VERSION "canboat-NMEA2000-curated"

NS_ :

BS_:

BU_: Vector__XXX
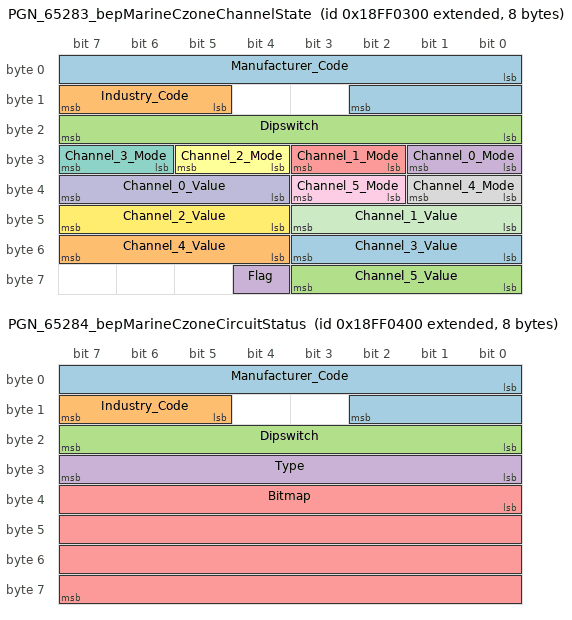
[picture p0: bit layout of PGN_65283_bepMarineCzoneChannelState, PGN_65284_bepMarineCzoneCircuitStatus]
BO_ 2566849280 PGN_65283_bepMarineCzoneChannelState: 8 Vector__XXX
 SG_ Manufacturer_Code : 0|11@1+ (1.0,0) [0|2047] "" Vector__XXX
 SG_ Industry_Code : 13|3@1+ (1.0,0) [0|7] "" Vector__XXX
 SG_ Dipswitch : 16|8@1+ (1.0,0) [0|255] "" Vector__XXX
 SG_ Channel_0_Mode : 24|2@1+ (1.0,0) [0|3] "" Vector__XXX
 SG_ Channel_1_Mode : 26|2@1+ (1.0,0) [0|3] "" Vector__XXX
 SG_ Channel_2_Mode : 28|2@1+ (1.0,0) [0|3] "" Vector__XXX
 SG_ Channel_3_Mode : 30|2@1+ (1.0,0) [0|3] "" Vector__XXX
 SG_ Channel_4_Mode : 32|2@1+ (1.0,0) [0|3] "" Vector__XXX
 SG_ Channel_5_Mode : 34|2@1+ (1.0,0) [0|3] "" Vector__XXX
 SG_ Channel_0_Value : 36|4@1+ (1.0,0) [0|15] "" Vector__XXX
 SG_ Channel_1_Value : 40|4@1+ (1.0,0) [0|15] "" Vector__XXX
 SG_ Channel_2_Value : 44|4@1+ (1.0,0) [0|15] "" Vector__XXX
 SG_ Channel_3_Value : 48|4@1+ (1.0,0) [0|15] "" Vector__XXX
 SG_ Channel_4_Value : 52|4@1+ (1.0,0) [0|15] "" Vector__XXX
 SG_ Channel_5_Value : 56|4@1+ (1.0,0) [0|15] "" Vector__XXX
 SG_ Flag : 60|1@1+ (1.0,0) [0|1] "" Vector__XXX

BO_ 2566849536 PGN_65284_bepMarineCzoneCircuitStatus: 8 Vector__XXX
 SG_ Manufacturer_Code : 0|11@1+ (1.0,0) [0|2047] "" Vector__XXX
 SG_ Industry_Code : 13|3@1+ (1.0,0) [0|7] "" Vector__XXX
 SG_ Dipswitch : 16|8@1+ (1.0,0) [0|255] "" Vector__XXX
 SG_ Type : 24|8@1+ (1.0,0) [0|255] "" Vector__XXX
 SG_ Bitmap : 32|32@1+ (1.0,0) [0|4294967295] "" Vector__XXX

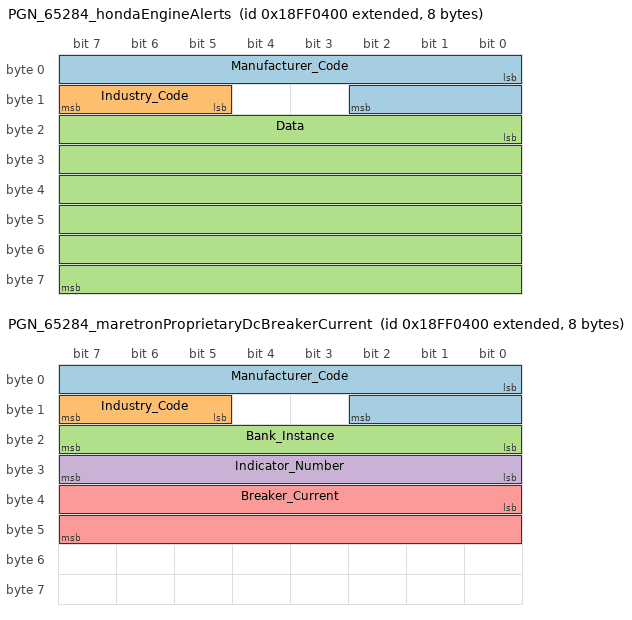
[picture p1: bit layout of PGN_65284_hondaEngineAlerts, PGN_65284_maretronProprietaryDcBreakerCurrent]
BO_ 2566849536 PGN_65284_hondaEngineAlerts: 8 Vector__XXX
 SG_ Manufacturer_Code : 0|11@1+ (1.0,0) [0|2047] "" Vector__XXX
 SG_ Industry_Code : 13|3@1+ (1.0,0) [0|7] "" Vector__XXX
 SG_ Data : 16|48@1+ (1.0,0) [0|281474976710655] "" Vector__XXX

BO_ 2566849536 PGN_65284_maretronProprietaryDcBreakerCurrent: 8 Vector__XXX
 SG_ Manufacturer_Code : 0|11@1+ (1.0,0) [0|2047] "" Vector__XXX
 SG_ Industry_Code : 13|3@1+ (1.0,0) [0|7] "" Vector__XXX
 SG_ Bank_Instance : 16|8@1+ (1.0,0) [0|255] "" Vector__XXX
 SG_ Indicator_Number : 24|8@1+ (1.0,0) [0|255] "" Vector__XXX
 SG_ Breaker_Current : 32|16@1- (0.1,0) [-3276.8|3276.7000000000003] "" Vector__XXX

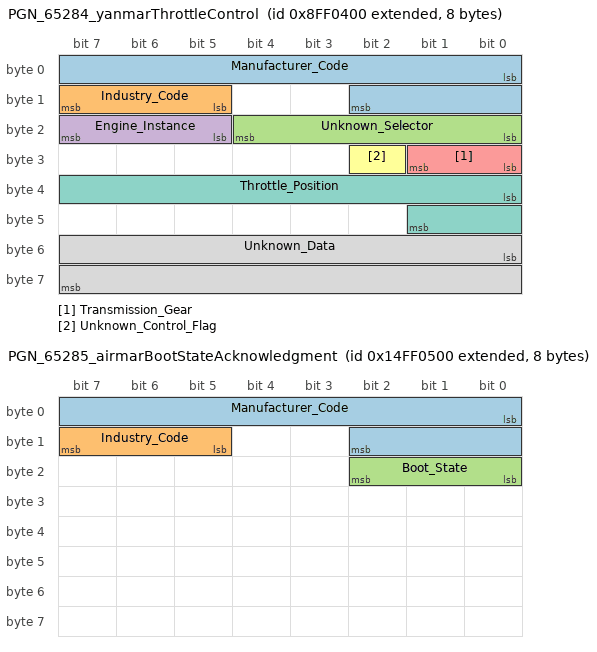
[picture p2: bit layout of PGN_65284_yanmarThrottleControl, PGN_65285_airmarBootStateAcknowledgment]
BO_ 2298414080 PGN_65284_yanmarThrottleControl: 8 Vector__XXX
 SG_ Manufacturer_Code : 0|11@1+ (1.0,0) [0|2047] "" Vector__XXX
 SG_ Industry_Code : 13|3@1+ (1.0,0) [0|7] "" Vector__XXX
 SG_ Unknown_Selector : 16|5@1+ (1.0,0) [0|31] "" Vector__XXX
 SG_ Engine_Instance : 21|3@1+ (1.0,0) [0|7] "" Vector__XXX
 SG_ Transmission_Gear : 24|2@1+ (1.0,0) [0|3] "" Vector__XXX
 SG_ Unknown_Control_Flag : 26|1@1+ (1.0,0) [0|1] "" Vector__XXX
 SG_ Throttle_Position : 32|10@1+ (0.1,0) [0.0|102.30000000000001] "%" Vector__XXX
 SG_ Unknown_Data : 48|16@1+ (1.0,0) [0|65535] "" Vector__XXX

BO_ 2499740928 PGN_65285_airmarBootStateAcknowledgment: 8 Vector__XXX
 SG_ Manufacturer_Code : 0|11@1+ (1.0,0) [0|2047] "" Vector__XXX
 SG_ Industry_Code : 13|3@1+ (1.0,0) [0|7] "" Vector__XXX
 SG_ Boot_State : 16|3@1+ (1.0,0) [0|7] "" Vector__XXX

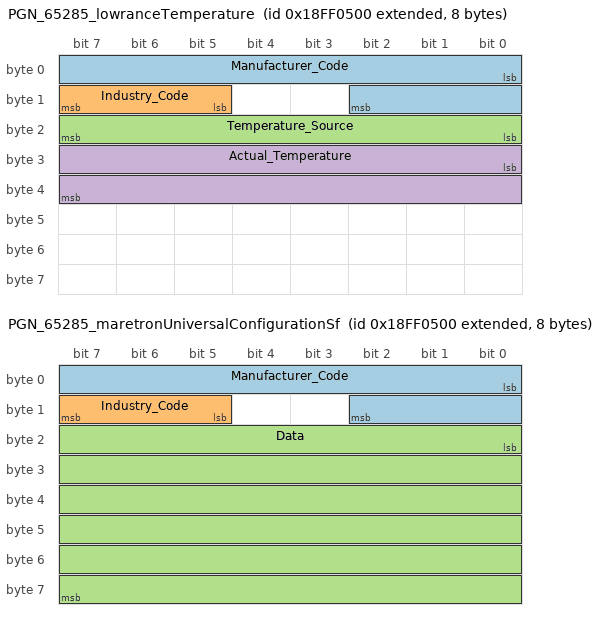
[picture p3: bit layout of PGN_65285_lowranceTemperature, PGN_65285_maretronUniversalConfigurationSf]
BO_ 2566849792 PGN_65285_lowranceTemperature: 8 Vector__XXX
 SG_ Manufacturer_Code : 0|11@1+ (1.0,0) [0|2047] "" Vector__XXX
 SG_ Industry_Code : 13|3@1+ (1.0,0) [0|7] "" Vector__XXX
 SG_ Temperature_Source : 16|8@1+ (1.0,0) [0|255] "" Vector__XXX
 SG_ Actual_Temperature : 24|16@1+ (0.01,0) [0.0|655.35] "" Vector__XXX

BO_ 2566849792 PGN_65285_maretronUniversalConfigurationSf: 8 Vector__XXX
 SG_ Manufacturer_Code : 0|11@1+ (1.0,0) [0|2047] "" Vector__XXX
 SG_ Industry_Code : 13|3@1+ (1.0,0) [0|7] "" Vector__XXX
 SG_ Data : 16|48@1+ (1.0,0) [0|281474976710655] "" Vector__XXX

BO_ 2566850048 PGN_65286_airmarBootStateRequest: 8 Vector__XXX
 SG_ Manufacturer_Code : 0|11@1+ (1.0,0) [0|2047] "" Vector__XXX
 SG_ Industry_Code : 13|3@1+ (1.0,0) [0|7] "" Vector__XXX

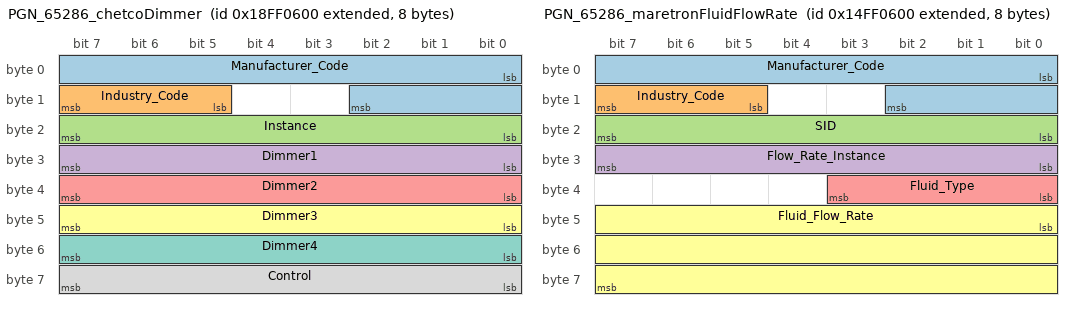
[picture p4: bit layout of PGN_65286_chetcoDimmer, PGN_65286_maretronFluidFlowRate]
BO_ 2566850048 PGN_65286_chetcoDimmer: 8 Vector__XXX
 SG_ Manufacturer_Code : 0|11@1+ (1.0,0) [0|2047] "" Vector__XXX
 SG_ Industry_Code : 13|3@1+ (1.0,0) [0|7] "" Vector__XXX
 SG_ Instance : 16|8@1+ (1.0,0) [0|255] "" Vector__XXX
 SG_ Dimmer1 : 24|8@1+ (1.0,0) [0|255] "" Vector__XXX
 SG_ Dimmer2 : 32|8@1+ (1.0,0) [0|255] "" Vector__XXX
 SG_ Dimmer3 : 40|8@1+ (1.0,0) [0|255] "" Vector__XXX
 SG_ Dimmer4 : 48|8@1+ (1.0,0) [0|255] "" Vector__XXX
 SG_ Control : 56|8@1+ (1.0,0) [0|255] "" Vector__XXX

BO_ 2499741184 PGN_65286_maretronFluidFlowRate: 8 Vector__XXX
 SG_ Manufacturer_Code : 0|11@1+ (1.0,0) [0|2047] "" Vector__XXX
 SG_ Industry_Code : 13|3@1+ (1.0,0) [0|7] "" Vector__XXX
 SG_ SID : 16|8@1+ (1.0,0) [0|255] "" Vector__XXX
 SG_ Flow_Rate_Instance : 24|8@1+ (1.0,0) [0|255] "" Vector__XXX
 SG_ Fluid_Type : 32|4@1+ (1.0,0) [0|15] "" Vector__XXX
 SG_ Fluid_Flow_Rate : 40|24@1- (0.0001,0) [-838.8608|838.8607000000001] "" Vector__XXX

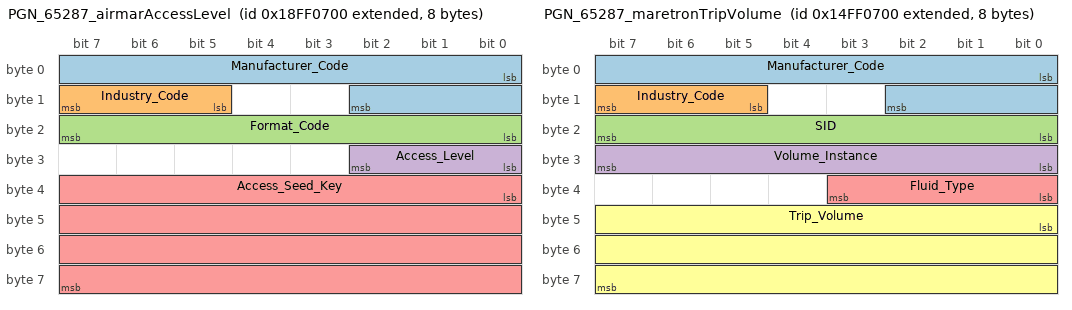
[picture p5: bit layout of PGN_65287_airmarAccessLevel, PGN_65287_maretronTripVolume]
BO_ 2566850304 PGN_65287_airmarAccessLevel: 8 Vector__XXX
 SG_ Manufacturer_Code : 0|11@1+ (1.0,0) [0|2047] "" Vector__XXX
 SG_ Industry_Code : 13|3@1+ (1.0,0) [0|7] "" Vector__XXX
 SG_ Format_Code : 16|8@1+ (1.0,0) [0|255] "" Vector__XXX
 SG_ Access_Level : 24|3@1+ (1.0,0) [0|7] "" Vector__XXX
 SG_ Access_Seed_Key : 32|32@1+ (1.0,0) [0|4294967295] "" Vector__XXX

BO_ 2499741440 PGN_65287_maretronTripVolume: 8 Vector__XXX
 SG_ Manufacturer_Code : 0|11@1+ (1.0,0) [0|2047] "" Vector__XXX
 SG_ Industry_Code : 13|3@1+ (1.0,0) [0|7] "" Vector__XXX
 SG_ SID : 16|8@1+ (1.0,0) [0|255] "" Vector__XXX
 SG_ Volume_Instance : 24|8@1+ (1.0,0) [0|255] "" Vector__XXX
 SG_ Fluid_Type : 32|4@1+ (1.0,0) [0|15] "" Vector__XXX
 SG_ Trip_Volume : 40|24@1+ (0.001,0) [0.0|16777.215] "" Vector__XXX

BO_ 2566850304 PGN_65287_simnetConfigureTemperatureSensor: 8 Vector__XXX
 SG_ Manufacturer_Code : 0|11@1+ (1.0,0) [0|2047] "" Vector__XXX
 SG_ Industry_Code : 13|3@1+ (1.0,0) [0|7] "" Vector__XXX

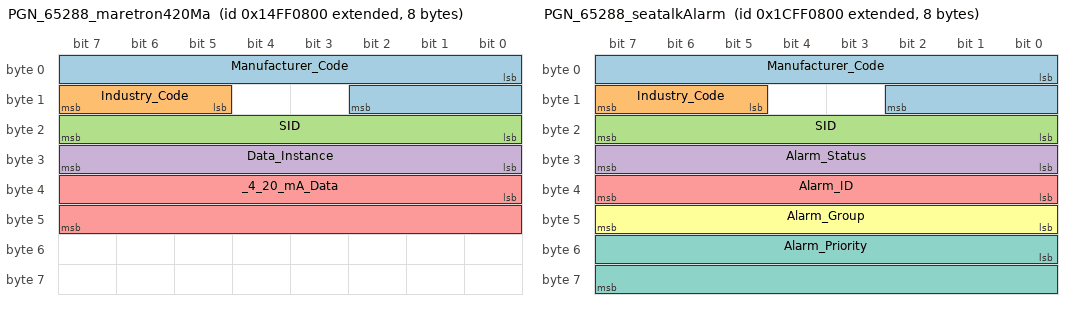
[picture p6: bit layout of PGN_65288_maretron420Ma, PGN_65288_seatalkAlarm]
BO_ 2499741696 PGN_65288_maretron420Ma: 8 Vector__XXX
 SG_ Manufacturer_Code : 0|11@1+ (1.0,0) [0|2047] "" Vector__XXX
 SG_ Industry_Code : 13|3@1+ (1.0,0) [0|7] "" Vector__XXX
 SG_ SID : 16|8@1+ (1.0,0) [0|255] "" Vector__XXX
 SG_ Data_Instance : 24|8@1+ (1.0,0) [0|255] "" Vector__XXX
 SG_ _4_20_mA_Data : 32|16@1+ (1.0,0) [0|65535] "" Vector__XXX

BO_ 2633959424 PGN_65288_seatalkAlarm: 8 Vector__XXX
 SG_ Manufacturer_Code : 0|11@1+ (1.0,0) [0|2047] "" Vector__XXX
 SG_ Industry_Code : 13|3@1+ (1.0,0) [0|7] "" Vector__XXX
 SG_ SID : 16|8@1+ (1.0,0) [0|255] "" Vector__XXX
 SG_ Alarm_Status : 24|8@1+ (1.0,0) [0|255] "" Vector__XXX
 SG_ Alarm_ID : 32|8@1+ (1.0,0) [0|255] "" Vector__XXX
 SG_ Alarm_Group : 40|8@1+ (1.0,0) [0|255] "" Vector__XXX
 SG_ Alarm_Priority : 48|16@1+ (1.0,0) [0|65535] "" Vector__XXX

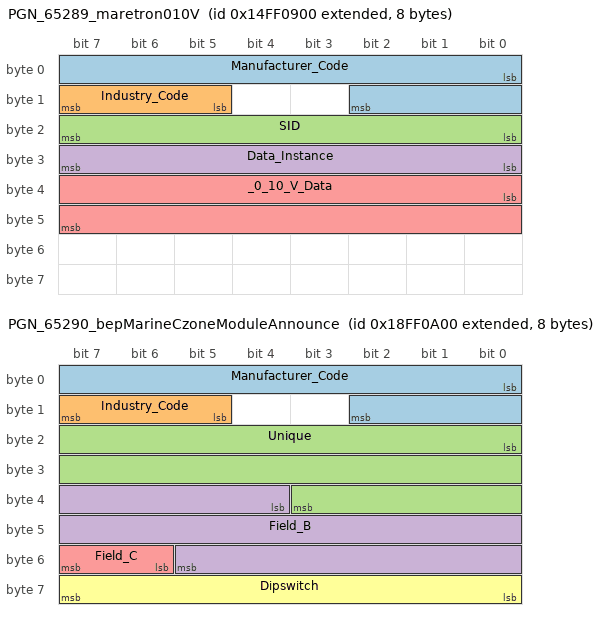
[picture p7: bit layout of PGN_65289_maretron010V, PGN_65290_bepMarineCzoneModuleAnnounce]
BO_ 2499741952 PGN_65289_maretron010V: 8 Vector__XXX
 SG_ Manufacturer_Code : 0|11@1+ (1.0,0) [0|2047] "" Vector__XXX
 SG_ Industry_Code : 13|3@1+ (1.0,0) [0|7] "" Vector__XXX
 SG_ SID : 16|8@1+ (1.0,0) [0|255] "" Vector__XXX
 SG_ Data_Instance : 24|8@1+ (1.0,0) [0|255] "" Vector__XXX
 SG_ _0_10_V_Data : 32|16@1+ (0.000244140625,0) [0.0|15.999755859375] "" Vector__XXX

BO_ 2566850816 PGN_65289_simnetTrimTabSensorCalibration: 8 Vector__XXX
 SG_ Manufacturer_Code : 0|11@1+ (1.0,0) [0|2047] "" Vector__XXX
 SG_ Industry_Code : 13|3@1+ (1.0,0) [0|7] "" Vector__XXX

BO_ 2566851072 PGN_65290_bepMarineCzoneModuleAnnounce: 8 Vector__XXX
 SG_ Manufacturer_Code : 0|11@1+ (1.0,0) [0|2047] "" Vector__XXX
 SG_ Industry_Code : 13|3@1+ (1.0,0) [0|7] "" Vector__XXX
 SG_ Unique : 16|20@1+ (1.0,0) [0|1048575] "" Vector__XXX
 SG_ Field_B : 36|18@1+ (1.0,0) [0|262143] "" Vector__XXX
 SG_ Field_C : 54|2@1+ (1.0,0) [0|3] "" Vector__XXX
 SG_ Dipswitch : 56|8@1+ (1.0,0) [0|255] "" Vector__XXX

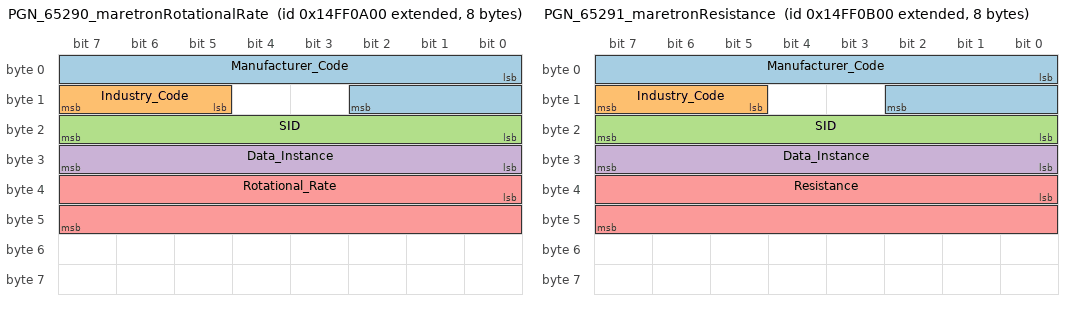
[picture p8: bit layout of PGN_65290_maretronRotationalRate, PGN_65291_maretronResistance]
BO_ 2499742208 PGN_65290_maretronRotationalRate: 8 Vector__XXX
 SG_ Manufacturer_Code : 0|11@1+ (1.0,0) [0|2047] "" Vector__XXX
 SG_ Industry_Code : 13|3@1+ (1.0,0) [0|7] "" Vector__XXX
 SG_ SID : 16|8@1+ (1.0,0) [0|255] "" Vector__XXX
 SG_ Data_Instance : 24|8@1+ (1.0,0) [0|255] "" Vector__XXX
 SG_ Rotational_Rate : 32|16@1- (0.25,0) [-8192.0|8191.75] "" Vector__XXX

BO_ 2566851072 PGN_65290_simnetPaddleWheelSpeedConfiguration: 8 Vector__XXX
 SG_ Manufacturer_Code : 0|11@1+ (1.0,0) [0|2047] "" Vector__XXX
 SG_ Industry_Code : 13|3@1+ (1.0,0) [0|7] "" Vector__XXX

BO_ 2499742464 PGN_65291_maretronResistance: 8 Vector__XXX
 SG_ Manufacturer_Code : 0|11@1+ (1.0,0) [0|2047] "" Vector__XXX
 SG_ Industry_Code : 13|3@1+ (1.0,0) [0|7] "" Vector__XXX
 SG_ SID : 16|8@1+ (1.0,0) [0|255] "" Vector__XXX
 SG_ Data_Instance : 24|8@1+ (1.0,0) [0|255] "" Vector__XXX
 SG_ Resistance : 32|16@1+ (0.01,0) [0.0|655.35] "" Vector__XXX

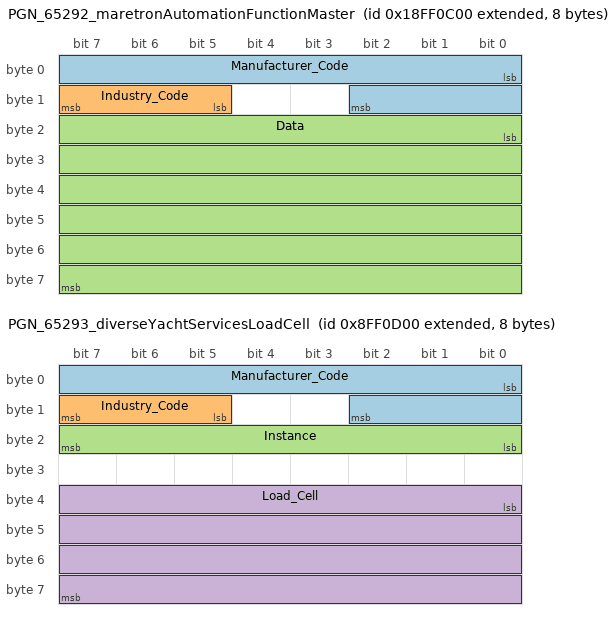
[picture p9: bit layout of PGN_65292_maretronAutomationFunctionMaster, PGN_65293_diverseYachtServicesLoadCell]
BO_ 2566851584 PGN_65292_maretronAutomationFunctionMaster: 8 Vector__XXX
 SG_ Manufacturer_Code : 0|11@1+ (1.0,0) [0|2047] "" Vector__XXX
 SG_ Industry_Code : 13|3@1+ (1.0,0) [0|7] "" Vector__XXX
 SG_ Data : 16|48@1+ (1.0,0) [0|281474976710655] "" Vector__XXX

BO_ 2566851584 PGN_65292_simnetClearFluidLevelWarnings: 8 Vector__XXX
 SG_ Manufacturer_Code : 0|11@1+ (1.0,0) [0|2047] "" Vector__XXX
 SG_ Industry_Code : 13|3@1+ (1.0,0) [0|7] "" Vector__XXX

BO_ 2298416384 PGN_65293_diverseYachtServicesLoadCell: 8 Vector__XXX
 SG_ Manufacturer_Code : 0|11@1+ (1.0,0) [0|2047] "" Vector__XXX
 SG_ Industry_Code : 13|3@1+ (1.0,0) [0|7] "" Vector__XXX
 SG_ Instance : 16|8@1+ (1.0,0) [0|255] "" Vector__XXX
 SG_ Load_Cell : 32|32@1+ (1.0,0) [0|4294967295] "" Vector__XXX

CM_ BO_ 2566849280 "NMEA2000: PGN 65283 - BEP Marine: CZone Channel State (type: Single)";
CM_ BO_ 2566849536 "NMEA2000: PGN 65284 - BEP Marine: CZone Circuit Status (type: Single)";
CM_ BO_ 2566849536 "NMEA2000: PGN 65284 - Honda: Engine Alerts (type: Single)";
CM_ BO_ 2566849536 "NMEA2000: PGN 65284 - Maretron: Proprietary DC Breaker Current (type: Single)";
CM_ BO_ 2298414080 "NMEA2000: PGN 65284 - Yanmar: Throttle Control (type: Single)";
CM_ BO_ 2499740928 "NMEA2000: PGN 65285 - Airmar: Boot State Acknowledgment (type: Single)";
CM_ BO_ 2566849792 "NMEA2000: PGN 65285 - Lowrance: Temperature (type: Single)";
CM_ BO_ 2566849792 "NMEA2000: PGN 65285 - Maretron: Universal Configuration SF (type: Single)";
CM_ BO_ 2566850048 "NMEA2000: PGN 65286 - Airmar: Boot State Request (type: Single)";
CM_ BO_ 2566850048 "NMEA2000: PGN 65286 - Chetco: Dimmer (type: Single)";
CM_ BO_ 2499741184 "NMEA2000: PGN 65286 - Maretron: Fluid Flow Rate (type: Single)";
CM_ BO_ 2566850304 "NMEA2000: PGN 65287 - Airmar: Access Level (type: Single)";
CM_ BO_ 2499741440 "NMEA2000: PGN 65287 - Maretron: Trip Volume (type: Single)";
CM_ BO_ 2566850304 "NMEA2000: PGN 65287 - Simnet: Configure Temperature Sensor (type: Single)";
CM_ BO_ 2499741696 "NMEA2000: PGN 65288 - Maretron: 4-20 mA (type: Single)";
CM_ BO_ 2633959424 "NMEA2000: PGN 65288 - Seatalk: Alarm (type: Single)";
CM_ BO_ 2499741952 "NMEA2000: PGN 65289 - Maretron: 0-10 V (type: Single)";
CM_ BO_ 2566850816 "NMEA2000: PGN 65289 - Simnet: Trim Tab Sensor Calibration (type: Single)";
CM_ BO_ 2566851072 "NMEA2000: PGN 65290 - BEP Marine: CZone Module Announce (type: Single)";
CM_ BO_ 2499742208 "NMEA2000: PGN 65290 - Maretron: Rotational Rate (type: Single)";
CM_ BO_ 2566851072 "NMEA2000: PGN 65290 - Simnet: Paddle Wheel Speed Configuration (type: Single)";
CM_ BO_ 2499742464 "NMEA2000: PGN 65291 - Maretron: Resistance (type: Single)";
CM_ BO_ 2566851584 "NMEA2000: PGN 65292 - Maretron: Automation Function Master (type: Single)";
CM_ BO_ 2566851584 "NMEA2000: PGN 65292 - Simnet: Clear Fluid Level Warnings (type: Single)";
CM_ BO_ 2298416384 "NMEA2000: PGN 65293 - Diverse Yacht Services: Load Cell (type: Single)";
CM_ SG_ 2566849280 Manufacturer_Code "BEP Marine; canboat type: LOOKUP";
CM_ SG_ 2566849280 Industry_Code "Marine Industry; canboat type: LOOKUP";
CM_ SG_ 2566849280 Dipswitch "canboat type: UINT8";
CM_ SG_ 2566849280 Channel_0_Mode "Likely circuit type / fault state; per-bit semantics unverified; canboat type: UNSIGNED_INTEGER";
CM_ SG_ 2566849280 Channel_1_Mode "Likely circuit type / fault state; per-bit semantics unverified; canboat type: UNSIGNED_INTEGER";
CM_ SG_ 2566849280 Channel_2_Mode "Likely circuit type / fault state; per-bit semantics unverified; canboat type: UNSIGNED_INTEGER";
CM_ SG_ 2566849280 Channel_3_Mode "Likely circuit type / fault state; per-bit semantics unverified; canboat type: UNSIGNED_INTEGER";
CM_ SG_ 2566849280 Channel_4_Mode "Likely circuit type / fault state; per-bit semantics unverified; canboat type: UNSIGNED_INTEGER";
CM_ SG_ 2566849280 Channel_5_Mode "Likely circuit type / fault state; per-bit semantics unverified; canboat type: UNSIGNED_INTEGER";
CM_ SG_ 2566849280 Channel_0_Value "4-bit per-channel value; likely dim level (0..15) or state code; canboat type: UNSIGNED_INTEGER";
CM_ SG_ 2566849280 Channel_1_Value "4-bit per-channel value; likely dim level (0..15) or state code; canboat type: UNSIGNED_INTEGER";
CM_ SG_ 2566849280 Channel_2_Value "4-bit per-channel value; likely dim level (0..15) or state code; canboat type: UNSIGNED_INTEGER";
CM_ SG_ 2566849280 Channel_3_Value "4-bit per-channel value; likely dim level (0..15) or state code; canboat type: UNSIGNED_INTEGER";
CM_ SG_ 2566849280 Channel_4_Value "4-bit per-channel value; likely dim level (0..15) or state code; canboat type: UNSIGNED_INTEGER";
CM_ SG_ 2566849280 Channel_5_Value "4-bit per-channel value; likely dim level (0..15) or state code; canboat type: UNSIGNED_INTEGER";
CM_ SG_ 2566849280 Flag "Single boolean flag; purpose unverified; canboat type: UNSIGNED_INTEGER";
CM_ SG_ 2566849536 Manufacturer_Code "BEP Marine; canboat type: LOOKUP";
CM_ SG_ 2566849536 Industry_Code "Marine Industry; canboat type: LOOKUP";
CM_ SG_ 2566849536 Dipswitch "canboat type: UINT8";
CM_ SG_ 2566849536 Type "Observed 0x0F for circuit-state reports; canboat type: UINT8";
CM_ SG_ 2566849536 Bitmap "32-bit bitmap of circuits, LSB-first; bit n set => circuit at slot n is ON; canboat type: BINARY";
CM_ SG_ 2566849536 Manufacturer_Code "Honda Motor; canboat type: LOOKUP";
CM_ SG_ 2566849536 Industry_Code "Marine Industry; canboat type: LOOKUP";
CM_ SG_ 2566849536 Data "canboat type: BINARY";
CM_ SG_ 2566849536 Manufacturer_Code "Maretron; canboat type: LOOKUP";
CM_ SG_ 2566849536 Industry_Code "Marine Industry; canboat type: LOOKUP";
CM_ SG_ 2566849536 Bank_Instance "canboat type: UINT8";
CM_ SG_ 2566849536 Indicator_Number "canboat type: UINT8";
CM_ SG_ 2566849536 Breaker_Current "canboat type: CURRENT_FIX16_DA";
CM_ SG_ 2298414080 Manufacturer_Code "Yanmar Marine; canboat type: LOOKUP";
CM_ SG_ 2298414080 Industry_Code "Marine Industry; canboat type: LOOKUP";
CM_ SG_ 2298414080 Unknown_Selector "Observed as 1; the individual bit semantics are not yet known.; canboat type: UNSIGNED_INTEGER";
CM_ SG_ 2298414080 Engine_Instance "Uses the standard NMEA 2000 engine-instance values; observed as 0 for port and 1 for starboard.; canboat type: LOOKUP";
CM_ SG_ 2298414080 Transmission_Gear "Observed as Forward, Neutral, and Reverse for the selected engine channel.; canboat type: LOOKUP";
CM_ SG_ 2298414080 Unknown_Control_Flag "Observed as 0 during the gear-transition capture and 1 in earlier underway throttle captures.; canboat type: UNSIGNED_INTEGER";
CM_ SG_ 2298414080 Throttle_Position "Observed control-lever position with 0.1 percent resolution.; canboat type: UNSIGNED_INTEGER";
CM_ SG_ 2298414080 Unknown_Data "Observed as 0x64FF.; canboat type: BINARY";
CM_ SG_ 2499740928 Manufacturer_Code "Airmar; canboat type: LOOKUP";
CM_ SG_ 2499740928 Industry_Code "Marine Industry; canboat type: LOOKUP";
CM_ SG_ 2499740928 Boot_State "canboat type: LOOKUP";
CM_ SG_ 2566849792 Manufacturer_Code "Lowrance; canboat type: LOOKUP";
CM_ SG_ 2566849792 Industry_Code "Marine Industry; canboat type: LOOKUP";
CM_ SG_ 2566849792 Temperature_Source "canboat type: LOOKUP";
CM_ SG_ 2566849792 Actual_Temperature "canboat type: TEMPERATURE";
CM_ SG_ 2566849792 Manufacturer_Code "Maretron; canboat type: LOOKUP";
CM_ SG_ 2566849792 Industry_Code "Marine Industry; canboat type: LOOKUP";
CM_ SG_ 2566849792 Data "canboat type: BINARY";
CM_ SG_ 2566850048 Manufacturer_Code "Airmar; canboat type: LOOKUP";
CM_ SG_ 2566850048 Industry_Code "Marine Industry; canboat type: LOOKUP";
CM_ SG_ 2566850048 Manufacturer_Code "Chetco; canboat type: LOOKUP";
CM_ SG_ 2566850048 Industry_Code "Marine Industry; canboat type: LOOKUP";
CM_ SG_ 2566850048 Instance "canboat type: UINT8";
CM_ SG_ 2566850048 Dimmer1 "canboat type: UINT8";
CM_ SG_ 2566850048 Dimmer2 "canboat type: UINT8";
CM_ SG_ 2566850048 Dimmer3 "canboat type: UINT8";
CM_ SG_ 2566850048 Dimmer4 "canboat type: UINT8";
CM_ SG_ 2566850048 Control "canboat type: UINT8";
CM_ SG_ 2499741184 Manufacturer_Code "Maretron; canboat type: LOOKUP";
CM_ SG_ 2499741184 Industry_Code "Marine Industry; canboat type: LOOKUP";
CM_ SG_ 2499741184 SID "canboat type: UINT8";
CM_ SG_ 2499741184 Flow_Rate_Instance "canboat type: UINT8";
CM_ SG_ 2499741184 Fluid_Type "canboat type: LOOKUP";
CM_ SG_ 2499741184 Fluid_Flow_Rate "canboat type: FIX24";
CM_ SG_ 2566850304 Manufacturer_Code "Airmar; canboat type: LOOKUP";
CM_ SG_ 2566850304 Industry_Code "Marine Industry; canboat type: LOOKUP";
CM_ SG_ 2566850304 Format_Code "canboat type: UINT8";
CM_ SG_ 2566850304 Access_Level "canboat type: LOOKUP";
CM_ SG_ 2566850304 Access_Seed_Key "When transmitted, it provides a seed for an unlock operation. It is used to provide the key during PGN 126208.; canboat type: UINT32";
CM_ SG_ 2499741440 Manufacturer_Code "Maretron; canboat type: LOOKUP";
CM_ SG_ 2499741440 Industry_Code "Marine Industry; canboat type: LOOKUP";
CM_ SG_ 2499741440 SID "canboat type: UINT8";
CM_ SG_ 2499741440 Volume_Instance "canboat type: UINT8";
CM_ SG_ 2499741440 Fluid_Type "canboat type: LOOKUP";
CM_ SG_ 2499741440 Trip_Volume "canboat type: UINT24";
CM_ SG_ 2566850304 Manufacturer_Code "Simrad; canboat type: LOOKUP";
CM_ SG_ 2566850304 Industry_Code "Marine Industry; canboat type: LOOKUP";
CM_ SG_ 2499741696 Manufacturer_Code "Maretron; canboat type: LOOKUP";
CM_ SG_ 2499741696 Industry_Code "Marine Industry; canboat type: LOOKUP";
CM_ SG_ 2499741696 SID "canboat type: UINT8";
CM_ SG_ 2499741696 Data_Instance "canboat type: UINT8";
CM_ SG_ 2499741696 _4_20_mA_Data "canboat type: UINT16";
CM_ SG_ 2633959424 Manufacturer_Code "Raymarine; canboat type: LOOKUP";
CM_ SG_ 2633959424 Industry_Code "Marine Industry; canboat type: LOOKUP";
CM_ SG_ 2633959424 SID "canboat type: UINT8";
CM_ SG_ 2633959424 Alarm_Status "canboat type: LOOKUP";
CM_ SG_ 2633959424 Alarm_ID "canboat type: LOOKUP";
CM_ SG_ 2633959424 Alarm_Group "canboat type: LOOKUP";
CM_ SG_ 2633959424 Alarm_Priority "canboat type: BINARY";
CM_ SG_ 2499741952 Manufacturer_Code "Maretron; canboat type: LOOKUP";
CM_ SG_ 2499741952 Industry_Code "Marine Industry; canboat type: LOOKUP";
CM_ SG_ 2499741952 SID "canboat type: UINT8";
CM_ SG_ 2499741952 Data_Instance "canboat type: UINT8";
CM_ SG_ 2499741952 _0_10_V_Data "canboat type: UINT16";
CM_ SG_ 2566850816 Manufacturer_Code "Simrad; canboat type: LOOKUP";
CM_ SG_ 2566850816 Industry_Code "Marine Industry; canboat type: LOOKUP";
CM_ SG_ 2566851072 Manufacturer_Code "BEP Marine; canboat type: LOOKUP";
CM_ SG_ 2566851072 Industry_Code "Marine Industry; canboat type: LOOKUP";
CM_ SG_ 2566851072 Unique "Stable identifier set by the module; opaque to the plotter; canboat type: UNSIGNED_INTEGER";
CM_ SG_ 2566851072 Field_B "Purpose unknown; observed = 0 in YDAB-01; canboat type: UNSIGNED_INTEGER";
CM_ SG_ 2566851072 Field_C "Purpose unknown; observed = 0 in YDAB-01; canboat type: UNSIGNED_INTEGER";
CM_ SG_ 2566851072 Dipswitch "8-bit dipswitch this module is claiming; canboat type: UINT8";
CM_ SG_ 2499742208 Manufacturer_Code "Maretron; canboat type: LOOKUP";
CM_ SG_ 2499742208 Industry_Code "Marine Industry; canboat type: LOOKUP";
CM_ SG_ 2499742208 SID "canboat type: UINT8";
CM_ SG_ 2499742208 Data_Instance "canboat type: UINT8";
CM_ SG_ 2499742208 Rotational_Rate "canboat type: INT16";
CM_ SG_ 2566851072 Manufacturer_Code "Simrad; canboat type: LOOKUP";
CM_ SG_ 2566851072 Industry_Code "Marine Industry; canboat type: LOOKUP";
CM_ SG_ 2499742464 Manufacturer_Code "Maretron; canboat type: LOOKUP";
CM_ SG_ 2499742464 Industry_Code "Marine Industry; canboat type: LOOKUP";
CM_ SG_ 2499742464 SID "canboat type: UINT8";
CM_ SG_ 2499742464 Data_Instance "canboat type: UINT8";
CM_ SG_ 2499742464 Resistance "canboat type: DILUTION_OF_PRECISION_UFIX16";
CM_ SG_ 2566851584 Manufacturer_Code "Maretron; canboat type: LOOKUP";
CM_ SG_ 2566851584 Industry_Code "Marine Industry; canboat type: LOOKUP";
CM_ SG_ 2566851584 Data "canboat type: BINARY";
CM_ SG_ 2566851584 Manufacturer_Code "Simrad; canboat type: LOOKUP";
CM_ SG_ 2566851584 Industry_Code "Marine Industry; canboat type: LOOKUP";
CM_ SG_ 2298416384 Manufacturer_Code "Diverse Yacht Services; canboat type: LOOKUP";
CM_ SG_ 2298416384 Industry_Code "Marine Industry; canboat type: LOOKUP";
CM_ SG_ 2298416384 Instance "canboat type: UINT8";
CM_ SG_ 2298416384 Load_Cell "canboat type: UINT32";
VAL_ 2566849280 Manufacturer_Code 69 "ARKS Enterprises" 78 "FW Murphy/Enovation Controls" 80 "Twin Disc" 85 "Kohler Power Systems" 88 "Hemisphere GPS" 135 "Airmar" 137 "Maretron" 140 "Lowrance" 144 "Mercury Marine" 147 "Nautibus Electronic" 148 "Blue Water Data" 154 "Westerbeke" 157 "ISSPRO" 161 "Offshore Systems (UK)" 163 "Evinrude/BRP" 165 "CPAC Systems" 168 "Xantrex Technology" 169 "Marlin Technologies" 172 "Yanmar Marine" 174 "Volvo Penta" 176 "Carling Technologies Inc. (Moritz Aerospace)" 185 "Beede Instruments" 192 "Floscan Instrument" 193 "Nobeltec" 198 "Mystic Valley Communications" 199 "Actia" 201 "Disenos Y Technologia" 211 "Digital Switching Systems" 215 "Xintex/Atena" 224 "EMMI NETWORK" 228 "ZF" 229 "Garmin" 233 "Yacht Monitoring Solutions" 235 "Sailormade Marine Telemetry/Tetra Technology" 243 "Eride" 257 "Honda Motor" 272 "Groco" 273 "Actisense" 274 "Amphenol LTW Technology" 275 "Navico" 283 "Hamilton Jet" 285 "Sea Recovery" 286 "Coelmo SRL Italy" 295 "BEP Marine" 304 "Empir Bus" 305 "NovAtel" 306 "Sleipner Motor" 307 "MBW Technologies" 315 "ICOM" 328 "Qwerty" 329 "Dief" 341 "Boening Automationstechnologie" 345 "Korean Maritime University" 351 "Thrane and Thrane" 355 "Mastervolt" 356 "Fischer Panda Generators" 358 "Victron Energy" 370 "Rolls Royce Marine" 373 "Electronic Design" 374 "Northern Lights" 378 "Glendinning" 381 "B & G" 384 "Rose Point Navigation Systems" 385 "Johnson Outdoors Marine Electronics Inc Geonav" 394 "Capi 2" 396 "Beyond Measure" 400 "Livorsi Marine" 404 "ComNav" 409 "Chetco" 419 "Fusion Electronics" 421 "Standard Horizon" 422 "True Heading" 426 "Egersund Marine Electronics" 427 "em-trak Marine Electronics" 431 "Tohatsu Co, JP" 437 "Digital Yacht" 438 "Comar Systems Limited" 440 "Cummins" 443 "VDO (aka Continental-Corporation)" 451 "Parker Hannifin aka Village Marine Tech" 459 "Alltek Marine Electronics" 460 "SAN GIORGIO S.E.I.N" 466 "Veethree Electronics & Marine" 470 "SI-TEX Marine Electronics" 471 "Sea Cross Marine" 475 "GME aka Standard Communications" 476 "Humminbird Marine Electronics" 478 "Ocean Sat" 481 "Chetco Digital Instruments" 493 "Watcheye" 499 "Lcj Capteurs" 502 "Attwood Marine" 503 "Naviop S.R.L." 504 "Vesper Marine" 510 "Marinesoft" 513 "Simarine" 517 "NoLand Engineering" 518 "Transas USA" 529 "National Instruments Korea" 530 "National Marine Electronics Association" 532 "Onwa Marine" 540 "Webasto" 571 "Marinecraft (South Korea)" 573 "McMurdo Group aka Orolia" 578 "Advansea" 579 "KVH" 580 "San Jose Technology" 583 "Yacht Control" 586 "Suzuki Motor" 591 "US Coast Guard" 595 "Ship Module aka Customware" 600 "Aquatic AV" 605 "Aventics" 606 "Intellian" 612 "SamwonIT" 614 "Arlt Tecnologies" 637 "Bavaria Yachts" 641 "Diverse Yacht Services" 644 "Wema U.S.A dba KUS" 658 "Shenzhen Jiuzhou Himunication" 688 "Rockford" 699 "Harman International" 704 "JL Audio" 708 "Lars Thrane" 715 "Autonnic" 717 "Yacht Devices" 734 "REAP Systems" 735 "AEM Performance Electronics" 739 "LxNav" 741 "Littelfuse, Inc (formerly Carling Technologies)" 743 "DaeMyung" 744 "Woosung" 748 "ISOTTA IFRA srl" 773 "Clarion US" 776 "HMI Systems" 777 "Ocean Signal" 778 "Seakeeper" 781 "Poly Planar" 785 "Fischer Panda DE" 795 "Broyda Industries" 796 "Canadian Automotive" 797 "Tides Marine" 798 "Lumishore" 799 "Still Water Designs and Audio" 802 "BJ Technologies (Beneteau)" 803 "Gill Sensors" 811 "Blue Water Desalination" 815 "FLIR" 824 "Undheim Systems" 826 "Lewmar" 838 "TeamSurv" 844 "Fell Marine" 847 "Oceanvolt" 862 "Prospec" 868 "Data Panel" 890 "L3 Technologies" 894 "Rhodan Marine Systems" 896 "Nexfour Solutions" 905 "ASA Electronics" 909 "Marines Co (South Korea)" 911 "Nautic-on" 917 "Sentinel" 929 "JL Marine Systems" 930 "Ecotronix" 944 "Zontisa Marine" 951 "EXOR International" 962 "Timbolier Industries" 963 "TJC Micro" 968 "Cox Powertrain" 969 "Blue Seas" 981 "Kobelt Manufacturing" 992 "Blue Ocean IOT" 997 "Xenta Systems" 999 "Signal K" 1004 "Ultraflex" 1008 "Lintest SmartBoat" 1011 "Soundmax" 1020 "Team Italia Marine (Onyx Marine Automation s.r.l)" 1021 "Entratech" 1022 "ITC" 1029 "The Marine Guardian" 1047 "Sonic" 1051 "ProNav" 1053 "Vetus Maxwell INC." 1056 "Lithium Pros" 1059 "Boatrax" 1062 "Marol Co ltd" 1065 "CALYPSO Instruments" 1066 "Spot Zero Water" 1069 "Lithionics Battery" 1070 "Quick-teck Electronics" 1075 "Uniden America" 1083 "Nauticoncept" 1084 "Shadow-Caster LED lighting" 1085 "Wet Sounds" 1088 "E-T-A Circuit Breakers" 1092 "Scheiber" 1100 "Smart Yachts International Limited" 1109 "Dockmate" 1114 "Bobs Machine" 1118 "L3Harris ASV" 1119 "Balmar" 1120 "Elettromedia" 1127 "Electromaax" 1140 "Across Oceans Systems" 1145 "Kiwi Yachting" 1150 "BSB Artificial Intelligence" 1151 "Orca Technologies" 1154 "TBS Electronics" 1158 "Technoton Electroics" 1160 "MG Energy Systems" 1169 "Sea Machine Robotics" 1171 "Vista Manufacturing" 1183 "Zipwake" 1186 "Sailmon" 1192 "Airmoniq Pro Kft" 1194 "Sierra Marine" 1200 "Xinuo Information Technology (Xiamen)" 1218 "Septentrio" 1233 "NKE Marine Electronics" 1238 "SuperTrack Aps" 1239 "Honda Electronics" 1245 "Raritan Engineering" 1249 "Integrated Power Solutions AG" 1260 "Interactive Technologies" 1283 "LTG-Tech" 1299 "Energy Solutions (UK)" 1300 "WATT Fuel Cell" 1302 "Pro Mainer" 1305 "Dragonfly Energy" 1306 "Koden Electronics" 1311 "Humphree" 1316 "Hinkley Yachts" 1317 "Global Marine Management GmbH (GMM)" 1320 "Triskel Marine" 1330 "Warwick Control Technologies" 1331 "Dolphin Charger" 1337 "Barnacle Systems" 1348 "Radian IoT" 1353 "Ocean LED Marine" 1359 "BluNav" 1361 "OVA (Nantong Saiyang Electronics Co., Ltd)" 1368 "RAD Propulsion" 1369 "Electric Yacht" 1372 "Elco Motor Yachts" 1384 "Tecnoseal Foundry S.r.l" 1385 "Pro Charging Systems" 1389 "EVEX" 1398 "Gobius Sensor Technology" 1403 "Arco Marine" 1408 "Lenco Marine" 1413 "Naocontrol" 1417 "Revatek" 1438 "Aeolionics" 1439 "PredictWind" 1440 "Egis Mobile Electric" 1445 "Starboard Yacht Group" 1446 "Roswell Marine" 1451 "ePropulsion (Guangdong ePropulsion Technology Ltd.)" 1452 "Micro-Air" 1453 "Vital Battery" 1458 "Ride Controller" 1460 "Tocaro Blue" 1461 "Vanquish Yachts" 1471 "FT Technologies" 1478 "Alps Alpine" 1481 "E-Force Marine" 1482 "CMC Marine" 1483 "Nanjing Sandemarine Information Technology" 1850 "Teleflex Marine (SeaStar Solutions)" 1851 "Raymarine" 1852 "Navionics" 1853 "Japan Radio" 1854 "Northstar Technologies" 1855 "Furuno" 1856 "Trimble" 1857 "Simrad" 1858 "Litton" 1859 "Kvasar" 1860 "MMP" 1861 "Vector Cantech" 1862 "Yamaha Marine" 1863 "Faria Instruments" ;
VAL_ 2566849280 Industry_Code 0 "Global" 1 "Highway" 2 "Agriculture" 3 "Construction" 4 "Marine Industry" 5 "Industrial" ;
VAL_ 2566849536 Manufacturer_Code 69 "ARKS Enterprises" 78 "FW Murphy/Enovation Controls" 80 "Twin Disc" 85 "Kohler Power Systems" 88 "Hemisphere GPS" 135 "Airmar" 137 "Maretron" 140 "Lowrance" 144 "Mercury Marine" 147 "Nautibus Electronic" 148 "Blue Water Data" 154 "Westerbeke" 157 "ISSPRO" 161 "Offshore Systems (UK)" 163 "Evinrude/BRP" 165 "CPAC Systems" 168 "Xantrex Technology" 169 "Marlin Technologies" 172 "Yanmar Marine" 174 "Volvo Penta" 176 "Carling Technologies Inc. (Moritz Aerospace)" 185 "Beede Instruments" 192 "Floscan Instrument" 193 "Nobeltec" 198 "Mystic Valley Communications" 199 "Actia" 201 "Disenos Y Technologia" 211 "Digital Switching Systems" 215 "Xintex/Atena" 224 "EMMI NETWORK" 228 "ZF" 229 "Garmin" 233 "Yacht Monitoring Solutions" 235 "Sailormade Marine Telemetry/Tetra Technology" 243 "Eride" 257 "Honda Motor" 272 "Groco" 273 "Actisense" 274 "Amphenol LTW Technology" 275 "Navico" 283 "Hamilton Jet" 285 "Sea Recovery" 286 "Coelmo SRL Italy" 295 "BEP Marine" 304 "Empir Bus" 305 "NovAtel" 306 "Sleipner Motor" 307 "MBW Technologies" 315 "ICOM" 328 "Qwerty" 329 "Dief" 341 "Boening Automationstechnologie" 345 "Korean Maritime University" 351 "Thrane and Thrane" 355 "Mastervolt" 356 "Fischer Panda Generators" 358 "Victron Energy" 370 "Rolls Royce Marine" 373 "Electronic Design" 374 "Northern Lights" 378 "Glendinning" 381 "B & G" 384 "Rose Point Navigation Systems" 385 "Johnson Outdoors Marine Electronics Inc Geonav" 394 "Capi 2" 396 "Beyond Measure" 400 "Livorsi Marine" 404 "ComNav" 409 "Chetco" 419 "Fusion Electronics" 421 "Standard Horizon" 422 "True Heading" 426 "Egersund Marine Electronics" 427 "em-trak Marine Electronics" 431 "Tohatsu Co, JP" 437 "Digital Yacht" 438 "Comar Systems Limited" 440 "Cummins" 443 "VDO (aka Continental-Corporation)" 451 "Parker Hannifin aka Village Marine Tech" 459 "Alltek Marine Electronics" 460 "SAN GIORGIO S.E.I.N" 466 "Veethree Electronics & Marine" 470 "SI-TEX Marine Electronics" 471 "Sea Cross Marine" 475 "GME aka Standard Communications" 476 "Humminbird Marine Electronics" 478 "Ocean Sat" 481 "Chetco Digital Instruments" 493 "Watcheye" 499 "Lcj Capteurs" 502 "Attwood Marine" 503 "Naviop S.R.L." 504 "Vesper Marine" 510 "Marinesoft" 513 "Simarine" 517 "NoLand Engineering" 518 "Transas USA" 529 "National Instruments Korea" 530 "National Marine Electronics Association" 532 "Onwa Marine" 540 "Webasto" 571 "Marinecraft (South Korea)" 573 "McMurdo Group aka Orolia" 578 "Advansea" 579 "KVH" 580 "San Jose Technology" 583 "Yacht Control" 586 "Suzuki Motor" 591 "US Coast Guard" 595 "Ship Module aka Customware" 600 "Aquatic AV" 605 "Aventics" 606 "Intellian" 612 "SamwonIT" 614 "Arlt Tecnologies" 637 "Bavaria Yachts" 641 "Diverse Yacht Services" 644 "Wema U.S.A dba KUS" 658 "Shenzhen Jiuzhou Himunication" 688 "Rockford" 699 "Harman International" 704 "JL Audio" 708 "Lars Thrane" 715 "Autonnic" 717 "Yacht Devices" 734 "REAP Systems" 735 "AEM Performance Electronics" 739 "LxNav" 741 "Littelfuse, Inc (formerly Carling Technologies)" 743 "DaeMyung" 744 "Woosung" 748 "ISOTTA IFRA srl" 773 "Clarion US" 776 "HMI Systems" 777 "Ocean Signal" 778 "Seakeeper" 781 "Poly Planar" 785 "Fischer Panda DE" 795 "Broyda Industries" 796 "Canadian Automotive" 797 "Tides Marine" 798 "Lumishore" 799 "Still Water Designs and Audio" 802 "BJ Technologies (Beneteau)" 803 "Gill Sensors" 811 "Blue Water Desalination" 815 "FLIR" 824 "Undheim Systems" 826 "Lewmar" 838 "TeamSurv" 844 "Fell Marine" 847 "Oceanvolt" 862 "Prospec" 868 "Data Panel" 890 "L3 Technologies" 894 "Rhodan Marine Systems" 896 "Nexfour Solutions" 905 "ASA Electronics" 909 "Marines Co (South Korea)" 911 "Nautic-on" 917 "Sentinel" 929 "JL Marine Systems" 930 "Ecotronix" 944 "Zontisa Marine" 951 "EXOR International" 962 "Timbolier Industries" 963 "TJC Micro" 968 "Cox Powertrain" 969 "Blue Seas" 981 "Kobelt Manufacturing" 992 "Blue Ocean IOT" 997 "Xenta Systems" 999 "Signal K" 1004 "Ultraflex" 1008 "Lintest SmartBoat" 1011 "Soundmax" 1020 "Team Italia Marine (Onyx Marine Automation s.r.l)" 1021 "Entratech" 1022 "ITC" 1029 "The Marine Guardian" 1047 "Sonic" 1051 "ProNav" 1053 "Vetus Maxwell INC." 1056 "Lithium Pros" 1059 "Boatrax" 1062 "Marol Co ltd" 1065 "CALYPSO Instruments" 1066 "Spot Zero Water" 1069 "Lithionics Battery" 1070 "Quick-teck Electronics" 1075 "Uniden America" 1083 "Nauticoncept" 1084 "Shadow-Caster LED lighting" 1085 "Wet Sounds" 1088 "E-T-A Circuit Breakers" 1092 "Scheiber" 1100 "Smart Yachts International Limited" 1109 "Dockmate" 1114 "Bobs Machine" 1118 "L3Harris ASV" 1119 "Balmar" 1120 "Elettromedia" 1127 "Electromaax" 1140 "Across Oceans Systems" 1145 "Kiwi Yachting" 1150 "BSB Artificial Intelligence" 1151 "Orca Technologies" 1154 "TBS Electronics" 1158 "Technoton Electroics" 1160 "MG Energy Systems" 1169 "Sea Machine Robotics" 1171 "Vista Manufacturing" 1183 "Zipwake" 1186 "Sailmon" 1192 "Airmoniq Pro Kft" 1194 "Sierra Marine" 1200 "Xinuo Information Technology (Xiamen)" 1218 "Septentrio" 1233 "NKE Marine Electronics" 1238 "SuperTrack Aps" 1239 "Honda Electronics" 1245 "Raritan Engineering" 1249 "Integrated Power Solutions AG" 1260 "Interactive Technologies" 1283 "LTG-Tech" 1299 "Energy Solutions (UK)" 1300 "WATT Fuel Cell" 1302 "Pro Mainer" 1305 "Dragonfly Energy" 1306 "Koden Electronics" 1311 "Humphree" 1316 "Hinkley Yachts" 1317 "Global Marine Management GmbH (GMM)" 1320 "Triskel Marine" 1330 "Warwick Control Technologies" 1331 "Dolphin Charger" 1337 "Barnacle Systems" 1348 "Radian IoT" 1353 "Ocean LED Marine" 1359 "BluNav" 1361 "OVA (Nantong Saiyang Electronics Co., Ltd)" 1368 "RAD Propulsion" 1369 "Electric Yacht" 1372 "Elco Motor Yachts" 1384 "Tecnoseal Foundry S.r.l" 1385 "Pro Charging Systems" 1389 "EVEX" 1398 "Gobius Sensor Technology" 1403 "Arco Marine" 1408 "Lenco Marine" 1413 "Naocontrol" 1417 "Revatek" 1438 "Aeolionics" 1439 "PredictWind" 1440 "Egis Mobile Electric" 1445 "Starboard Yacht Group" 1446 "Roswell Marine" 1451 "ePropulsion (Guangdong ePropulsion Technology Ltd.)" 1452 "Micro-Air" 1453 "Vital Battery" 1458 "Ride Controller" 1460 "Tocaro Blue" 1461 "Vanquish Yachts" 1471 "FT Technologies" 1478 "Alps Alpine" 1481 "E-Force Marine" 1482 "CMC Marine" 1483 "Nanjing Sandemarine Information Technology" 1850 "Teleflex Marine (SeaStar Solutions)" 1851 "Raymarine" 1852 "Navionics" 1853 "Japan Radio" 1854 "Northstar Technologies" 1855 "Furuno" 1856 "Trimble" 1857 "Simrad" 1858 "Litton" 1859 "Kvasar" 1860 "MMP" 1861 "Vector Cantech" 1862 "Yamaha Marine" 1863 "Faria Instruments" ;
VAL_ 2566849536 Industry_Code 0 "Global" 1 "Highway" 2 "Agriculture" 3 "Construction" 4 "Marine Industry" 5 "Industrial" ;
VAL_ 2566849536 Manufacturer_Code 69 "ARKS Enterprises" 78 "FW Murphy/Enovation Controls" 80 "Twin Disc" 85 "Kohler Power Systems" 88 "Hemisphere GPS" 135 "Airmar" 137 "Maretron" 140 "Lowrance" 144 "Mercury Marine" 147 "Nautibus Electronic" 148 "Blue Water Data" 154 "Westerbeke" 157 "ISSPRO" 161 "Offshore Systems (UK)" 163 "Evinrude/BRP" 165 "CPAC Systems" 168 "Xantrex Technology" 169 "Marlin Technologies" 172 "Yanmar Marine" 174 "Volvo Penta" 176 "Carling Technologies Inc. (Moritz Aerospace)" 185 "Beede Instruments" 192 "Floscan Instrument" 193 "Nobeltec" 198 "Mystic Valley Communications" 199 "Actia" 201 "Disenos Y Technologia" 211 "Digital Switching Systems" 215 "Xintex/Atena" 224 "EMMI NETWORK" 228 "ZF" 229 "Garmin" 233 "Yacht Monitoring Solutions" 235 "Sailormade Marine Telemetry/Tetra Technology" 243 "Eride" 257 "Honda Motor" 272 "Groco" 273 "Actisense" 274 "Amphenol LTW Technology" 275 "Navico" 283 "Hamilton Jet" 285 "Sea Recovery" 286 "Coelmo SRL Italy" 295 "BEP Marine" 304 "Empir Bus" 305 "NovAtel" 306 "Sleipner Motor" 307 "MBW Technologies" 315 "ICOM" 328 "Qwerty" 329 "Dief" 341 "Boening Automationstechnologie" 345 "Korean Maritime University" 351 "Thrane and Thrane" 355 "Mastervolt" 356 "Fischer Panda Generators" 358 "Victron Energy" 370 "Rolls Royce Marine" 373 "Electronic Design" 374 "Northern Lights" 378 "Glendinning" 381 "B & G" 384 "Rose Point Navigation Systems" 385 "Johnson Outdoors Marine Electronics Inc Geonav" 394 "Capi 2" 396 "Beyond Measure" 400 "Livorsi Marine" 404 "ComNav" 409 "Chetco" 419 "Fusion Electronics" 421 "Standard Horizon" 422 "True Heading" 426 "Egersund Marine Electronics" 427 "em-trak Marine Electronics" 431 "Tohatsu Co, JP" 437 "Digital Yacht" 438 "Comar Systems Limited" 440 "Cummins" 443 "VDO (aka Continental-Corporation)" 451 "Parker Hannifin aka Village Marine Tech" 459 "Alltek Marine Electronics" 460 "SAN GIORGIO S.E.I.N" 466 "Veethree Electronics & Marine" 470 "SI-TEX Marine Electronics" 471 "Sea Cross Marine" 475 "GME aka Standard Communications" 476 "Humminbird Marine Electronics" 478 "Ocean Sat" 481 "Chetco Digital Instruments" 493 "Watcheye" 499 "Lcj Capteurs" 502 "Attwood Marine" 503 "Naviop S.R.L." 504 "Vesper Marine" 510 "Marinesoft" 513 "Simarine" 517 "NoLand Engineering" 518 "Transas USA" 529 "National Instruments Korea" 530 "National Marine Electronics Association" 532 "Onwa Marine" 540 "Webasto" 571 "Marinecraft (South Korea)" 573 "McMurdo Group aka Orolia" 578 "Advansea" 579 "KVH" 580 "San Jose Technology" 583 "Yacht Control" 586 "Suzuki Motor" 591 "US Coast Guard" 595 "Ship Module aka Customware" 600 "Aquatic AV" 605 "Aventics" 606 "Intellian" 612 "SamwonIT" 614 "Arlt Tecnologies" 637 "Bavaria Yachts" 641 "Diverse Yacht Services" 644 "Wema U.S.A dba KUS" 658 "Shenzhen Jiuzhou Himunication" 688 "Rockford" 699 "Harman International" 704 "JL Audio" 708 "Lars Thrane" 715 "Autonnic" 717 "Yacht Devices" 734 "REAP Systems" 735 "AEM Performance Electronics" 739 "LxNav" 741 "Littelfuse, Inc (formerly Carling Technologies)" 743 "DaeMyung" 744 "Woosung" 748 "ISOTTA IFRA srl" 773 "Clarion US" 776 "HMI Systems" 777 "Ocean Signal" 778 "Seakeeper" 781 "Poly Planar" 785 "Fischer Panda DE" 795 "Broyda Industries" 796 "Canadian Automotive" 797 "Tides Marine" 798 "Lumishore" 799 "Still Water Designs and Audio" 802 "BJ Technologies (Beneteau)" 803 "Gill Sensors" 811 "Blue Water Desalination" 815 "FLIR" 824 "Undheim Systems" 826 "Lewmar" 838 "TeamSurv" 844 "Fell Marine" 847 "Oceanvolt" 862 "Prospec" 868 "Data Panel" 890 "L3 Technologies" 894 "Rhodan Marine Systems" 896 "Nexfour Solutions" 905 "ASA Electronics" 909 "Marines Co (South Korea)" 911 "Nautic-on" 917 "Sentinel" 929 "JL Marine Systems" 930 "Ecotronix" 944 "Zontisa Marine" 951 "EXOR International" 962 "Timbolier Industries" 963 "TJC Micro" 968 "Cox Powertrain" 969 "Blue Seas" 981 "Kobelt Manufacturing" 992 "Blue Ocean IOT" 997 "Xenta Systems" 999 "Signal K" 1004 "Ultraflex" 1008 "Lintest SmartBoat" 1011 "Soundmax" 1020 "Team Italia Marine (Onyx Marine Automation s.r.l)" 1021 "Entratech" 1022 "ITC" 1029 "The Marine Guardian" 1047 "Sonic" 1051 "ProNav" 1053 "Vetus Maxwell INC." 1056 "Lithium Pros" 1059 "Boatrax" 1062 "Marol Co ltd" 1065 "CALYPSO Instruments" 1066 "Spot Zero Water" 1069 "Lithionics Battery" 1070 "Quick-teck Electronics" 1075 "Uniden America" 1083 "Nauticoncept" 1084 "Shadow-Caster LED lighting" 1085 "Wet Sounds" 1088 "E-T-A Circuit Breakers" 1092 "Scheiber" 1100 "Smart Yachts International Limited" 1109 "Dockmate" 1114 "Bobs Machine" 1118 "L3Harris ASV" 1119 "Balmar" 1120 "Elettromedia" 1127 "Electromaax" 1140 "Across Oceans Systems" 1145 "Kiwi Yachting" 1150 "BSB Artificial Intelligence" 1151 "Orca Technologies" 1154 "TBS Electronics" 1158 "Technoton Electroics" 1160 "MG Energy Systems" 1169 "Sea Machine Robotics" 1171 "Vista Manufacturing" 1183 "Zipwake" 1186 "Sailmon" 1192 "Airmoniq Pro Kft" 1194 "Sierra Marine" 1200 "Xinuo Information Technology (Xiamen)" 1218 "Septentrio" 1233 "NKE Marine Electronics" 1238 "SuperTrack Aps" 1239 "Honda Electronics" 1245 "Raritan Engineering" 1249 "Integrated Power Solutions AG" 1260 "Interactive Technologies" 1283 "LTG-Tech" 1299 "Energy Solutions (UK)" 1300 "WATT Fuel Cell" 1302 "Pro Mainer" 1305 "Dragonfly Energy" 1306 "Koden Electronics" 1311 "Humphree" 1316 "Hinkley Yachts" 1317 "Global Marine Management GmbH (GMM)" 1320 "Triskel Marine" 1330 "Warwick Control Technologies" 1331 "Dolphin Charger" 1337 "Barnacle Systems" 1348 "Radian IoT" 1353 "Ocean LED Marine" 1359 "BluNav" 1361 "OVA (Nantong Saiyang Electronics Co., Ltd)" 1368 "RAD Propulsion" 1369 "Electric Yacht" 1372 "Elco Motor Yachts" 1384 "Tecnoseal Foundry S.r.l" 1385 "Pro Charging Systems" 1389 "EVEX" 1398 "Gobius Sensor Technology" 1403 "Arco Marine" 1408 "Lenco Marine" 1413 "Naocontrol" 1417 "Revatek" 1438 "Aeolionics" 1439 "PredictWind" 1440 "Egis Mobile Electric" 1445 "Starboard Yacht Group" 1446 "Roswell Marine" 1451 "ePropulsion (Guangdong ePropulsion Technology Ltd.)" 1452 "Micro-Air" 1453 "Vital Battery" 1458 "Ride Controller" 1460 "Tocaro Blue" 1461 "Vanquish Yachts" 1471 "FT Technologies" 1478 "Alps Alpine" 1481 "E-Force Marine" 1482 "CMC Marine" 1483 "Nanjing Sandemarine Information Technology" 1850 "Teleflex Marine (SeaStar Solutions)" 1851 "Raymarine" 1852 "Navionics" 1853 "Japan Radio" 1854 "Northstar Technologies" 1855 "Furuno" 1856 "Trimble" 1857 "Simrad" 1858 "Litton" 1859 "Kvasar" 1860 "MMP" 1861 "Vector Cantech" 1862 "Yamaha Marine" 1863 "Faria Instruments" ;
VAL_ 2566849536 Industry_Code 0 "Global" 1 "Highway" 2 "Agriculture" 3 "Construction" 4 "Marine Industry" 5 "Industrial" ;
VAL_ 2566849536 Manufacturer_Code 69 "ARKS Enterprises" 78 "FW Murphy/Enovation Controls" 80 "Twin Disc" 85 "Kohler Power Systems" 88 "Hemisphere GPS" 135 "Airmar" 137 "Maretron" 140 "Lowrance" 144 "Mercury Marine" 147 "Nautibus Electronic" 148 "Blue Water Data" 154 "Westerbeke" 157 "ISSPRO" 161 "Offshore Systems (UK)" 163 "Evinrude/BRP" 165 "CPAC Systems" 168 "Xantrex Technology" 169 "Marlin Technologies" 172 "Yanmar Marine" 174 "Volvo Penta" 176 "Carling Technologies Inc. (Moritz Aerospace)" 185 "Beede Instruments" 192 "Floscan Instrument" 193 "Nobeltec" 198 "Mystic Valley Communications" 199 "Actia" 201 "Disenos Y Technologia" 211 "Digital Switching Systems" 215 "Xintex/Atena" 224 "EMMI NETWORK" 228 "ZF" 229 "Garmin" 233 "Yacht Monitoring Solutions" 235 "Sailormade Marine Telemetry/Tetra Technology" 243 "Eride" 257 "Honda Motor" 272 "Groco" 273 "Actisense" 274 "Amphenol LTW Technology" 275 "Navico" 283 "Hamilton Jet" 285 "Sea Recovery" 286 "Coelmo SRL Italy" 295 "BEP Marine" 304 "Empir Bus" 305 "NovAtel" 306 "Sleipner Motor" 307 "MBW Technologies" 315 "ICOM" 328 "Qwerty" 329 "Dief" 341 "Boening Automationstechnologie" 345 "Korean Maritime University" 351 "Thrane and Thrane" 355 "Mastervolt" 356 "Fischer Panda Generators" 358 "Victron Energy" 370 "Rolls Royce Marine" 373 "Electronic Design" 374 "Northern Lights" 378 "Glendinning" 381 "B & G" 384 "Rose Point Navigation Systems" 385 "Johnson Outdoors Marine Electronics Inc Geonav" 394 "Capi 2" 396 "Beyond Measure" 400 "Livorsi Marine" 404 "ComNav" 409 "Chetco" 419 "Fusion Electronics" 421 "Standard Horizon" 422 "True Heading" 426 "Egersund Marine Electronics" 427 "em-trak Marine Electronics" 431 "Tohatsu Co, JP" 437 "Digital Yacht" 438 "Comar Systems Limited" 440 "Cummins" 443 "VDO (aka Continental-Corporation)" 451 "Parker Hannifin aka Village Marine Tech" 459 "Alltek Marine Electronics" 460 "SAN GIORGIO S.E.I.N" 466 "Veethree Electronics & Marine" 470 "SI-TEX Marine Electronics" 471 "Sea Cross Marine" 475 "GME aka Standard Communications" 476 "Humminbird Marine Electronics" 478 "Ocean Sat" 481 "Chetco Digital Instruments" 493 "Watcheye" 499 "Lcj Capteurs" 502 "Attwood Marine" 503 "Naviop S.R.L." 504 "Vesper Marine" 510 "Marinesoft" 513 "Simarine" 517 "NoLand Engineering" 518 "Transas USA" 529 "National Instruments Korea" 530 "National Marine Electronics Association" 532 "Onwa Marine" 540 "Webasto" 571 "Marinecraft (South Korea)" 573 "McMurdo Group aka Orolia" 578 "Advansea" 579 "KVH" 580 "San Jose Technology" 583 "Yacht Control" 586 "Suzuki Motor" 591 "US Coast Guard" 595 "Ship Module aka Customware" 600 "Aquatic AV" 605 "Aventics" 606 "Intellian" 612 "SamwonIT" 614 "Arlt Tecnologies" 637 "Bavaria Yachts" 641 "Diverse Yacht Services" 644 "Wema U.S.A dba KUS" 658 "Shenzhen Jiuzhou Himunication" 688 "Rockford" 699 "Harman International" 704 "JL Audio" 708 "Lars Thrane" 715 "Autonnic" 717 "Yacht Devices" 734 "REAP Systems" 735 "AEM Performance Electronics" 739 "LxNav" 741 "Littelfuse, Inc (formerly Carling Technologies)" 743 "DaeMyung" 744 "Woosung" 748 "ISOTTA IFRA srl" 773 "Clarion US" 776 "HMI Systems" 777 "Ocean Signal" 778 "Seakeeper" 781 "Poly Planar" 785 "Fischer Panda DE" 795 "Broyda Industries" 796 "Canadian Automotive" 797 "Tides Marine" 798 "Lumishore" 799 "Still Water Designs and Audio" 802 "BJ Technologies (Beneteau)" 803 "Gill Sensors" 811 "Blue Water Desalination" 815 "FLIR" 824 "Undheim Systems" 826 "Lewmar" 838 "TeamSurv" 844 "Fell Marine" 847 "Oceanvolt" 862 "Prospec" 868 "Data Panel" 890 "L3 Technologies" 894 "Rhodan Marine Systems" 896 "Nexfour Solutions" 905 "ASA Electronics" 909 "Marines Co (South Korea)" 911 "Nautic-on" 917 "Sentinel" 929 "JL Marine Systems" 930 "Ecotronix" 944 "Zontisa Marine" 951 "EXOR International" 962 "Timbolier Industries" 963 "TJC Micro" 968 "Cox Powertrain" 969 "Blue Seas" 981 "Kobelt Manufacturing" 992 "Blue Ocean IOT" 997 "Xenta Systems" 999 "Signal K" 1004 "Ultraflex" 1008 "Lintest SmartBoat" 1011 "Soundmax" 1020 "Team Italia Marine (Onyx Marine Automation s.r.l)" 1021 "Entratech" 1022 "ITC" 1029 "The Marine Guardian" 1047 "Sonic" 1051 "ProNav" 1053 "Vetus Maxwell INC." 1056 "Lithium Pros" 1059 "Boatrax" 1062 "Marol Co ltd" 1065 "CALYPSO Instruments" 1066 "Spot Zero Water" 1069 "Lithionics Battery" 1070 "Quick-teck Electronics" 1075 "Uniden America" 1083 "Nauticoncept" 1084 "Shadow-Caster LED lighting" 1085 "Wet Sounds" 1088 "E-T-A Circuit Breakers" 1092 "Scheiber" 1100 "Smart Yachts International Limited" 1109 "Dockmate" 1114 "Bobs Machine" 1118 "L3Harris ASV" 1119 "Balmar" 1120 "Elettromedia" 1127 "Electromaax" 1140 "Across Oceans Systems" 1145 "Kiwi Yachting" 1150 "BSB Artificial Intelligence" 1151 "Orca Technologies" 1154 "TBS Electronics" 1158 "Technoton Electroics" 1160 "MG Energy Systems" 1169 "Sea Machine Robotics" 1171 "Vista Manufacturing" 1183 "Zipwake" 1186 "Sailmon" 1192 "Airmoniq Pro Kft" 1194 "Sierra Marine" 1200 "Xinuo Information Technology (Xiamen)" 1218 "Septentrio" 1233 "NKE Marine Electronics" 1238 "SuperTrack Aps" 1239 "Honda Electronics" 1245 "Raritan Engineering" 1249 "Integrated Power Solutions AG" 1260 "Interactive Technologies" 1283 "LTG-Tech" 1299 "Energy Solutions (UK)" 1300 "WATT Fuel Cell" 1302 "Pro Mainer" 1305 "Dragonfly Energy" 1306 "Koden Electronics" 1311 "Humphree" 1316 "Hinkley Yachts" 1317 "Global Marine Management GmbH (GMM)" 1320 "Triskel Marine" 1330 "Warwick Control Technologies" 1331 "Dolphin Charger" 1337 "Barnacle Systems" 1348 "Radian IoT" 1353 "Ocean LED Marine" 1359 "BluNav" 1361 "OVA (Nantong Saiyang Electronics Co., Ltd)" 1368 "RAD Propulsion" 1369 "Electric Yacht" 1372 "Elco Motor Yachts" 1384 "Tecnoseal Foundry S.r.l" 1385 "Pro Charging Systems" 1389 "EVEX" 1398 "Gobius Sensor Technology" 1403 "Arco Marine" 1408 "Lenco Marine" 1413 "Naocontrol" 1417 "Revatek" 1438 "Aeolionics" 1439 "PredictWind" 1440 "Egis Mobile Electric" 1445 "Starboard Yacht Group" 1446 "Roswell Marine" 1451 "ePropulsion (Guangdong ePropulsion Technology Ltd.)" 1452 "Micro-Air" 1453 "Vital Battery" 1458 "Ride Controller" 1460 "Tocaro Blue" 1461 "Vanquish Yachts" 1471 "FT Technologies" 1478 "Alps Alpine" 1481 "E-Force Marine" 1482 "CMC Marine" 1483 "Nanjing Sandemarine Information Technology" 1850 "Teleflex Marine (SeaStar Solutions)" 1851 "Raymarine" 1852 "Navionics" 1853 "Japan Radio" 1854 "Northstar Technologies" 1855 "Furuno" 1856 "Trimble" 1857 "Simrad" 1858 "Litton" 1859 "Kvasar" 1860 "MMP" 1861 "Vector Cantech" 1862 "Yamaha Marine" 1863 "Faria Instruments" ;
VAL_ 2566849536 Industry_Code 0 "Global" 1 "Highway" 2 "Agriculture" 3 "Construction" 4 "Marine Industry" 5 "Industrial" ;
VAL_ 2298414080 Manufacturer_Code 69 "ARKS Enterprises" 78 "FW Murphy/Enovation Controls" 80 "Twin Disc" 85 "Kohler Power Systems" 88 "Hemisphere GPS" 135 "Airmar" 137 "Maretron" 140 "Lowrance" 144 "Mercury Marine" 147 "Nautibus Electronic" 148 "Blue Water Data" 154 "Westerbeke" 157 "ISSPRO" 161 "Offshore Systems (UK)" 163 "Evinrude/BRP" 165 "CPAC Systems" 168 "Xantrex Technology" 169 "Marlin Technologies" 172 "Yanmar Marine" 174 "Volvo Penta" 176 "Carling Technologies Inc. (Moritz Aerospace)" 185 "Beede Instruments" 192 "Floscan Instrument" 193 "Nobeltec" 198 "Mystic Valley Communications" 199 "Actia" 201 "Disenos Y Technologia" 211 "Digital Switching Systems" 215 "Xintex/Atena" 224 "EMMI NETWORK" 228 "ZF" 229 "Garmin" 233 "Yacht Monitoring Solutions" 235 "Sailormade Marine Telemetry/Tetra Technology" 243 "Eride" 257 "Honda Motor" 272 "Groco" 273 "Actisense" 274 "Amphenol LTW Technology" 275 "Navico" 283 "Hamilton Jet" 285 "Sea Recovery" 286 "Coelmo SRL Italy" 295 "BEP Marine" 304 "Empir Bus" 305 "NovAtel" 306 "Sleipner Motor" 307 "MBW Technologies" 315 "ICOM" 328 "Qwerty" 329 "Dief" 341 "Boening Automationstechnologie" 345 "Korean Maritime University" 351 "Thrane and Thrane" 355 "Mastervolt" 356 "Fischer Panda Generators" 358 "Victron Energy" 370 "Rolls Royce Marine" 373 "Electronic Design" 374 "Northern Lights" 378 "Glendinning" 381 "B & G" 384 "Rose Point Navigation Systems" 385 "Johnson Outdoors Marine Electronics Inc Geonav" 394 "Capi 2" 396 "Beyond Measure" 400 "Livorsi Marine" 404 "ComNav" 409 "Chetco" 419 "Fusion Electronics" 421 "Standard Horizon" 422 "True Heading" 426 "Egersund Marine Electronics" 427 "em-trak Marine Electronics" 431 "Tohatsu Co, JP" 437 "Digital Yacht" 438 "Comar Systems Limited" 440 "Cummins" 443 "VDO (aka Continental-Corporation)" 451 "Parker Hannifin aka Village Marine Tech" 459 "Alltek Marine Electronics" 460 "SAN GIORGIO S.E.I.N" 466 "Veethree Electronics & Marine" 470 "SI-TEX Marine Electronics" 471 "Sea Cross Marine" 475 "GME aka Standard Communications" 476 "Humminbird Marine Electronics" 478 "Ocean Sat" 481 "Chetco Digital Instruments" 493 "Watcheye" 499 "Lcj Capteurs" 502 "Attwood Marine" 503 "Naviop S.R.L." 504 "Vesper Marine" 510 "Marinesoft" 513 "Simarine" 517 "NoLand Engineering" 518 "Transas USA" 529 "National Instruments Korea" 530 "National Marine Electronics Association" 532 "Onwa Marine" 540 "Webasto" 571 "Marinecraft (South Korea)" 573 "McMurdo Group aka Orolia" 578 "Advansea" 579 "KVH" 580 "San Jose Technology" 583 "Yacht Control" 586 "Suzuki Motor" 591 "US Coast Guard" 595 "Ship Module aka Customware" 600 "Aquatic AV" 605 "Aventics" 606 "Intellian" 612 "SamwonIT" 614 "Arlt Tecnologies" 637 "Bavaria Yachts" 641 "Diverse Yacht Services" 644 "Wema U.S.A dba KUS" 658 "Shenzhen Jiuzhou Himunication" 688 "Rockford" 699 "Harman International" 704 "JL Audio" 708 "Lars Thrane" 715 "Autonnic" 717 "Yacht Devices" 734 "REAP Systems" 735 "AEM Performance Electronics" 739 "LxNav" 741 "Littelfuse, Inc (formerly Carling Technologies)" 743 "DaeMyung" 744 "Woosung" 748 "ISOTTA IFRA srl" 773 "Clarion US" 776 "HMI Systems" 777 "Ocean Signal" 778 "Seakeeper" 781 "Poly Planar" 785 "Fischer Panda DE" 795 "Broyda Industries" 796 "Canadian Automotive" 797 "Tides Marine" 798 "Lumishore" 799 "Still Water Designs and Audio" 802 "BJ Technologies (Beneteau)" 803 "Gill Sensors" 811 "Blue Water Desalination" 815 "FLIR" 824 "Undheim Systems" 826 "Lewmar" 838 "TeamSurv" 844 "Fell Marine" 847 "Oceanvolt" 862 "Prospec" 868 "Data Panel" 890 "L3 Technologies" 894 "Rhodan Marine Systems" 896 "Nexfour Solutions" 905 "ASA Electronics" 909 "Marines Co (South Korea)" 911 "Nautic-on" 917 "Sentinel" 929 "JL Marine Systems" 930 "Ecotronix" 944 "Zontisa Marine" 951 "EXOR International" 962 "Timbolier Industries" 963 "TJC Micro" 968 "Cox Powertrain" 969 "Blue Seas" 981 "Kobelt Manufacturing" 992 "Blue Ocean IOT" 997 "Xenta Systems" 999 "Signal K" 1004 "Ultraflex" 1008 "Lintest SmartBoat" 1011 "Soundmax" 1020 "Team Italia Marine (Onyx Marine Automation s.r.l)" 1021 "Entratech" 1022 "ITC" 1029 "The Marine Guardian" 1047 "Sonic" 1051 "ProNav" 1053 "Vetus Maxwell INC." 1056 "Lithium Pros" 1059 "Boatrax" 1062 "Marol Co ltd" 1065 "CALYPSO Instruments" 1066 "Spot Zero Water" 1069 "Lithionics Battery" 1070 "Quick-teck Electronics" 1075 "Uniden America" 1083 "Nauticoncept" 1084 "Shadow-Caster LED lighting" 1085 "Wet Sounds" 1088 "E-T-A Circuit Breakers" 1092 "Scheiber" 1100 "Smart Yachts International Limited" 1109 "Dockmate" 1114 "Bobs Machine" 1118 "L3Harris ASV" 1119 "Balmar" 1120 "Elettromedia" 1127 "Electromaax" 1140 "Across Oceans Systems" 1145 "Kiwi Yachting" 1150 "BSB Artificial Intelligence" 1151 "Orca Technologies" 1154 "TBS Electronics" 1158 "Technoton Electroics" 1160 "MG Energy Systems" 1169 "Sea Machine Robotics" 1171 "Vista Manufacturing" 1183 "Zipwake" 1186 "Sailmon" 1192 "Airmoniq Pro Kft" 1194 "Sierra Marine" 1200 "Xinuo Information Technology (Xiamen)" 1218 "Septentrio" 1233 "NKE Marine Electronics" 1238 "SuperTrack Aps" 1239 "Honda Electronics" 1245 "Raritan Engineering" 1249 "Integrated Power Solutions AG" 1260 "Interactive Technologies" 1283 "LTG-Tech" 1299 "Energy Solutions (UK)" 1300 "WATT Fuel Cell" 1302 "Pro Mainer" 1305 "Dragonfly Energy" 1306 "Koden Electronics" 1311 "Humphree" 1316 "Hinkley Yachts" 1317 "Global Marine Management GmbH (GMM)" 1320 "Triskel Marine" 1330 "Warwick Control Technologies" 1331 "Dolphin Charger" 1337 "Barnacle Systems" 1348 "Radian IoT" 1353 "Ocean LED Marine" 1359 "BluNav" 1361 "OVA (Nantong Saiyang Electronics Co., Ltd)" 1368 "RAD Propulsion" 1369 "Electric Yacht" 1372 "Elco Motor Yachts" 1384 "Tecnoseal Foundry S.r.l" 1385 "Pro Charging Systems" 1389 "EVEX" 1398 "Gobius Sensor Technology" 1403 "Arco Marine" 1408 "Lenco Marine" 1413 "Naocontrol" 1417 "Revatek" 1438 "Aeolionics" 1439 "PredictWind" 1440 "Egis Mobile Electric" 1445 "Starboard Yacht Group" 1446 "Roswell Marine" 1451 "ePropulsion (Guangdong ePropulsion Technology Ltd.)" 1452 "Micro-Air" 1453 "Vital Battery" 1458 "Ride Controller" 1460 "Tocaro Blue" 1461 "Vanquish Yachts" 1471 "FT Technologies" 1478 "Alps Alpine" 1481 "E-Force Marine" 1482 "CMC Marine" 1483 "Nanjing Sandemarine Information Technology" 1850 "Teleflex Marine (SeaStar Solutions)" 1851 "Raymarine" 1852 "Navionics" 1853 "Japan Radio" 1854 "Northstar Technologies" 1855 "Furuno" 1856 "Trimble" 1857 "Simrad" 1858 "Litton" 1859 "Kvasar" 1860 "MMP" 1861 "Vector Cantech" 1862 "Yamaha Marine" 1863 "Faria Instruments" ;
VAL_ 2298414080 Industry_Code 0 "Global" 1 "Highway" 2 "Agriculture" 3 "Construction" 4 "Marine Industry" 5 "Industrial" ;
VAL_ 2298414080 Engine_Instance 0 "Single Engine or Dual Engine Port" 1 "Dual Engine Starboard" ;
VAL_ 2298414080 Transmission_Gear 0 "Forward" 1 "Neutral" 2 "Reverse" ;
VAL_ 2499740928 Manufacturer_Code 69 "ARKS Enterprises" 78 "FW Murphy/Enovation Controls" 80 "Twin Disc" 85 "Kohler Power Systems" 88 "Hemisphere GPS" 135 "Airmar" 137 "Maretron" 140 "Lowrance" 144 "Mercury Marine" 147 "Nautibus Electronic" 148 "Blue Water Data" 154 "Westerbeke" 157 "ISSPRO" 161 "Offshore Systems (UK)" 163 "Evinrude/BRP" 165 "CPAC Systems" 168 "Xantrex Technology" 169 "Marlin Technologies" 172 "Yanmar Marine" 174 "Volvo Penta" 176 "Carling Technologies Inc. (Moritz Aerospace)" 185 "Beede Instruments" 192 "Floscan Instrument" 193 "Nobeltec" 198 "Mystic Valley Communications" 199 "Actia" 201 "Disenos Y Technologia" 211 "Digital Switching Systems" 215 "Xintex/Atena" 224 "EMMI NETWORK" 228 "ZF" 229 "Garmin" 233 "Yacht Monitoring Solutions" 235 "Sailormade Marine Telemetry/Tetra Technology" 243 "Eride" 257 "Honda Motor" 272 "Groco" 273 "Actisense" 274 "Amphenol LTW Technology" 275 "Navico" 283 "Hamilton Jet" 285 "Sea Recovery" 286 "Coelmo SRL Italy" 295 "BEP Marine" 304 "Empir Bus" 305 "NovAtel" 306 "Sleipner Motor" 307 "MBW Technologies" 315 "ICOM" 328 "Qwerty" 329 "Dief" 341 "Boening Automationstechnologie" 345 "Korean Maritime University" 351 "Thrane and Thrane" 355 "Mastervolt" 356 "Fischer Panda Generators" 358 "Victron Energy" 370 "Rolls Royce Marine" 373 "Electronic Design" 374 "Northern Lights" 378 "Glendinning" 381 "B & G" 384 "Rose Point Navigation Systems" 385 "Johnson Outdoors Marine Electronics Inc Geonav" 394 "Capi 2" 396 "Beyond Measure" 400 "Livorsi Marine" 404 "ComNav" 409 "Chetco" 419 "Fusion Electronics" 421 "Standard Horizon" 422 "True Heading" 426 "Egersund Marine Electronics" 427 "em-trak Marine Electronics" 431 "Tohatsu Co, JP" 437 "Digital Yacht" 438 "Comar Systems Limited" 440 "Cummins" 443 "VDO (aka Continental-Corporation)" 451 "Parker Hannifin aka Village Marine Tech" 459 "Alltek Marine Electronics" 460 "SAN GIORGIO S.E.I.N" 466 "Veethree Electronics & Marine" 470 "SI-TEX Marine Electronics" 471 "Sea Cross Marine" 475 "GME aka Standard Communications" 476 "Humminbird Marine Electronics" 478 "Ocean Sat" 481 "Chetco Digital Instruments" 493 "Watcheye" 499 "Lcj Capteurs" 502 "Attwood Marine" 503 "Naviop S.R.L." 504 "Vesper Marine" 510 "Marinesoft" 513 "Simarine" 517 "NoLand Engineering" 518 "Transas USA" 529 "National Instruments Korea" 530 "National Marine Electronics Association" 532 "Onwa Marine" 540 "Webasto" 571 "Marinecraft (South Korea)" 573 "McMurdo Group aka Orolia" 578 "Advansea" 579 "KVH" 580 "San Jose Technology" 583 "Yacht Control" 586 "Suzuki Motor" 591 "US Coast Guard" 595 "Ship Module aka Customware" 600 "Aquatic AV" 605 "Aventics" 606 "Intellian" 612 "SamwonIT" 614 "Arlt Tecnologies" 637 "Bavaria Yachts" 641 "Diverse Yacht Services" 644 "Wema U.S.A dba KUS" 658 "Shenzhen Jiuzhou Himunication" 688 "Rockford" 699 "Harman International" 704 "JL Audio" 708 "Lars Thrane" 715 "Autonnic" 717 "Yacht Devices" 734 "REAP Systems" 735 "AEM Performance Electronics" 739 "LxNav" 741 "Littelfuse, Inc (formerly Carling Technologies)" 743 "DaeMyung" 744 "Woosung" 748 "ISOTTA IFRA srl" 773 "Clarion US" 776 "HMI Systems" 777 "Ocean Signal" 778 "Seakeeper" 781 "Poly Planar" 785 "Fischer Panda DE" 795 "Broyda Industries" 796 "Canadian Automotive" 797 "Tides Marine" 798 "Lumishore" 799 "Still Water Designs and Audio" 802 "BJ Technologies (Beneteau)" 803 "Gill Sensors" 811 "Blue Water Desalination" 815 "FLIR" 824 "Undheim Systems" 826 "Lewmar" 838 "TeamSurv" 844 "Fell Marine" 847 "Oceanvolt" 862 "Prospec" 868 "Data Panel" 890 "L3 Technologies" 894 "Rhodan Marine Systems" 896 "Nexfour Solutions" 905 "ASA Electronics" 909 "Marines Co (South Korea)" 911 "Nautic-on" 917 "Sentinel" 929 "JL Marine Systems" 930 "Ecotronix" 944 "Zontisa Marine" 951 "EXOR International" 962 "Timbolier Industries" 963 "TJC Micro" 968 "Cox Powertrain" 969 "Blue Seas" 981 "Kobelt Manufacturing" 992 "Blue Ocean IOT" 997 "Xenta Systems" 999 "Signal K" 1004 "Ultraflex" 1008 "Lintest SmartBoat" 1011 "Soundmax" 1020 "Team Italia Marine (Onyx Marine Automation s.r.l)" 1021 "Entratech" 1022 "ITC" 1029 "The Marine Guardian" 1047 "Sonic" 1051 "ProNav" 1053 "Vetus Maxwell INC." 1056 "Lithium Pros" 1059 "Boatrax" 1062 "Marol Co ltd" 1065 "CALYPSO Instruments" 1066 "Spot Zero Water" 1069 "Lithionics Battery" 1070 "Quick-teck Electronics" 1075 "Uniden America" 1083 "Nauticoncept" 1084 "Shadow-Caster LED lighting" 1085 "Wet Sounds" 1088 "E-T-A Circuit Breakers" 1092 "Scheiber" 1100 "Smart Yachts International Limited" 1109 "Dockmate" 1114 "Bobs Machine" 1118 "L3Harris ASV" 1119 "Balmar" 1120 "Elettromedia" 1127 "Electromaax" 1140 "Across Oceans Systems" 1145 "Kiwi Yachting" 1150 "BSB Artificial Intelligence" 1151 "Orca Technologies" 1154 "TBS Electronics" 1158 "Technoton Electroics" 1160 "MG Energy Systems" 1169 "Sea Machine Robotics" 1171 "Vista Manufacturing" 1183 "Zipwake" 1186 "Sailmon" 1192 "Airmoniq Pro Kft" 1194 "Sierra Marine" 1200 "Xinuo Information Technology (Xiamen)" 1218 "Septentrio" 1233 "NKE Marine Electronics" 1238 "SuperTrack Aps" 1239 "Honda Electronics" 1245 "Raritan Engineering" 1249 "Integrated Power Solutions AG" 1260 "Interactive Technologies" 1283 "LTG-Tech" 1299 "Energy Solutions (UK)" 1300 "WATT Fuel Cell" 1302 "Pro Mainer" 1305 "Dragonfly Energy" 1306 "Koden Electronics" 1311 "Humphree" 1316 "Hinkley Yachts" 1317 "Global Marine Management GmbH (GMM)" 1320 "Triskel Marine" 1330 "Warwick Control Technologies" 1331 "Dolphin Charger" 1337 "Barnacle Systems" 1348 "Radian IoT" 1353 "Ocean LED Marine" 1359 "BluNav" 1361 "OVA (Nantong Saiyang Electronics Co., Ltd)" 1368 "RAD Propulsion" 1369 "Electric Yacht" 1372 "Elco Motor Yachts" 1384 "Tecnoseal Foundry S.r.l" 1385 "Pro Charging Systems" 1389 "EVEX" 1398 "Gobius Sensor Technology" 1403 "Arco Marine" 1408 "Lenco Marine" 1413 "Naocontrol" 1417 "Revatek" 1438 "Aeolionics" 1439 "PredictWind" 1440 "Egis Mobile Electric" 1445 "Starboard Yacht Group" 1446 "Roswell Marine" 1451 "ePropulsion (Guangdong ePropulsion Technology Ltd.)" 1452 "Micro-Air" 1453 "Vital Battery" 1458 "Ride Controller" 1460 "Tocaro Blue" 1461 "Vanquish Yachts" 1471 "FT Technologies" 1478 "Alps Alpine" 1481 "E-Force Marine" 1482 "CMC Marine" 1483 "Nanjing Sandemarine Information Technology" 1850 "Teleflex Marine (SeaStar Solutions)" 1851 "Raymarine" 1852 "Navionics" 1853 "Japan Radio" 1854 "Northstar Technologies" 1855 "Furuno" 1856 "Trimble" 1857 "Simrad" 1858 "Litton" 1859 "Kvasar" 1860 "MMP" 1861 "Vector Cantech" 1862 "Yamaha Marine" 1863 "Faria Instruments" ;
VAL_ 2499740928 Industry_Code 0 "Global" 1 "Highway" 2 "Agriculture" 3 "Construction" 4 "Marine Industry" 5 "Industrial" ;
VAL_ 2499740928 Boot_State 0 "in Startup Monitor" 1 "running Bootloader" 2 "running Application" ;
VAL_ 2566849792 Manufacturer_Code 69 "ARKS Enterprises" 78 "FW Murphy/Enovation Controls" 80 "Twin Disc" 85 "Kohler Power Systems" 88 "Hemisphere GPS" 135 "Airmar" 137 "Maretron" 140 "Lowrance" 144 "Mercury Marine" 147 "Nautibus Electronic" 148 "Blue Water Data" 154 "Westerbeke" 157 "ISSPRO" 161 "Offshore Systems (UK)" 163 "Evinrude/BRP" 165 "CPAC Systems" 168 "Xantrex Technology" 169 "Marlin Technologies" 172 "Yanmar Marine" 174 "Volvo Penta" 176 "Carling Technologies Inc. (Moritz Aerospace)" 185 "Beede Instruments" 192 "Floscan Instrument" 193 "Nobeltec" 198 "Mystic Valley Communications" 199 "Actia" 201 "Disenos Y Technologia" 211 "Digital Switching Systems" 215 "Xintex/Atena" 224 "EMMI NETWORK" 228 "ZF" 229 "Garmin" 233 "Yacht Monitoring Solutions" 235 "Sailormade Marine Telemetry/Tetra Technology" 243 "Eride" 257 "Honda Motor" 272 "Groco" 273 "Actisense" 274 "Amphenol LTW Technology" 275 "Navico" 283 "Hamilton Jet" 285 "Sea Recovery" 286 "Coelmo SRL Italy" 295 "BEP Marine" 304 "Empir Bus" 305 "NovAtel" 306 "Sleipner Motor" 307 "MBW Technologies" 315 "ICOM" 328 "Qwerty" 329 "Dief" 341 "Boening Automationstechnologie" 345 "Korean Maritime University" 351 "Thrane and Thrane" 355 "Mastervolt" 356 "Fischer Panda Generators" 358 "Victron Energy" 370 "Rolls Royce Marine" 373 "Electronic Design" 374 "Northern Lights" 378 "Glendinning" 381 "B & G" 384 "Rose Point Navigation Systems" 385 "Johnson Outdoors Marine Electronics Inc Geonav" 394 "Capi 2" 396 "Beyond Measure" 400 "Livorsi Marine" 404 "ComNav" 409 "Chetco" 419 "Fusion Electronics" 421 "Standard Horizon" 422 "True Heading" 426 "Egersund Marine Electronics" 427 "em-trak Marine Electronics" 431 "Tohatsu Co, JP" 437 "Digital Yacht" 438 "Comar Systems Limited" 440 "Cummins" 443 "VDO (aka Continental-Corporation)" 451 "Parker Hannifin aka Village Marine Tech" 459 "Alltek Marine Electronics" 460 "SAN GIORGIO S.E.I.N" 466 "Veethree Electronics & Marine" 470 "SI-TEX Marine Electronics" 471 "Sea Cross Marine" 475 "GME aka Standard Communications" 476 "Humminbird Marine Electronics" 478 "Ocean Sat" 481 "Chetco Digital Instruments" 493 "Watcheye" 499 "Lcj Capteurs" 502 "Attwood Marine" 503 "Naviop S.R.L." 504 "Vesper Marine" 510 "Marinesoft" 513 "Simarine" 517 "NoLand Engineering" 518 "Transas USA" 529 "National Instruments Korea" 530 "National Marine Electronics Association" 532 "Onwa Marine" 540 "Webasto" 571 "Marinecraft (South Korea)" 573 "McMurdo Group aka Orolia" 578 "Advansea" 579 "KVH" 580 "San Jose Technology" 583 "Yacht Control" 586 "Suzuki Motor" 591 "US Coast Guard" 595 "Ship Module aka Customware" 600 "Aquatic AV" 605 "Aventics" 606 "Intellian" 612 "SamwonIT" 614 "Arlt Tecnologies" 637 "Bavaria Yachts" 641 "Diverse Yacht Services" 644 "Wema U.S.A dba KUS" 658 "Shenzhen Jiuzhou Himunication" 688 "Rockford" 699 "Harman International" 704 "JL Audio" 708 "Lars Thrane" 715 "Autonnic" 717 "Yacht Devices" 734 "REAP Systems" 735 "AEM Performance Electronics" 739 "LxNav" 741 "Littelfuse, Inc (formerly Carling Technologies)" 743 "DaeMyung" 744 "Woosung" 748 "ISOTTA IFRA srl" 773 "Clarion US" 776 "HMI Systems" 777 "Ocean Signal" 778 "Seakeeper" 781 "Poly Planar" 785 "Fischer Panda DE" 795 "Broyda Industries" 796 "Canadian Automotive" 797 "Tides Marine" 798 "Lumishore" 799 "Still Water Designs and Audio" 802 "BJ Technologies (Beneteau)" 803 "Gill Sensors" 811 "Blue Water Desalination" 815 "FLIR" 824 "Undheim Systems" 826 "Lewmar" 838 "TeamSurv" 844 "Fell Marine" 847 "Oceanvolt" 862 "Prospec" 868 "Data Panel" 890 "L3 Technologies" 894 "Rhodan Marine Systems" 896 "Nexfour Solutions" 905 "ASA Electronics" 909 "Marines Co (South Korea)" 911 "Nautic-on" 917 "Sentinel" 929 "JL Marine Systems" 930 "Ecotronix" 944 "Zontisa Marine" 951 "EXOR International" 962 "Timbolier Industries" 963 "TJC Micro" 968 "Cox Powertrain" 969 "Blue Seas" 981 "Kobelt Manufacturing" 992 "Blue Ocean IOT" 997 "Xenta Systems" 999 "Signal K" 1004 "Ultraflex" 1008 "Lintest SmartBoat" 1011 "Soundmax" 1020 "Team Italia Marine (Onyx Marine Automation s.r.l)" 1021 "Entratech" 1022 "ITC" 1029 "The Marine Guardian" 1047 "Sonic" 1051 "ProNav" 1053 "Vetus Maxwell INC." 1056 "Lithium Pros" 1059 "Boatrax" 1062 "Marol Co ltd" 1065 "CALYPSO Instruments" 1066 "Spot Zero Water" 1069 "Lithionics Battery" 1070 "Quick-teck Electronics" 1075 "Uniden America" 1083 "Nauticoncept" 1084 "Shadow-Caster LED lighting" 1085 "Wet Sounds" 1088 "E-T-A Circuit Breakers" 1092 "Scheiber" 1100 "Smart Yachts International Limited" 1109 "Dockmate" 1114 "Bobs Machine" 1118 "L3Harris ASV" 1119 "Balmar" 1120 "Elettromedia" 1127 "Electromaax" 1140 "Across Oceans Systems" 1145 "Kiwi Yachting" 1150 "BSB Artificial Intelligence" 1151 "Orca Technologies" 1154 "TBS Electronics" 1158 "Technoton Electroics" 1160 "MG Energy Systems" 1169 "Sea Machine Robotics" 1171 "Vista Manufacturing" 1183 "Zipwake" 1186 "Sailmon" 1192 "Airmoniq Pro Kft" 1194 "Sierra Marine" 1200 "Xinuo Information Technology (Xiamen)" 1218 "Septentrio" 1233 "NKE Marine Electronics" 1238 "SuperTrack Aps" 1239 "Honda Electronics" 1245 "Raritan Engineering" 1249 "Integrated Power Solutions AG" 1260 "Interactive Technologies" 1283 "LTG-Tech" 1299 "Energy Solutions (UK)" 1300 "WATT Fuel Cell" 1302 "Pro Mainer" 1305 "Dragonfly Energy" 1306 "Koden Electronics" 1311 "Humphree" 1316 "Hinkley Yachts" 1317 "Global Marine Management GmbH (GMM)" 1320 "Triskel Marine" 1330 "Warwick Control Technologies" 1331 "Dolphin Charger" 1337 "Barnacle Systems" 1348 "Radian IoT" 1353 "Ocean LED Marine" 1359 "BluNav" 1361 "OVA (Nantong Saiyang Electronics Co., Ltd)" 1368 "RAD Propulsion" 1369 "Electric Yacht" 1372 "Elco Motor Yachts" 1384 "Tecnoseal Foundry S.r.l" 1385 "Pro Charging Systems" 1389 "EVEX" 1398 "Gobius Sensor Technology" 1403 "Arco Marine" 1408 "Lenco Marine" 1413 "Naocontrol" 1417 "Revatek" 1438 "Aeolionics" 1439 "PredictWind" 1440 "Egis Mobile Electric" 1445 "Starboard Yacht Group" 1446 "Roswell Marine" 1451 "ePropulsion (Guangdong ePropulsion Technology Ltd.)" 1452 "Micro-Air" 1453 "Vital Battery" 1458 "Ride Controller" 1460 "Tocaro Blue" 1461 "Vanquish Yachts" 1471 "FT Technologies" 1478 "Alps Alpine" 1481 "E-Force Marine" 1482 "CMC Marine" 1483 "Nanjing Sandemarine Information Technology" 1850 "Teleflex Marine (SeaStar Solutions)" 1851 "Raymarine" 1852 "Navionics" 1853 "Japan Radio" 1854 "Northstar Technologies" 1855 "Furuno" 1856 "Trimble" 1857 "Simrad" 1858 "Litton" 1859 "Kvasar" 1860 "MMP" 1861 "Vector Cantech" 1862 "Yamaha Marine" 1863 "Faria Instruments" ;
VAL_ 2566849792 Industry_Code 0 "Global" 1 "Highway" 2 "Agriculture" 3 "Construction" 4 "Marine Industry" 5 "Industrial" ;
VAL_ 2566849792 Temperature_Source 0 "Sea Temperature" 1 "Outside Temperature" 2 "Inside Temperature" 3 "Engine Room Temperature" 4 "Main Cabin Temperature" 5 "Live Well Temperature" 6 "Bait Well Temperature" 7 "Refrigeration Temperature" 8 "Heating System Temperature" 9 "Dew Point Temperature" 10 "Apparent Wind Chill Temperature" 11 "Theoretical Wind Chill Temperature" 12 "Heat Index Temperature" 13 "Freezer Temperature" 14 "Exhaust Gas Temperature" 15 "Shaft Seal Temperature" ;
VAL_ 2566849792 Manufacturer_Code 69 "ARKS Enterprises" 78 "FW Murphy/Enovation Controls" 80 "Twin Disc" 85 "Kohler Power Systems" 88 "Hemisphere GPS" 135 "Airmar" 137 "Maretron" 140 "Lowrance" 144 "Mercury Marine" 147 "Nautibus Electronic" 148 "Blue Water Data" 154 "Westerbeke" 157 "ISSPRO" 161 "Offshore Systems (UK)" 163 "Evinrude/BRP" 165 "CPAC Systems" 168 "Xantrex Technology" 169 "Marlin Technologies" 172 "Yanmar Marine" 174 "Volvo Penta" 176 "Carling Technologies Inc. (Moritz Aerospace)" 185 "Beede Instruments" 192 "Floscan Instrument" 193 "Nobeltec" 198 "Mystic Valley Communications" 199 "Actia" 201 "Disenos Y Technologia" 211 "Digital Switching Systems" 215 "Xintex/Atena" 224 "EMMI NETWORK" 228 "ZF" 229 "Garmin" 233 "Yacht Monitoring Solutions" 235 "Sailormade Marine Telemetry/Tetra Technology" 243 "Eride" 257 "Honda Motor" 272 "Groco" 273 "Actisense" 274 "Amphenol LTW Technology" 275 "Navico" 283 "Hamilton Jet" 285 "Sea Recovery" 286 "Coelmo SRL Italy" 295 "BEP Marine" 304 "Empir Bus" 305 "NovAtel" 306 "Sleipner Motor" 307 "MBW Technologies" 315 "ICOM" 328 "Qwerty" 329 "Dief" 341 "Boening Automationstechnologie" 345 "Korean Maritime University" 351 "Thrane and Thrane" 355 "Mastervolt" 356 "Fischer Panda Generators" 358 "Victron Energy" 370 "Rolls Royce Marine" 373 "Electronic Design" 374 "Northern Lights" 378 "Glendinning" 381 "B & G" 384 "Rose Point Navigation Systems" 385 "Johnson Outdoors Marine Electronics Inc Geonav" 394 "Capi 2" 396 "Beyond Measure" 400 "Livorsi Marine" 404 "ComNav" 409 "Chetco" 419 "Fusion Electronics" 421 "Standard Horizon" 422 "True Heading" 426 "Egersund Marine Electronics" 427 "em-trak Marine Electronics" 431 "Tohatsu Co, JP" 437 "Digital Yacht" 438 "Comar Systems Limited" 440 "Cummins" 443 "VDO (aka Continental-Corporation)" 451 "Parker Hannifin aka Village Marine Tech" 459 "Alltek Marine Electronics" 460 "SAN GIORGIO S.E.I.N" 466 "Veethree Electronics & Marine" 470 "SI-TEX Marine Electronics" 471 "Sea Cross Marine" 475 "GME aka Standard Communications" 476 "Humminbird Marine Electronics" 478 "Ocean Sat" 481 "Chetco Digital Instruments" 493 "Watcheye" 499 "Lcj Capteurs" 502 "Attwood Marine" 503 "Naviop S.R.L." 504 "Vesper Marine" 510 "Marinesoft" 513 "Simarine" 517 "NoLand Engineering" 518 "Transas USA" 529 "National Instruments Korea" 530 "National Marine Electronics Association" 532 "Onwa Marine" 540 "Webasto" 571 "Marinecraft (South Korea)" 573 "McMurdo Group aka Orolia" 578 "Advansea" 579 "KVH" 580 "San Jose Technology" 583 "Yacht Control" 586 "Suzuki Motor" 591 "US Coast Guard" 595 "Ship Module aka Customware" 600 "Aquatic AV" 605 "Aventics" 606 "Intellian" 612 "SamwonIT" 614 "Arlt Tecnologies" 637 "Bavaria Yachts" 641 "Diverse Yacht Services" 644 "Wema U.S.A dba KUS" 658 "Shenzhen Jiuzhou Himunication" 688 "Rockford" 699 "Harman International" 704 "JL Audio" 708 "Lars Thrane" 715 "Autonnic" 717 "Yacht Devices" 734 "REAP Systems" 735 "AEM Performance Electronics" 739 "LxNav" 741 "Littelfuse, Inc (formerly Carling Technologies)" 743 "DaeMyung" 744 "Woosung" 748 "ISOTTA IFRA srl" 773 "Clarion US" 776 "HMI Systems" 777 "Ocean Signal" 778 "Seakeeper" 781 "Poly Planar" 785 "Fischer Panda DE" 795 "Broyda Industries" 796 "Canadian Automotive" 797 "Tides Marine" 798 "Lumishore" 799 "Still Water Designs and Audio" 802 "BJ Technologies (Beneteau)" 803 "Gill Sensors" 811 "Blue Water Desalination" 815 "FLIR" 824 "Undheim Systems" 826 "Lewmar" 838 "TeamSurv" 844 "Fell Marine" 847 "Oceanvolt" 862 "Prospec" 868 "Data Panel" 890 "L3 Technologies" 894 "Rhodan Marine Systems" 896 "Nexfour Solutions" 905 "ASA Electronics" 909 "Marines Co (South Korea)" 911 "Nautic-on" 917 "Sentinel" 929 "JL Marine Systems" 930 "Ecotronix" 944 "Zontisa Marine" 951 "EXOR International" 962 "Timbolier Industries" 963 "TJC Micro" 968 "Cox Powertrain" 969 "Blue Seas" 981 "Kobelt Manufacturing" 992 "Blue Ocean IOT" 997 "Xenta Systems" 999 "Signal K" 1004 "Ultraflex" 1008 "Lintest SmartBoat" 1011 "Soundmax" 1020 "Team Italia Marine (Onyx Marine Automation s.r.l)" 1021 "Entratech" 1022 "ITC" 1029 "The Marine Guardian" 1047 "Sonic" 1051 "ProNav" 1053 "Vetus Maxwell INC." 1056 "Lithium Pros" 1059 "Boatrax" 1062 "Marol Co ltd" 1065 "CALYPSO Instruments" 1066 "Spot Zero Water" 1069 "Lithionics Battery" 1070 "Quick-teck Electronics" 1075 "Uniden America" 1083 "Nauticoncept" 1084 "Shadow-Caster LED lighting" 1085 "Wet Sounds" 1088 "E-T-A Circuit Breakers" 1092 "Scheiber" 1100 "Smart Yachts International Limited" 1109 "Dockmate" 1114 "Bobs Machine" 1118 "L3Harris ASV" 1119 "Balmar" 1120 "Elettromedia" 1127 "Electromaax" 1140 "Across Oceans Systems" 1145 "Kiwi Yachting" 1150 "BSB Artificial Intelligence" 1151 "Orca Technologies" 1154 "TBS Electronics" 1158 "Technoton Electroics" 1160 "MG Energy Systems" 1169 "Sea Machine Robotics" 1171 "Vista Manufacturing" 1183 "Zipwake" 1186 "Sailmon" 1192 "Airmoniq Pro Kft" 1194 "Sierra Marine" 1200 "Xinuo Information Technology (Xiamen)" 1218 "Septentrio" 1233 "NKE Marine Electronics" 1238 "SuperTrack Aps" 1239 "Honda Electronics" 1245 "Raritan Engineering" 1249 "Integrated Power Solutions AG" 1260 "Interactive Technologies" 1283 "LTG-Tech" 1299 "Energy Solutions (UK)" 1300 "WATT Fuel Cell" 1302 "Pro Mainer" 1305 "Dragonfly Energy" 1306 "Koden Electronics" 1311 "Humphree" 1316 "Hinkley Yachts" 1317 "Global Marine Management GmbH (GMM)" 1320 "Triskel Marine" 1330 "Warwick Control Technologies" 1331 "Dolphin Charger" 1337 "Barnacle Systems" 1348 "Radian IoT" 1353 "Ocean LED Marine" 1359 "BluNav" 1361 "OVA (Nantong Saiyang Electronics Co., Ltd)" 1368 "RAD Propulsion" 1369 "Electric Yacht" 1372 "Elco Motor Yachts" 1384 "Tecnoseal Foundry S.r.l" 1385 "Pro Charging Systems" 1389 "EVEX" 1398 "Gobius Sensor Technology" 1403 "Arco Marine" 1408 "Lenco Marine" 1413 "Naocontrol" 1417 "Revatek" 1438 "Aeolionics" 1439 "PredictWind" 1440 "Egis Mobile Electric" 1445 "Starboard Yacht Group" 1446 "Roswell Marine" 1451 "ePropulsion (Guangdong ePropulsion Technology Ltd.)" 1452 "Micro-Air" 1453 "Vital Battery" 1458 "Ride Controller" 1460 "Tocaro Blue" 1461 "Vanquish Yachts" 1471 "FT Technologies" 1478 "Alps Alpine" 1481 "E-Force Marine" 1482 "CMC Marine" 1483 "Nanjing Sandemarine Information Technology" 1850 "Teleflex Marine (SeaStar Solutions)" 1851 "Raymarine" 1852 "Navionics" 1853 "Japan Radio" 1854 "Northstar Technologies" 1855 "Furuno" 1856 "Trimble" 1857 "Simrad" 1858 "Litton" 1859 "Kvasar" 1860 "MMP" 1861 "Vector Cantech" 1862 "Yamaha Marine" 1863 "Faria Instruments" ;
VAL_ 2566849792 Industry_Code 0 "Global" 1 "Highway" 2 "Agriculture" 3 "Construction" 4 "Marine Industry" 5 "Industrial" ;
VAL_ 2566850048 Manufacturer_Code 69 "ARKS Enterprises" 78 "FW Murphy/Enovation Controls" 80 "Twin Disc" 85 "Kohler Power Systems" 88 "Hemisphere GPS" 135 "Airmar" 137 "Maretron" 140 "Lowrance" 144 "Mercury Marine" 147 "Nautibus Electronic" 148 "Blue Water Data" 154 "Westerbeke" 157 "ISSPRO" 161 "Offshore Systems (UK)" 163 "Evinrude/BRP" 165 "CPAC Systems" 168 "Xantrex Technology" 169 "Marlin Technologies" 172 "Yanmar Marine" 174 "Volvo Penta" 176 "Carling Technologies Inc. (Moritz Aerospace)" 185 "Beede Instruments" 192 "Floscan Instrument" 193 "Nobeltec" 198 "Mystic Valley Communications" 199 "Actia" 201 "Disenos Y Technologia" 211 "Digital Switching Systems" 215 "Xintex/Atena" 224 "EMMI NETWORK" 228 "ZF" 229 "Garmin" 233 "Yacht Monitoring Solutions" 235 "Sailormade Marine Telemetry/Tetra Technology" 243 "Eride" 257 "Honda Motor" 272 "Groco" 273 "Actisense" 274 "Amphenol LTW Technology" 275 "Navico" 283 "Hamilton Jet" 285 "Sea Recovery" 286 "Coelmo SRL Italy" 295 "BEP Marine" 304 "Empir Bus" 305 "NovAtel" 306 "Sleipner Motor" 307 "MBW Technologies" 315 "ICOM" 328 "Qwerty" 329 "Dief" 341 "Boening Automationstechnologie" 345 "Korean Maritime University" 351 "Thrane and Thrane" 355 "Mastervolt" 356 "Fischer Panda Generators" 358 "Victron Energy" 370 "Rolls Royce Marine" 373 "Electronic Design" 374 "Northern Lights" 378 "Glendinning" 381 "B & G" 384 "Rose Point Navigation Systems" 385 "Johnson Outdoors Marine Electronics Inc Geonav" 394 "Capi 2" 396 "Beyond Measure" 400 "Livorsi Marine" 404 "ComNav" 409 "Chetco" 419 "Fusion Electronics" 421 "Standard Horizon" 422 "True Heading" 426 "Egersund Marine Electronics" 427 "em-trak Marine Electronics" 431 "Tohatsu Co, JP" 437 "Digital Yacht" 438 "Comar Systems Limited" 440 "Cummins" 443 "VDO (aka Continental-Corporation)" 451 "Parker Hannifin aka Village Marine Tech" 459 "Alltek Marine Electronics" 460 "SAN GIORGIO S.E.I.N" 466 "Veethree Electronics & Marine" 470 "SI-TEX Marine Electronics" 471 "Sea Cross Marine" 475 "GME aka Standard Communications" 476 "Humminbird Marine Electronics" 478 "Ocean Sat" 481 "Chetco Digital Instruments" 493 "Watcheye" 499 "Lcj Capteurs" 502 "Attwood Marine" 503 "Naviop S.R.L." 504 "Vesper Marine" 510 "Marinesoft" 513 "Simarine" 517 "NoLand Engineering" 518 "Transas USA" 529 "National Instruments Korea" 530 "National Marine Electronics Association" 532 "Onwa Marine" 540 "Webasto" 571 "Marinecraft (South Korea)" 573 "McMurdo Group aka Orolia" 578 "Advansea" 579 "KVH" 580 "San Jose Technology" 583 "Yacht Control" 586 "Suzuki Motor" 591 "US Coast Guard" 595 "Ship Module aka Customware" 600 "Aquatic AV" 605 "Aventics" 606 "Intellian" 612 "SamwonIT" 614 "Arlt Tecnologies" 637 "Bavaria Yachts" 641 "Diverse Yacht Services" 644 "Wema U.S.A dba KUS" 658 "Shenzhen Jiuzhou Himunication" 688 "Rockford" 699 "Harman International" 704 "JL Audio" 708 "Lars Thrane" 715 "Autonnic" 717 "Yacht Devices" 734 "REAP Systems" 735 "AEM Performance Electronics" 739 "LxNav" 741 "Littelfuse, Inc (formerly Carling Technologies)" 743 "DaeMyung" 744 "Woosung" 748 "ISOTTA IFRA srl" 773 "Clarion US" 776 "HMI Systems" 777 "Ocean Signal" 778 "Seakeeper" 781 "Poly Planar" 785 "Fischer Panda DE" 795 "Broyda Industries" 796 "Canadian Automotive" 797 "Tides Marine" 798 "Lumishore" 799 "Still Water Designs and Audio" 802 "BJ Technologies (Beneteau)" 803 "Gill Sensors" 811 "Blue Water Desalination" 815 "FLIR" 824 "Undheim Systems" 826 "Lewmar" 838 "TeamSurv" 844 "Fell Marine" 847 "Oceanvolt" 862 "Prospec" 868 "Data Panel" 890 "L3 Technologies" 894 "Rhodan Marine Systems" 896 "Nexfour Solutions" 905 "ASA Electronics" 909 "Marines Co (South Korea)" 911 "Nautic-on" 917 "Sentinel" 929 "JL Marine Systems" 930 "Ecotronix" 944 "Zontisa Marine" 951 "EXOR International" 962 "Timbolier Industries" 963 "TJC Micro" 968 "Cox Powertrain" 969 "Blue Seas" 981 "Kobelt Manufacturing" 992 "Blue Ocean IOT" 997 "Xenta Systems" 999 "Signal K" 1004 "Ultraflex" 1008 "Lintest SmartBoat" 1011 "Soundmax" 1020 "Team Italia Marine (Onyx Marine Automation s.r.l)" 1021 "Entratech" 1022 "ITC" 1029 "The Marine Guardian" 1047 "Sonic" 1051 "ProNav" 1053 "Vetus Maxwell INC." 1056 "Lithium Pros" 1059 "Boatrax" 1062 "Marol Co ltd" 1065 "CALYPSO Instruments" 1066 "Spot Zero Water" 1069 "Lithionics Battery" 1070 "Quick-teck Electronics" 1075 "Uniden America" 1083 "Nauticoncept" 1084 "Shadow-Caster LED lighting" 1085 "Wet Sounds" 1088 "E-T-A Circuit Breakers" 1092 "Scheiber" 1100 "Smart Yachts International Limited" 1109 "Dockmate" 1114 "Bobs Machine" 1118 "L3Harris ASV" 1119 "Balmar" 1120 "Elettromedia" 1127 "Electromaax" 1140 "Across Oceans Systems" 1145 "Kiwi Yachting" 1150 "BSB Artificial Intelligence" 1151 "Orca Technologies" 1154 "TBS Electronics" 1158 "Technoton Electroics" 1160 "MG Energy Systems" 1169 "Sea Machine Robotics" 1171 "Vista Manufacturing" 1183 "Zipwake" 1186 "Sailmon" 1192 "Airmoniq Pro Kft" 1194 "Sierra Marine" 1200 "Xinuo Information Technology (Xiamen)" 1218 "Septentrio" 1233 "NKE Marine Electronics" 1238 "SuperTrack Aps" 1239 "Honda Electronics" 1245 "Raritan Engineering" 1249 "Integrated Power Solutions AG" 1260 "Interactive Technologies" 1283 "LTG-Tech" 1299 "Energy Solutions (UK)" 1300 "WATT Fuel Cell" 1302 "Pro Mainer" 1305 "Dragonfly Energy" 1306 "Koden Electronics" 1311 "Humphree" 1316 "Hinkley Yachts" 1317 "Global Marine Management GmbH (GMM)" 1320 "Triskel Marine" 1330 "Warwick Control Technologies" 1331 "Dolphin Charger" 1337 "Barnacle Systems" 1348 "Radian IoT" 1353 "Ocean LED Marine" 1359 "BluNav" 1361 "OVA (Nantong Saiyang Electronics Co., Ltd)" 1368 "RAD Propulsion" 1369 "Electric Yacht" 1372 "Elco Motor Yachts" 1384 "Tecnoseal Foundry S.r.l" 1385 "Pro Charging Systems" 1389 "EVEX" 1398 "Gobius Sensor Technology" 1403 "Arco Marine" 1408 "Lenco Marine" 1413 "Naocontrol" 1417 "Revatek" 1438 "Aeolionics" 1439 "PredictWind" 1440 "Egis Mobile Electric" 1445 "Starboard Yacht Group" 1446 "Roswell Marine" 1451 "ePropulsion (Guangdong ePropulsion Technology Ltd.)" 1452 "Micro-Air" 1453 "Vital Battery" 1458 "Ride Controller" 1460 "Tocaro Blue" 1461 "Vanquish Yachts" 1471 "FT Technologies" 1478 "Alps Alpine" 1481 "E-Force Marine" 1482 "CMC Marine" 1483 "Nanjing Sandemarine Information Technology" 1850 "Teleflex Marine (SeaStar Solutions)" 1851 "Raymarine" 1852 "Navionics" 1853 "Japan Radio" 1854 "Northstar Technologies" 1855 "Furuno" 1856 "Trimble" 1857 "Simrad" 1858 "Litton" 1859 "Kvasar" 1860 "MMP" 1861 "Vector Cantech" 1862 "Yamaha Marine" 1863 "Faria Instruments" ;
VAL_ 2566850048 Industry_Code 0 "Global" 1 "Highway" 2 "Agriculture" 3 "Construction" 4 "Marine Industry" 5 "Industrial" ;
VAL_ 2566850048 Manufacturer_Code 69 "ARKS Enterprises" 78 "FW Murphy/Enovation Controls" 80 "Twin Disc" 85 "Kohler Power Systems" 88 "Hemisphere GPS" 135 "Airmar" 137 "Maretron" 140 "Lowrance" 144 "Mercury Marine" 147 "Nautibus Electronic" 148 "Blue Water Data" 154 "Westerbeke" 157 "ISSPRO" 161 "Offshore Systems (UK)" 163 "Evinrude/BRP" 165 "CPAC Systems" 168 "Xantrex Technology" 169 "Marlin Technologies" 172 "Yanmar Marine" 174 "Volvo Penta" 176 "Carling Technologies Inc. (Moritz Aerospace)" 185 "Beede Instruments" 192 "Floscan Instrument" 193 "Nobeltec" 198 "Mystic Valley Communications" 199 "Actia" 201 "Disenos Y Technologia" 211 "Digital Switching Systems" 215 "Xintex/Atena" 224 "EMMI NETWORK" 228 "ZF" 229 "Garmin" 233 "Yacht Monitoring Solutions" 235 "Sailormade Marine Telemetry/Tetra Technology" 243 "Eride" 257 "Honda Motor" 272 "Groco" 273 "Actisense" 274 "Amphenol LTW Technology" 275 "Navico" 283 "Hamilton Jet" 285 "Sea Recovery" 286 "Coelmo SRL Italy" 295 "BEP Marine" 304 "Empir Bus" 305 "NovAtel" 306 "Sleipner Motor" 307 "MBW Technologies" 315 "ICOM" 328 "Qwerty" 329 "Dief" 341 "Boening Automationstechnologie" 345 "Korean Maritime University" 351 "Thrane and Thrane" 355 "Mastervolt" 356 "Fischer Panda Generators" 358 "Victron Energy" 370 "Rolls Royce Marine" 373 "Electronic Design" 374 "Northern Lights" 378 "Glendinning" 381 "B & G" 384 "Rose Point Navigation Systems" 385 "Johnson Outdoors Marine Electronics Inc Geonav" 394 "Capi 2" 396 "Beyond Measure" 400 "Livorsi Marine" 404 "ComNav" 409 "Chetco" 419 "Fusion Electronics" 421 "Standard Horizon" 422 "True Heading" 426 "Egersund Marine Electronics" 427 "em-trak Marine Electronics" 431 "Tohatsu Co, JP" 437 "Digital Yacht" 438 "Comar Systems Limited" 440 "Cummins" 443 "VDO (aka Continental-Corporation)" 451 "Parker Hannifin aka Village Marine Tech" 459 "Alltek Marine Electronics" 460 "SAN GIORGIO S.E.I.N" 466 "Veethree Electronics & Marine" 470 "SI-TEX Marine Electronics" 471 "Sea Cross Marine" 475 "GME aka Standard Communications" 476 "Humminbird Marine Electronics" 478 "Ocean Sat" 481 "Chetco Digital Instruments" 493 "Watcheye" 499 "Lcj Capteurs" 502 "Attwood Marine" 503 "Naviop S.R.L." 504 "Vesper Marine" 510 "Marinesoft" 513 "Simarine" 517 "NoLand Engineering" 518 "Transas USA" 529 "National Instruments Korea" 530 "National Marine Electronics Association" 532 "Onwa Marine" 540 "Webasto" 571 "Marinecraft (South Korea)" 573 "McMurdo Group aka Orolia" 578 "Advansea" 579 "KVH" 580 "San Jose Technology" 583 "Yacht Control" 586 "Suzuki Motor" 591 "US Coast Guard" 595 "Ship Module aka Customware" 600 "Aquatic AV" 605 "Aventics" 606 "Intellian" 612 "SamwonIT" 614 "Arlt Tecnologies" 637 "Bavaria Yachts" 641 "Diverse Yacht Services" 644 "Wema U.S.A dba KUS" 658 "Shenzhen Jiuzhou Himunication" 688 "Rockford" 699 "Harman International" 704 "JL Audio" 708 "Lars Thrane" 715 "Autonnic" 717 "Yacht Devices" 734 "REAP Systems" 735 "AEM Performance Electronics" 739 "LxNav" 741 "Littelfuse, Inc (formerly Carling Technologies)" 743 "DaeMyung" 744 "Woosung" 748 "ISOTTA IFRA srl" 773 "Clarion US" 776 "HMI Systems" 777 "Ocean Signal" 778 "Seakeeper" 781 "Poly Planar" 785 "Fischer Panda DE" 795 "Broyda Industries" 796 "Canadian Automotive" 797 "Tides Marine" 798 "Lumishore" 799 "Still Water Designs and Audio" 802 "BJ Technologies (Beneteau)" 803 "Gill Sensors" 811 "Blue Water Desalination" 815 "FLIR" 824 "Undheim Systems" 826 "Lewmar" 838 "TeamSurv" 844 "Fell Marine" 847 "Oceanvolt" 862 "Prospec" 868 "Data Panel" 890 "L3 Technologies" 894 "Rhodan Marine Systems" 896 "Nexfour Solutions" 905 "ASA Electronics" 909 "Marines Co (South Korea)" 911 "Nautic-on" 917 "Sentinel" 929 "JL Marine Systems" 930 "Ecotronix" 944 "Zontisa Marine" 951 "EXOR International" 962 "Timbolier Industries" 963 "TJC Micro" 968 "Cox Powertrain" 969 "Blue Seas" 981 "Kobelt Manufacturing" 992 "Blue Ocean IOT" 997 "Xenta Systems" 999 "Signal K" 1004 "Ultraflex" 1008 "Lintest SmartBoat" 1011 "Soundmax" 1020 "Team Italia Marine (Onyx Marine Automation s.r.l)" 1021 "Entratech" 1022 "ITC" 1029 "The Marine Guardian" 1047 "Sonic" 1051 "ProNav" 1053 "Vetus Maxwell INC." 1056 "Lithium Pros" 1059 "Boatrax" 1062 "Marol Co ltd" 1065 "CALYPSO Instruments" 1066 "Spot Zero Water" 1069 "Lithionics Battery" 1070 "Quick-teck Electronics" 1075 "Uniden America" 1083 "Nauticoncept" 1084 "Shadow-Caster LED lighting" 1085 "Wet Sounds" 1088 "E-T-A Circuit Breakers" 1092 "Scheiber" 1100 "Smart Yachts International Limited" 1109 "Dockmate" 1114 "Bobs Machine" 1118 "L3Harris ASV" 1119 "Balmar" 1120 "Elettromedia" 1127 "Electromaax" 1140 "Across Oceans Systems" 1145 "Kiwi Yachting" 1150 "BSB Artificial Intelligence" 1151 "Orca Technologies" 1154 "TBS Electronics" 1158 "Technoton Electroics" 1160 "MG Energy Systems" 1169 "Sea Machine Robotics" 1171 "Vista Manufacturing" 1183 "Zipwake" 1186 "Sailmon" 1192 "Airmoniq Pro Kft" 1194 "Sierra Marine" 1200 "Xinuo Information Technology (Xiamen)" 1218 "Septentrio" 1233 "NKE Marine Electronics" 1238 "SuperTrack Aps" 1239 "Honda Electronics" 1245 "Raritan Engineering" 1249 "Integrated Power Solutions AG" 1260 "Interactive Technologies" 1283 "LTG-Tech" 1299 "Energy Solutions (UK)" 1300 "WATT Fuel Cell" 1302 "Pro Mainer" 1305 "Dragonfly Energy" 1306 "Koden Electronics" 1311 "Humphree" 1316 "Hinkley Yachts" 1317 "Global Marine Management GmbH (GMM)" 1320 "Triskel Marine" 1330 "Warwick Control Technologies" 1331 "Dolphin Charger" 1337 "Barnacle Systems" 1348 "Radian IoT" 1353 "Ocean LED Marine" 1359 "BluNav" 1361 "OVA (Nantong Saiyang Electronics Co., Ltd)" 1368 "RAD Propulsion" 1369 "Electric Yacht" 1372 "Elco Motor Yachts" 1384 "Tecnoseal Foundry S.r.l" 1385 "Pro Charging Systems" 1389 "EVEX" 1398 "Gobius Sensor Technology" 1403 "Arco Marine" 1408 "Lenco Marine" 1413 "Naocontrol" 1417 "Revatek" 1438 "Aeolionics" 1439 "PredictWind" 1440 "Egis Mobile Electric" 1445 "Starboard Yacht Group" 1446 "Roswell Marine" 1451 "ePropulsion (Guangdong ePropulsion Technology Ltd.)" 1452 "Micro-Air" 1453 "Vital Battery" 1458 "Ride Controller" 1460 "Tocaro Blue" 1461 "Vanquish Yachts" 1471 "FT Technologies" 1478 "Alps Alpine" 1481 "E-Force Marine" 1482 "CMC Marine" 1483 "Nanjing Sandemarine Information Technology" 1850 "Teleflex Marine (SeaStar Solutions)" 1851 "Raymarine" 1852 "Navionics" 1853 "Japan Radio" 1854 "Northstar Technologies" 1855 "Furuno" 1856 "Trimble" 1857 "Simrad" 1858 "Litton" 1859 "Kvasar" 1860 "MMP" 1861 "Vector Cantech" 1862 "Yamaha Marine" 1863 "Faria Instruments" ;
VAL_ 2566850048 Industry_Code 0 "Global" 1 "Highway" 2 "Agriculture" 3 "Construction" 4 "Marine Industry" 5 "Industrial" ;
VAL_ 2499741184 Manufacturer_Code 69 "ARKS Enterprises" 78 "FW Murphy/Enovation Controls" 80 "Twin Disc" 85 "Kohler Power Systems" 88 "Hemisphere GPS" 135 "Airmar" 137 "Maretron" 140 "Lowrance" 144 "Mercury Marine" 147 "Nautibus Electronic" 148 "Blue Water Data" 154 "Westerbeke" 157 "ISSPRO" 161 "Offshore Systems (UK)" 163 "Evinrude/BRP" 165 "CPAC Systems" 168 "Xantrex Technology" 169 "Marlin Technologies" 172 "Yanmar Marine" 174 "Volvo Penta" 176 "Carling Technologies Inc. (Moritz Aerospace)" 185 "Beede Instruments" 192 "Floscan Instrument" 193 "Nobeltec" 198 "Mystic Valley Communications" 199 "Actia" 201 "Disenos Y Technologia" 211 "Digital Switching Systems" 215 "Xintex/Atena" 224 "EMMI NETWORK" 228 "ZF" 229 "Garmin" 233 "Yacht Monitoring Solutions" 235 "Sailormade Marine Telemetry/Tetra Technology" 243 "Eride" 257 "Honda Motor" 272 "Groco" 273 "Actisense" 274 "Amphenol LTW Technology" 275 "Navico" 283 "Hamilton Jet" 285 "Sea Recovery" 286 "Coelmo SRL Italy" 295 "BEP Marine" 304 "Empir Bus" 305 "NovAtel" 306 "Sleipner Motor" 307 "MBW Technologies" 315 "ICOM" 328 "Qwerty" 329 "Dief" 341 "Boening Automationstechnologie" 345 "Korean Maritime University" 351 "Thrane and Thrane" 355 "Mastervolt" 356 "Fischer Panda Generators" 358 "Victron Energy" 370 "Rolls Royce Marine" 373 "Electronic Design" 374 "Northern Lights" 378 "Glendinning" 381 "B & G" 384 "Rose Point Navigation Systems" 385 "Johnson Outdoors Marine Electronics Inc Geonav" 394 "Capi 2" 396 "Beyond Measure" 400 "Livorsi Marine" 404 "ComNav" 409 "Chetco" 419 "Fusion Electronics" 421 "Standard Horizon" 422 "True Heading" 426 "Egersund Marine Electronics" 427 "em-trak Marine Electronics" 431 "Tohatsu Co, JP" 437 "Digital Yacht" 438 "Comar Systems Limited" 440 "Cummins" 443 "VDO (aka Continental-Corporation)" 451 "Parker Hannifin aka Village Marine Tech" 459 "Alltek Marine Electronics" 460 "SAN GIORGIO S.E.I.N" 466 "Veethree Electronics & Marine" 470 "SI-TEX Marine Electronics" 471 "Sea Cross Marine" 475 "GME aka Standard Communications" 476 "Humminbird Marine Electronics" 478 "Ocean Sat" 481 "Chetco Digital Instruments" 493 "Watcheye" 499 "Lcj Capteurs" 502 "Attwood Marine" 503 "Naviop S.R.L." 504 "Vesper Marine" 510 "Marinesoft" 513 "Simarine" 517 "NoLand Engineering" 518 "Transas USA" 529 "National Instruments Korea" 530 "National Marine Electronics Association" 532 "Onwa Marine" 540 "Webasto" 571 "Marinecraft (South Korea)" 573 "McMurdo Group aka Orolia" 578 "Advansea" 579 "KVH" 580 "San Jose Technology" 583 "Yacht Control" 586 "Suzuki Motor" 591 "US Coast Guard" 595 "Ship Module aka Customware" 600 "Aquatic AV" 605 "Aventics" 606 "Intellian" 612 "SamwonIT" 614 "Arlt Tecnologies" 637 "Bavaria Yachts" 641 "Diverse Yacht Services" 644 "Wema U.S.A dba KUS" 658 "Shenzhen Jiuzhou Himunication" 688 "Rockford" 699 "Harman International" 704 "JL Audio" 708 "Lars Thrane" 715 "Autonnic" 717 "Yacht Devices" 734 "REAP Systems" 735 "AEM Performance Electronics" 739 "LxNav" 741 "Littelfuse, Inc (formerly Carling Technologies)" 743 "DaeMyung" 744 "Woosung" 748 "ISOTTA IFRA srl" 773 "Clarion US" 776 "HMI Systems" 777 "Ocean Signal" 778 "Seakeeper" 781 "Poly Planar" 785 "Fischer Panda DE" 795 "Broyda Industries" 796 "Canadian Automotive" 797 "Tides Marine" 798 "Lumishore" 799 "Still Water Designs and Audio" 802 "BJ Technologies (Beneteau)" 803 "Gill Sensors" 811 "Blue Water Desalination" 815 "FLIR" 824 "Undheim Systems" 826 "Lewmar" 838 "TeamSurv" 844 "Fell Marine" 847 "Oceanvolt" 862 "Prospec" 868 "Data Panel" 890 "L3 Technologies" 894 "Rhodan Marine Systems" 896 "Nexfour Solutions" 905 "ASA Electronics" 909 "Marines Co (South Korea)" 911 "Nautic-on" 917 "Sentinel" 929 "JL Marine Systems" 930 "Ecotronix" 944 "Zontisa Marine" 951 "EXOR International" 962 "Timbolier Industries" 963 "TJC Micro" 968 "Cox Powertrain" 969 "Blue Seas" 981 "Kobelt Manufacturing" 992 "Blue Ocean IOT" 997 "Xenta Systems" 999 "Signal K" 1004 "Ultraflex" 1008 "Lintest SmartBoat" 1011 "Soundmax" 1020 "Team Italia Marine (Onyx Marine Automation s.r.l)" 1021 "Entratech" 1022 "ITC" 1029 "The Marine Guardian" 1047 "Sonic" 1051 "ProNav" 1053 "Vetus Maxwell INC." 1056 "Lithium Pros" 1059 "Boatrax" 1062 "Marol Co ltd" 1065 "CALYPSO Instruments" 1066 "Spot Zero Water" 1069 "Lithionics Battery" 1070 "Quick-teck Electronics" 1075 "Uniden America" 1083 "Nauticoncept" 1084 "Shadow-Caster LED lighting" 1085 "Wet Sounds" 1088 "E-T-A Circuit Breakers" 1092 "Scheiber" 1100 "Smart Yachts International Limited" 1109 "Dockmate" 1114 "Bobs Machine" 1118 "L3Harris ASV" 1119 "Balmar" 1120 "Elettromedia" 1127 "Electromaax" 1140 "Across Oceans Systems" 1145 "Kiwi Yachting" 1150 "BSB Artificial Intelligence" 1151 "Orca Technologies" 1154 "TBS Electronics" 1158 "Technoton Electroics" 1160 "MG Energy Systems" 1169 "Sea Machine Robotics" 1171 "Vista Manufacturing" 1183 "Zipwake" 1186 "Sailmon" 1192 "Airmoniq Pro Kft" 1194 "Sierra Marine" 1200 "Xinuo Information Technology (Xiamen)" 1218 "Septentrio" 1233 "NKE Marine Electronics" 1238 "SuperTrack Aps" 1239 "Honda Electronics" 1245 "Raritan Engineering" 1249 "Integrated Power Solutions AG" 1260 "Interactive Technologies" 1283 "LTG-Tech" 1299 "Energy Solutions (UK)" 1300 "WATT Fuel Cell" 1302 "Pro Mainer" 1305 "Dragonfly Energy" 1306 "Koden Electronics" 1311 "Humphree" 1316 "Hinkley Yachts" 1317 "Global Marine Management GmbH (GMM)" 1320 "Triskel Marine" 1330 "Warwick Control Technologies" 1331 "Dolphin Charger" 1337 "Barnacle Systems" 1348 "Radian IoT" 1353 "Ocean LED Marine" 1359 "BluNav" 1361 "OVA (Nantong Saiyang Electronics Co., Ltd)" 1368 "RAD Propulsion" 1369 "Electric Yacht" 1372 "Elco Motor Yachts" 1384 "Tecnoseal Foundry S.r.l" 1385 "Pro Charging Systems" 1389 "EVEX" 1398 "Gobius Sensor Technology" 1403 "Arco Marine" 1408 "Lenco Marine" 1413 "Naocontrol" 1417 "Revatek" 1438 "Aeolionics" 1439 "PredictWind" 1440 "Egis Mobile Electric" 1445 "Starboard Yacht Group" 1446 "Roswell Marine" 1451 "ePropulsion (Guangdong ePropulsion Technology Ltd.)" 1452 "Micro-Air" 1453 "Vital Battery" 1458 "Ride Controller" 1460 "Tocaro Blue" 1461 "Vanquish Yachts" 1471 "FT Technologies" 1478 "Alps Alpine" 1481 "E-Force Marine" 1482 "CMC Marine" 1483 "Nanjing Sandemarine Information Technology" 1850 "Teleflex Marine (SeaStar Solutions)" 1851 "Raymarine" 1852 "Navionics" 1853 "Japan Radio" 1854 "Northstar Technologies" 1855 "Furuno" 1856 "Trimble" 1857 "Simrad" 1858 "Litton" 1859 "Kvasar" 1860 "MMP" 1861 "Vector Cantech" 1862 "Yamaha Marine" 1863 "Faria Instruments" ;
VAL_ 2499741184 Industry_Code 0 "Global" 1 "Highway" 2 "Agriculture" 3 "Construction" 4 "Marine Industry" 5 "Industrial" ;
VAL_ 2499741184 Fluid_Type 0 "Fuel" 1 "Water" 2 "Gray water" 3 "Live well" 4 "Oil" 5 "Black water" ;
VAL_ 2566850304 Manufacturer_Code 69 "ARKS Enterprises" 78 "FW Murphy/Enovation Controls" 80 "Twin Disc" 85 "Kohler Power Systems" 88 "Hemisphere GPS" 135 "Airmar" 137 "Maretron" 140 "Lowrance" 144 "Mercury Marine" 147 "Nautibus Electronic" 148 "Blue Water Data" 154 "Westerbeke" 157 "ISSPRO" 161 "Offshore Systems (UK)" 163 "Evinrude/BRP" 165 "CPAC Systems" 168 "Xantrex Technology" 169 "Marlin Technologies" 172 "Yanmar Marine" 174 "Volvo Penta" 176 "Carling Technologies Inc. (Moritz Aerospace)" 185 "Beede Instruments" 192 "Floscan Instrument" 193 "Nobeltec" 198 "Mystic Valley Communications" 199 "Actia" 201 "Disenos Y Technologia" 211 "Digital Switching Systems" 215 "Xintex/Atena" 224 "EMMI NETWORK" 228 "ZF" 229 "Garmin" 233 "Yacht Monitoring Solutions" 235 "Sailormade Marine Telemetry/Tetra Technology" 243 "Eride" 257 "Honda Motor" 272 "Groco" 273 "Actisense" 274 "Amphenol LTW Technology" 275 "Navico" 283 "Hamilton Jet" 285 "Sea Recovery" 286 "Coelmo SRL Italy" 295 "BEP Marine" 304 "Empir Bus" 305 "NovAtel" 306 "Sleipner Motor" 307 "MBW Technologies" 315 "ICOM" 328 "Qwerty" 329 "Dief" 341 "Boening Automationstechnologie" 345 "Korean Maritime University" 351 "Thrane and Thrane" 355 "Mastervolt" 356 "Fischer Panda Generators" 358 "Victron Energy" 370 "Rolls Royce Marine" 373 "Electronic Design" 374 "Northern Lights" 378 "Glendinning" 381 "B & G" 384 "Rose Point Navigation Systems" 385 "Johnson Outdoors Marine Electronics Inc Geonav" 394 "Capi 2" 396 "Beyond Measure" 400 "Livorsi Marine" 404 "ComNav" 409 "Chetco" 419 "Fusion Electronics" 421 "Standard Horizon" 422 "True Heading" 426 "Egersund Marine Electronics" 427 "em-trak Marine Electronics" 431 "Tohatsu Co, JP" 437 "Digital Yacht" 438 "Comar Systems Limited" 440 "Cummins" 443 "VDO (aka Continental-Corporation)" 451 "Parker Hannifin aka Village Marine Tech" 459 "Alltek Marine Electronics" 460 "SAN GIORGIO S.E.I.N" 466 "Veethree Electronics & Marine" 470 "SI-TEX Marine Electronics" 471 "Sea Cross Marine" 475 "GME aka Standard Communications" 476 "Humminbird Marine Electronics" 478 "Ocean Sat" 481 "Chetco Digital Instruments" 493 "Watcheye" 499 "Lcj Capteurs" 502 "Attwood Marine" 503 "Naviop S.R.L." 504 "Vesper Marine" 510 "Marinesoft" 513 "Simarine" 517 "NoLand Engineering" 518 "Transas USA" 529 "National Instruments Korea" 530 "National Marine Electronics Association" 532 "Onwa Marine" 540 "Webasto" 571 "Marinecraft (South Korea)" 573 "McMurdo Group aka Orolia" 578 "Advansea" 579 "KVH" 580 "San Jose Technology" 583 "Yacht Control" 586 "Suzuki Motor" 591 "US Coast Guard" 595 "Ship Module aka Customware" 600 "Aquatic AV" 605 "Aventics" 606 "Intellian" 612 "SamwonIT" 614 "Arlt Tecnologies" 637 "Bavaria Yachts" 641 "Diverse Yacht Services" 644 "Wema U.S.A dba KUS" 658 "Shenzhen Jiuzhou Himunication" 688 "Rockford" 699 "Harman International" 704 "JL Audio" 708 "Lars Thrane" 715 "Autonnic" 717 "Yacht Devices" 734 "REAP Systems" 735 "AEM Performance Electronics" 739 "LxNav" 741 "Littelfuse, Inc (formerly Carling Technologies)" 743 "DaeMyung" 744 "Woosung" 748 "ISOTTA IFRA srl" 773 "Clarion US" 776 "HMI Systems" 777 "Ocean Signal" 778 "Seakeeper" 781 "Poly Planar" 785 "Fischer Panda DE" 795 "Broyda Industries" 796 "Canadian Automotive" 797 "Tides Marine" 798 "Lumishore" 799 "Still Water Designs and Audio" 802 "BJ Technologies (Beneteau)" 803 "Gill Sensors" 811 "Blue Water Desalination" 815 "FLIR" 824 "Undheim Systems" 826 "Lewmar" 838 "TeamSurv" 844 "Fell Marine" 847 "Oceanvolt" 862 "Prospec" 868 "Data Panel" 890 "L3 Technologies" 894 "Rhodan Marine Systems" 896 "Nexfour Solutions" 905 "ASA Electronics" 909 "Marines Co (South Korea)" 911 "Nautic-on" 917 "Sentinel" 929 "JL Marine Systems" 930 "Ecotronix" 944 "Zontisa Marine" 951 "EXOR International" 962 "Timbolier Industries" 963 "TJC Micro" 968 "Cox Powertrain" 969 "Blue Seas" 981 "Kobelt Manufacturing" 992 "Blue Ocean IOT" 997 "Xenta Systems" 999 "Signal K" 1004 "Ultraflex" 1008 "Lintest SmartBoat" 1011 "Soundmax" 1020 "Team Italia Marine (Onyx Marine Automation s.r.l)" 1021 "Entratech" 1022 "ITC" 1029 "The Marine Guardian" 1047 "Sonic" 1051 "ProNav" 1053 "Vetus Maxwell INC." 1056 "Lithium Pros" 1059 "Boatrax" 1062 "Marol Co ltd" 1065 "CALYPSO Instruments" 1066 "Spot Zero Water" 1069 "Lithionics Battery" 1070 "Quick-teck Electronics" 1075 "Uniden America" 1083 "Nauticoncept" 1084 "Shadow-Caster LED lighting" 1085 "Wet Sounds" 1088 "E-T-A Circuit Breakers" 1092 "Scheiber" 1100 "Smart Yachts International Limited" 1109 "Dockmate" 1114 "Bobs Machine" 1118 "L3Harris ASV" 1119 "Balmar" 1120 "Elettromedia" 1127 "Electromaax" 1140 "Across Oceans Systems" 1145 "Kiwi Yachting" 1150 "BSB Artificial Intelligence" 1151 "Orca Technologies" 1154 "TBS Electronics" 1158 "Technoton Electroics" 1160 "MG Energy Systems" 1169 "Sea Machine Robotics" 1171 "Vista Manufacturing" 1183 "Zipwake" 1186 "Sailmon" 1192 "Airmoniq Pro Kft" 1194 "Sierra Marine" 1200 "Xinuo Information Technology (Xiamen)" 1218 "Septentrio" 1233 "NKE Marine Electronics" 1238 "SuperTrack Aps" 1239 "Honda Electronics" 1245 "Raritan Engineering" 1249 "Integrated Power Solutions AG" 1260 "Interactive Technologies" 1283 "LTG-Tech" 1299 "Energy Solutions (UK)" 1300 "WATT Fuel Cell" 1302 "Pro Mainer" 1305 "Dragonfly Energy" 1306 "Koden Electronics" 1311 "Humphree" 1316 "Hinkley Yachts" 1317 "Global Marine Management GmbH (GMM)" 1320 "Triskel Marine" 1330 "Warwick Control Technologies" 1331 "Dolphin Charger" 1337 "Barnacle Systems" 1348 "Radian IoT" 1353 "Ocean LED Marine" 1359 "BluNav" 1361 "OVA (Nantong Saiyang Electronics Co., Ltd)" 1368 "RAD Propulsion" 1369 "Electric Yacht" 1372 "Elco Motor Yachts" 1384 "Tecnoseal Foundry S.r.l" 1385 "Pro Charging Systems" 1389 "EVEX" 1398 "Gobius Sensor Technology" 1403 "Arco Marine" 1408 "Lenco Marine" 1413 "Naocontrol" 1417 "Revatek" 1438 "Aeolionics" 1439 "PredictWind" 1440 "Egis Mobile Electric" 1445 "Starboard Yacht Group" 1446 "Roswell Marine" 1451 "ePropulsion (Guangdong ePropulsion Technology Ltd.)" 1452 "Micro-Air" 1453 "Vital Battery" 1458 "Ride Controller" 1460 "Tocaro Blue" 1461 "Vanquish Yachts" 1471 "FT Technologies" 1478 "Alps Alpine" 1481 "E-Force Marine" 1482 "CMC Marine" 1483 "Nanjing Sandemarine Information Technology" 1850 "Teleflex Marine (SeaStar Solutions)" 1851 "Raymarine" 1852 "Navionics" 1853 "Japan Radio" 1854 "Northstar Technologies" 1855 "Furuno" 1856 "Trimble" 1857 "Simrad" 1858 "Litton" 1859 "Kvasar" 1860 "MMP" 1861 "Vector Cantech" 1862 "Yamaha Marine" 1863 "Faria Instruments" ;
VAL_ 2566850304 Industry_Code 0 "Global" 1 "Highway" 2 "Agriculture" 3 "Construction" 4 "Marine Industry" 5 "Industrial" ;
VAL_ 2566850304 Access_Level 0 "Locked" 1 "unlocked level 1" 2 "unlocked level 2" ;
VAL_ 2499741440 Manufacturer_Code 69 "ARKS Enterprises" 78 "FW Murphy/Enovation Controls" 80 "Twin Disc" 85 "Kohler Power Systems" 88 "Hemisphere GPS" 135 "Airmar" 137 "Maretron" 140 "Lowrance" 144 "Mercury Marine" 147 "Nautibus Electronic" 148 "Blue Water Data" 154 "Westerbeke" 157 "ISSPRO" 161 "Offshore Systems (UK)" 163 "Evinrude/BRP" 165 "CPAC Systems" 168 "Xantrex Technology" 169 "Marlin Technologies" 172 "Yanmar Marine" 174 "Volvo Penta" 176 "Carling Technologies Inc. (Moritz Aerospace)" 185 "Beede Instruments" 192 "Floscan Instrument" 193 "Nobeltec" 198 "Mystic Valley Communications" 199 "Actia" 201 "Disenos Y Technologia" 211 "Digital Switching Systems" 215 "Xintex/Atena" 224 "EMMI NETWORK" 228 "ZF" 229 "Garmin" 233 "Yacht Monitoring Solutions" 235 "Sailormade Marine Telemetry/Tetra Technology" 243 "Eride" 257 "Honda Motor" 272 "Groco" 273 "Actisense" 274 "Amphenol LTW Technology" 275 "Navico" 283 "Hamilton Jet" 285 "Sea Recovery" 286 "Coelmo SRL Italy" 295 "BEP Marine" 304 "Empir Bus" 305 "NovAtel" 306 "Sleipner Motor" 307 "MBW Technologies" 315 "ICOM" 328 "Qwerty" 329 "Dief" 341 "Boening Automationstechnologie" 345 "Korean Maritime University" 351 "Thrane and Thrane" 355 "Mastervolt" 356 "Fischer Panda Generators" 358 "Victron Energy" 370 "Rolls Royce Marine" 373 "Electronic Design" 374 "Northern Lights" 378 "Glendinning" 381 "B & G" 384 "Rose Point Navigation Systems" 385 "Johnson Outdoors Marine Electronics Inc Geonav" 394 "Capi 2" 396 "Beyond Measure" 400 "Livorsi Marine" 404 "ComNav" 409 "Chetco" 419 "Fusion Electronics" 421 "Standard Horizon" 422 "True Heading" 426 "Egersund Marine Electronics" 427 "em-trak Marine Electronics" 431 "Tohatsu Co, JP" 437 "Digital Yacht" 438 "Comar Systems Limited" 440 "Cummins" 443 "VDO (aka Continental-Corporation)" 451 "Parker Hannifin aka Village Marine Tech" 459 "Alltek Marine Electronics" 460 "SAN GIORGIO S.E.I.N" 466 "Veethree Electronics & Marine" 470 "SI-TEX Marine Electronics" 471 "Sea Cross Marine" 475 "GME aka Standard Communications" 476 "Humminbird Marine Electronics" 478 "Ocean Sat" 481 "Chetco Digital Instruments" 493 "Watcheye" 499 "Lcj Capteurs" 502 "Attwood Marine" 503 "Naviop S.R.L." 504 "Vesper Marine" 510 "Marinesoft" 513 "Simarine" 517 "NoLand Engineering" 518 "Transas USA" 529 "National Instruments Korea" 530 "National Marine Electronics Association" 532 "Onwa Marine" 540 "Webasto" 571 "Marinecraft (South Korea)" 573 "McMurdo Group aka Orolia" 578 "Advansea" 579 "KVH" 580 "San Jose Technology" 583 "Yacht Control" 586 "Suzuki Motor" 591 "US Coast Guard" 595 "Ship Module aka Customware" 600 "Aquatic AV" 605 "Aventics" 606 "Intellian" 612 "SamwonIT" 614 "Arlt Tecnologies" 637 "Bavaria Yachts" 641 "Diverse Yacht Services" 644 "Wema U.S.A dba KUS" 658 "Shenzhen Jiuzhou Himunication" 688 "Rockford" 699 "Harman International" 704 "JL Audio" 708 "Lars Thrane" 715 "Autonnic" 717 "Yacht Devices" 734 "REAP Systems" 735 "AEM Performance Electronics" 739 "LxNav" 741 "Littelfuse, Inc (formerly Carling Technologies)" 743 "DaeMyung" 744 "Woosung" 748 "ISOTTA IFRA srl" 773 "Clarion US" 776 "HMI Systems" 777 "Ocean Signal" 778 "Seakeeper" 781 "Poly Planar" 785 "Fischer Panda DE" 795 "Broyda Industries" 796 "Canadian Automotive" 797 "Tides Marine" 798 "Lumishore" 799 "Still Water Designs and Audio" 802 "BJ Technologies (Beneteau)" 803 "Gill Sensors" 811 "Blue Water Desalination" 815 "FLIR" 824 "Undheim Systems" 826 "Lewmar" 838 "TeamSurv" 844 "Fell Marine" 847 "Oceanvolt" 862 "Prospec" 868 "Data Panel" 890 "L3 Technologies" 894 "Rhodan Marine Systems" 896 "Nexfour Solutions" 905 "ASA Electronics" 909 "Marines Co (South Korea)" 911 "Nautic-on" 917 "Sentinel" 929 "JL Marine Systems" 930 "Ecotronix" 944 "Zontisa Marine" 951 "EXOR International" 962 "Timbolier Industries" 963 "TJC Micro" 968 "Cox Powertrain" 969 "Blue Seas" 981 "Kobelt Manufacturing" 992 "Blue Ocean IOT" 997 "Xenta Systems" 999 "Signal K" 1004 "Ultraflex" 1008 "Lintest SmartBoat" 1011 "Soundmax" 1020 "Team Italia Marine (Onyx Marine Automation s.r.l)" 1021 "Entratech" 1022 "ITC" 1029 "The Marine Guardian" 1047 "Sonic" 1051 "ProNav" 1053 "Vetus Maxwell INC." 1056 "Lithium Pros" 1059 "Boatrax" 1062 "Marol Co ltd" 1065 "CALYPSO Instruments" 1066 "Spot Zero Water" 1069 "Lithionics Battery" 1070 "Quick-teck Electronics" 1075 "Uniden America" 1083 "Nauticoncept" 1084 "Shadow-Caster LED lighting" 1085 "Wet Sounds" 1088 "E-T-A Circuit Breakers" 1092 "Scheiber" 1100 "Smart Yachts International Limited" 1109 "Dockmate" 1114 "Bobs Machine" 1118 "L3Harris ASV" 1119 "Balmar" 1120 "Elettromedia" 1127 "Electromaax" 1140 "Across Oceans Systems" 1145 "Kiwi Yachting" 1150 "BSB Artificial Intelligence" 1151 "Orca Technologies" 1154 "TBS Electronics" 1158 "Technoton Electroics" 1160 "MG Energy Systems" 1169 "Sea Machine Robotics" 1171 "Vista Manufacturing" 1183 "Zipwake" 1186 "Sailmon" 1192 "Airmoniq Pro Kft" 1194 "Sierra Marine" 1200 "Xinuo Information Technology (Xiamen)" 1218 "Septentrio" 1233 "NKE Marine Electronics" 1238 "SuperTrack Aps" 1239 "Honda Electronics" 1245 "Raritan Engineering" 1249 "Integrated Power Solutions AG" 1260 "Interactive Technologies" 1283 "LTG-Tech" 1299 "Energy Solutions (UK)" 1300 "WATT Fuel Cell" 1302 "Pro Mainer" 1305 "Dragonfly Energy" 1306 "Koden Electronics" 1311 "Humphree" 1316 "Hinkley Yachts" 1317 "Global Marine Management GmbH (GMM)" 1320 "Triskel Marine" 1330 "Warwick Control Technologies" 1331 "Dolphin Charger" 1337 "Barnacle Systems" 1348 "Radian IoT" 1353 "Ocean LED Marine" 1359 "BluNav" 1361 "OVA (Nantong Saiyang Electronics Co., Ltd)" 1368 "RAD Propulsion" 1369 "Electric Yacht" 1372 "Elco Motor Yachts" 1384 "Tecnoseal Foundry S.r.l" 1385 "Pro Charging Systems" 1389 "EVEX" 1398 "Gobius Sensor Technology" 1403 "Arco Marine" 1408 "Lenco Marine" 1413 "Naocontrol" 1417 "Revatek" 1438 "Aeolionics" 1439 "PredictWind" 1440 "Egis Mobile Electric" 1445 "Starboard Yacht Group" 1446 "Roswell Marine" 1451 "ePropulsion (Guangdong ePropulsion Technology Ltd.)" 1452 "Micro-Air" 1453 "Vital Battery" 1458 "Ride Controller" 1460 "Tocaro Blue" 1461 "Vanquish Yachts" 1471 "FT Technologies" 1478 "Alps Alpine" 1481 "E-Force Marine" 1482 "CMC Marine" 1483 "Nanjing Sandemarine Information Technology" 1850 "Teleflex Marine (SeaStar Solutions)" 1851 "Raymarine" 1852 "Navionics" 1853 "Japan Radio" 1854 "Northstar Technologies" 1855 "Furuno" 1856 "Trimble" 1857 "Simrad" 1858 "Litton" 1859 "Kvasar" 1860 "MMP" 1861 "Vector Cantech" 1862 "Yamaha Marine" 1863 "Faria Instruments" ;
VAL_ 2499741440 Industry_Code 0 "Global" 1 "Highway" 2 "Agriculture" 3 "Construction" 4 "Marine Industry" 5 "Industrial" ;
VAL_ 2499741440 Fluid_Type 0 "Fuel" 1 "Water" 2 "Gray water" 3 "Live well" 4 "Oil" 5 "Black water" ;
VAL_ 2566850304 Manufacturer_Code 69 "ARKS Enterprises" 78 "FW Murphy/Enovation Controls" 80 "Twin Disc" 85 "Kohler Power Systems" 88 "Hemisphere GPS" 135 "Airmar" 137 "Maretron" 140 "Lowrance" 144 "Mercury Marine" 147 "Nautibus Electronic" 148 "Blue Water Data" 154 "Westerbeke" 157 "ISSPRO" 161 "Offshore Systems (UK)" 163 "Evinrude/BRP" 165 "CPAC Systems" 168 "Xantrex Technology" 169 "Marlin Technologies" 172 "Yanmar Marine" 174 "Volvo Penta" 176 "Carling Technologies Inc. (Moritz Aerospace)" 185 "Beede Instruments" 192 "Floscan Instrument" 193 "Nobeltec" 198 "Mystic Valley Communications" 199 "Actia" 201 "Disenos Y Technologia" 211 "Digital Switching Systems" 215 "Xintex/Atena" 224 "EMMI NETWORK" 228 "ZF" 229 "Garmin" 233 "Yacht Monitoring Solutions" 235 "Sailormade Marine Telemetry/Tetra Technology" 243 "Eride" 257 "Honda Motor" 272 "Groco" 273 "Actisense" 274 "Amphenol LTW Technology" 275 "Navico" 283 "Hamilton Jet" 285 "Sea Recovery" 286 "Coelmo SRL Italy" 295 "BEP Marine" 304 "Empir Bus" 305 "NovAtel" 306 "Sleipner Motor" 307 "MBW Technologies" 315 "ICOM" 328 "Qwerty" 329 "Dief" 341 "Boening Automationstechnologie" 345 "Korean Maritime University" 351 "Thrane and Thrane" 355 "Mastervolt" 356 "Fischer Panda Generators" 358 "Victron Energy" 370 "Rolls Royce Marine" 373 "Electronic Design" 374 "Northern Lights" 378 "Glendinning" 381 "B & G" 384 "Rose Point Navigation Systems" 385 "Johnson Outdoors Marine Electronics Inc Geonav" 394 "Capi 2" 396 "Beyond Measure" 400 "Livorsi Marine" 404 "ComNav" 409 "Chetco" 419 "Fusion Electronics" 421 "Standard Horizon" 422 "True Heading" 426 "Egersund Marine Electronics" 427 "em-trak Marine Electronics" 431 "Tohatsu Co, JP" 437 "Digital Yacht" 438 "Comar Systems Limited" 440 "Cummins" 443 "VDO (aka Continental-Corporation)" 451 "Parker Hannifin aka Village Marine Tech" 459 "Alltek Marine Electronics" 460 "SAN GIORGIO S.E.I.N" 466 "Veethree Electronics & Marine" 470 "SI-TEX Marine Electronics" 471 "Sea Cross Marine" 475 "GME aka Standard Communications" 476 "Humminbird Marine Electronics" 478 "Ocean Sat" 481 "Chetco Digital Instruments" 493 "Watcheye" 499 "Lcj Capteurs" 502 "Attwood Marine" 503 "Naviop S.R.L." 504 "Vesper Marine" 510 "Marinesoft" 513 "Simarine" 517 "NoLand Engineering" 518 "Transas USA" 529 "National Instruments Korea" 530 "National Marine Electronics Association" 532 "Onwa Marine" 540 "Webasto" 571 "Marinecraft (South Korea)" 573 "McMurdo Group aka Orolia" 578 "Advansea" 579 "KVH" 580 "San Jose Technology" 583 "Yacht Control" 586 "Suzuki Motor" 591 "US Coast Guard" 595 "Ship Module aka Customware" 600 "Aquatic AV" 605 "Aventics" 606 "Intellian" 612 "SamwonIT" 614 "Arlt Tecnologies" 637 "Bavaria Yachts" 641 "Diverse Yacht Services" 644 "Wema U.S.A dba KUS" 658 "Shenzhen Jiuzhou Himunication" 688 "Rockford" 699 "Harman International" 704 "JL Audio" 708 "Lars Thrane" 715 "Autonnic" 717 "Yacht Devices" 734 "REAP Systems" 735 "AEM Performance Electronics" 739 "LxNav" 741 "Littelfuse, Inc (formerly Carling Technologies)" 743 "DaeMyung" 744 "Woosung" 748 "ISOTTA IFRA srl" 773 "Clarion US" 776 "HMI Systems" 777 "Ocean Signal" 778 "Seakeeper" 781 "Poly Planar" 785 "Fischer Panda DE" 795 "Broyda Industries" 796 "Canadian Automotive" 797 "Tides Marine" 798 "Lumishore" 799 "Still Water Designs and Audio" 802 "BJ Technologies (Beneteau)" 803 "Gill Sensors" 811 "Blue Water Desalination" 815 "FLIR" 824 "Undheim Systems" 826 "Lewmar" 838 "TeamSurv" 844 "Fell Marine" 847 "Oceanvolt" 862 "Prospec" 868 "Data Panel" 890 "L3 Technologies" 894 "Rhodan Marine Systems" 896 "Nexfour Solutions" 905 "ASA Electronics" 909 "Marines Co (South Korea)" 911 "Nautic-on" 917 "Sentinel" 929 "JL Marine Systems" 930 "Ecotronix" 944 "Zontisa Marine" 951 "EXOR International" 962 "Timbolier Industries" 963 "TJC Micro" 968 "Cox Powertrain" 969 "Blue Seas" 981 "Kobelt Manufacturing" 992 "Blue Ocean IOT" 997 "Xenta Systems" 999 "Signal K" 1004 "Ultraflex" 1008 "Lintest SmartBoat" 1011 "Soundmax" 1020 "Team Italia Marine (Onyx Marine Automation s.r.l)" 1021 "Entratech" 1022 "ITC" 1029 "The Marine Guardian" 1047 "Sonic" 1051 "ProNav" 1053 "Vetus Maxwell INC." 1056 "Lithium Pros" 1059 "Boatrax" 1062 "Marol Co ltd" 1065 "CALYPSO Instruments" 1066 "Spot Zero Water" 1069 "Lithionics Battery" 1070 "Quick-teck Electronics" 1075 "Uniden America" 1083 "Nauticoncept" 1084 "Shadow-Caster LED lighting" 1085 "Wet Sounds" 1088 "E-T-A Circuit Breakers" 1092 "Scheiber" 1100 "Smart Yachts International Limited" 1109 "Dockmate" 1114 "Bobs Machine" 1118 "L3Harris ASV" 1119 "Balmar" 1120 "Elettromedia" 1127 "Electromaax" 1140 "Across Oceans Systems" 1145 "Kiwi Yachting" 1150 "BSB Artificial Intelligence" 1151 "Orca Technologies" 1154 "TBS Electronics" 1158 "Technoton Electroics" 1160 "MG Energy Systems" 1169 "Sea Machine Robotics" 1171 "Vista Manufacturing" 1183 "Zipwake" 1186 "Sailmon" 1192 "Airmoniq Pro Kft" 1194 "Sierra Marine" 1200 "Xinuo Information Technology (Xiamen)" 1218 "Septentrio" 1233 "NKE Marine Electronics" 1238 "SuperTrack Aps" 1239 "Honda Electronics" 1245 "Raritan Engineering" 1249 "Integrated Power Solutions AG" 1260 "Interactive Technologies" 1283 "LTG-Tech" 1299 "Energy Solutions (UK)" 1300 "WATT Fuel Cell" 1302 "Pro Mainer" 1305 "Dragonfly Energy" 1306 "Koden Electronics" 1311 "Humphree" 1316 "Hinkley Yachts" 1317 "Global Marine Management GmbH (GMM)" 1320 "Triskel Marine" 1330 "Warwick Control Technologies" 1331 "Dolphin Charger" 1337 "Barnacle Systems" 1348 "Radian IoT" 1353 "Ocean LED Marine" 1359 "BluNav" 1361 "OVA (Nantong Saiyang Electronics Co., Ltd)" 1368 "RAD Propulsion" 1369 "Electric Yacht" 1372 "Elco Motor Yachts" 1384 "Tecnoseal Foundry S.r.l" 1385 "Pro Charging Systems" 1389 "EVEX" 1398 "Gobius Sensor Technology" 1403 "Arco Marine" 1408 "Lenco Marine" 1413 "Naocontrol" 1417 "Revatek" 1438 "Aeolionics" 1439 "PredictWind" 1440 "Egis Mobile Electric" 1445 "Starboard Yacht Group" 1446 "Roswell Marine" 1451 "ePropulsion (Guangdong ePropulsion Technology Ltd.)" 1452 "Micro-Air" 1453 "Vital Battery" 1458 "Ride Controller" 1460 "Tocaro Blue" 1461 "Vanquish Yachts" 1471 "FT Technologies" 1478 "Alps Alpine" 1481 "E-Force Marine" 1482 "CMC Marine" 1483 "Nanjing Sandemarine Information Technology" 1850 "Teleflex Marine (SeaStar Solutions)" 1851 "Raymarine" 1852 "Navionics" 1853 "Japan Radio" 1854 "Northstar Technologies" 1855 "Furuno" 1856 "Trimble" 1857 "Simrad" 1858 "Litton" 1859 "Kvasar" 1860 "MMP" 1861 "Vector Cantech" 1862 "Yamaha Marine" 1863 "Faria Instruments" ;
VAL_ 2566850304 Industry_Code 0 "Global" 1 "Highway" 2 "Agriculture" 3 "Construction" 4 "Marine Industry" 5 "Industrial" ;
VAL_ 2499741696 Manufacturer_Code 69 "ARKS Enterprises" 78 "FW Murphy/Enovation Controls" 80 "Twin Disc" 85 "Kohler Power Systems" 88 "Hemisphere GPS" 135 "Airmar" 137 "Maretron" 140 "Lowrance" 144 "Mercury Marine" 147 "Nautibus Electronic" 148 "Blue Water Data" 154 "Westerbeke" 157 "ISSPRO" 161 "Offshore Systems (UK)" 163 "Evinrude/BRP" 165 "CPAC Systems" 168 "Xantrex Technology" 169 "Marlin Technologies" 172 "Yanmar Marine" 174 "Volvo Penta" 176 "Carling Technologies Inc. (Moritz Aerospace)" 185 "Beede Instruments" 192 "Floscan Instrument" 193 "Nobeltec" 198 "Mystic Valley Communications" 199 "Actia" 201 "Disenos Y Technologia" 211 "Digital Switching Systems" 215 "Xintex/Atena" 224 "EMMI NETWORK" 228 "ZF" 229 "Garmin" 233 "Yacht Monitoring Solutions" 235 "Sailormade Marine Telemetry/Tetra Technology" 243 "Eride" 257 "Honda Motor" 272 "Groco" 273 "Actisense" 274 "Amphenol LTW Technology" 275 "Navico" 283 "Hamilton Jet" 285 "Sea Recovery" 286 "Coelmo SRL Italy" 295 "BEP Marine" 304 "Empir Bus" 305 "NovAtel" 306 "Sleipner Motor" 307 "MBW Technologies" 315 "ICOM" 328 "Qwerty" 329 "Dief" 341 "Boening Automationstechnologie" 345 "Korean Maritime University" 351 "Thrane and Thrane" 355 "Mastervolt" 356 "Fischer Panda Generators" 358 "Victron Energy" 370 "Rolls Royce Marine" 373 "Electronic Design" 374 "Northern Lights" 378 "Glendinning" 381 "B & G" 384 "Rose Point Navigation Systems" 385 "Johnson Outdoors Marine Electronics Inc Geonav" 394 "Capi 2" 396 "Beyond Measure" 400 "Livorsi Marine" 404 "ComNav" 409 "Chetco" 419 "Fusion Electronics" 421 "Standard Horizon" 422 "True Heading" 426 "Egersund Marine Electronics" 427 "em-trak Marine Electronics" 431 "Tohatsu Co, JP" 437 "Digital Yacht" 438 "Comar Systems Limited" 440 "Cummins" 443 "VDO (aka Continental-Corporation)" 451 "Parker Hannifin aka Village Marine Tech" 459 "Alltek Marine Electronics" 460 "SAN GIORGIO S.E.I.N" 466 "Veethree Electronics & Marine" 470 "SI-TEX Marine Electronics" 471 "Sea Cross Marine" 475 "GME aka Standard Communications" 476 "Humminbird Marine Electronics" 478 "Ocean Sat" 481 "Chetco Digital Instruments" 493 "Watcheye" 499 "Lcj Capteurs" 502 "Attwood Marine" 503 "Naviop S.R.L." 504 "Vesper Marine" 510 "Marinesoft" 513 "Simarine" 517 "NoLand Engineering" 518 "Transas USA" 529 "National Instruments Korea" 530 "National Marine Electronics Association" 532 "Onwa Marine" 540 "Webasto" 571 "Marinecraft (South Korea)" 573 "McMurdo Group aka Orolia" 578 "Advansea" 579 "KVH" 580 "San Jose Technology" 583 "Yacht Control" 586 "Suzuki Motor" 591 "US Coast Guard" 595 "Ship Module aka Customware" 600 "Aquatic AV" 605 "Aventics" 606 "Intellian" 612 "SamwonIT" 614 "Arlt Tecnologies" 637 "Bavaria Yachts" 641 "Diverse Yacht Services" 644 "Wema U.S.A dba KUS" 658 "Shenzhen Jiuzhou Himunication" 688 "Rockford" 699 "Harman International" 704 "JL Audio" 708 "Lars Thrane" 715 "Autonnic" 717 "Yacht Devices" 734 "REAP Systems" 735 "AEM Performance Electronics" 739 "LxNav" 741 "Littelfuse, Inc (formerly Carling Technologies)" 743 "DaeMyung" 744 "Woosung" 748 "ISOTTA IFRA srl" 773 "Clarion US" 776 "HMI Systems" 777 "Ocean Signal" 778 "Seakeeper" 781 "Poly Planar" 785 "Fischer Panda DE" 795 "Broyda Industries" 796 "Canadian Automotive" 797 "Tides Marine" 798 "Lumishore" 799 "Still Water Designs and Audio" 802 "BJ Technologies (Beneteau)" 803 "Gill Sensors" 811 "Blue Water Desalination" 815 "FLIR" 824 "Undheim Systems" 826 "Lewmar" 838 "TeamSurv" 844 "Fell Marine" 847 "Oceanvolt" 862 "Prospec" 868 "Data Panel" 890 "L3 Technologies" 894 "Rhodan Marine Systems" 896 "Nexfour Solutions" 905 "ASA Electronics" 909 "Marines Co (South Korea)" 911 "Nautic-on" 917 "Sentinel" 929 "JL Marine Systems" 930 "Ecotronix" 944 "Zontisa Marine" 951 "EXOR International" 962 "Timbolier Industries" 963 "TJC Micro" 968 "Cox Powertrain" 969 "Blue Seas" 981 "Kobelt Manufacturing" 992 "Blue Ocean IOT" 997 "Xenta Systems" 999 "Signal K" 1004 "Ultraflex" 1008 "Lintest SmartBoat" 1011 "Soundmax" 1020 "Team Italia Marine (Onyx Marine Automation s.r.l)" 1021 "Entratech" 1022 "ITC" 1029 "The Marine Guardian" 1047 "Sonic" 1051 "ProNav" 1053 "Vetus Maxwell INC." 1056 "Lithium Pros" 1059 "Boatrax" 1062 "Marol Co ltd" 1065 "CALYPSO Instruments" 1066 "Spot Zero Water" 1069 "Lithionics Battery" 1070 "Quick-teck Electronics" 1075 "Uniden America" 1083 "Nauticoncept" 1084 "Shadow-Caster LED lighting" 1085 "Wet Sounds" 1088 "E-T-A Circuit Breakers" 1092 "Scheiber" 1100 "Smart Yachts International Limited" 1109 "Dockmate" 1114 "Bobs Machine" 1118 "L3Harris ASV" 1119 "Balmar" 1120 "Elettromedia" 1127 "Electromaax" 1140 "Across Oceans Systems" 1145 "Kiwi Yachting" 1150 "BSB Artificial Intelligence" 1151 "Orca Technologies" 1154 "TBS Electronics" 1158 "Technoton Electroics" 1160 "MG Energy Systems" 1169 "Sea Machine Robotics" 1171 "Vista Manufacturing" 1183 "Zipwake" 1186 "Sailmon" 1192 "Airmoniq Pro Kft" 1194 "Sierra Marine" 1200 "Xinuo Information Technology (Xiamen)" 1218 "Septentrio" 1233 "NKE Marine Electronics" 1238 "SuperTrack Aps" 1239 "Honda Electronics" 1245 "Raritan Engineering" 1249 "Integrated Power Solutions AG" 1260 "Interactive Technologies" 1283 "LTG-Tech" 1299 "Energy Solutions (UK)" 1300 "WATT Fuel Cell" 1302 "Pro Mainer" 1305 "Dragonfly Energy" 1306 "Koden Electronics" 1311 "Humphree" 1316 "Hinkley Yachts" 1317 "Global Marine Management GmbH (GMM)" 1320 "Triskel Marine" 1330 "Warwick Control Technologies" 1331 "Dolphin Charger" 1337 "Barnacle Systems" 1348 "Radian IoT" 1353 "Ocean LED Marine" 1359 "BluNav" 1361 "OVA (Nantong Saiyang Electronics Co., Ltd)" 1368 "RAD Propulsion" 1369 "Electric Yacht" 1372 "Elco Motor Yachts" 1384 "Tecnoseal Foundry S.r.l" 1385 "Pro Charging Systems" 1389 "EVEX" 1398 "Gobius Sensor Technology" 1403 "Arco Marine" 1408 "Lenco Marine" 1413 "Naocontrol" 1417 "Revatek" 1438 "Aeolionics" 1439 "PredictWind" 1440 "Egis Mobile Electric" 1445 "Starboard Yacht Group" 1446 "Roswell Marine" 1451 "ePropulsion (Guangdong ePropulsion Technology Ltd.)" 1452 "Micro-Air" 1453 "Vital Battery" 1458 "Ride Controller" 1460 "Tocaro Blue" 1461 "Vanquish Yachts" 1471 "FT Technologies" 1478 "Alps Alpine" 1481 "E-Force Marine" 1482 "CMC Marine" 1483 "Nanjing Sandemarine Information Technology" 1850 "Teleflex Marine (SeaStar Solutions)" 1851 "Raymarine" 1852 "Navionics" 1853 "Japan Radio" 1854 "Northstar Technologies" 1855 "Furuno" 1856 "Trimble" 1857 "Simrad" 1858 "Litton" 1859 "Kvasar" 1860 "MMP" 1861 "Vector Cantech" 1862 "Yamaha Marine" 1863 "Faria Instruments" ;
VAL_ 2499741696 Industry_Code 0 "Global" 1 "Highway" 2 "Agriculture" 3 "Construction" 4 "Marine Industry" 5 "Industrial" ;
VAL_ 2633959424 Manufacturer_Code 69 "ARKS Enterprises" 78 "FW Murphy/Enovation Controls" 80 "Twin Disc" 85 "Kohler Power Systems" 88 "Hemisphere GPS" 135 "Airmar" 137 "Maretron" 140 "Lowrance" 144 "Mercury Marine" 147 "Nautibus Electronic" 148 "Blue Water Data" 154 "Westerbeke" 157 "ISSPRO" 161 "Offshore Systems (UK)" 163 "Evinrude/BRP" 165 "CPAC Systems" 168 "Xantrex Technology" 169 "Marlin Technologies" 172 "Yanmar Marine" 174 "Volvo Penta" 176 "Carling Technologies Inc. (Moritz Aerospace)" 185 "Beede Instruments" 192 "Floscan Instrument" 193 "Nobeltec" 198 "Mystic Valley Communications" 199 "Actia" 201 "Disenos Y Technologia" 211 "Digital Switching Systems" 215 "Xintex/Atena" 224 "EMMI NETWORK" 228 "ZF" 229 "Garmin" 233 "Yacht Monitoring Solutions" 235 "Sailormade Marine Telemetry/Tetra Technology" 243 "Eride" 257 "Honda Motor" 272 "Groco" 273 "Actisense" 274 "Amphenol LTW Technology" 275 "Navico" 283 "Hamilton Jet" 285 "Sea Recovery" 286 "Coelmo SRL Italy" 295 "BEP Marine" 304 "Empir Bus" 305 "NovAtel" 306 "Sleipner Motor" 307 "MBW Technologies" 315 "ICOM" 328 "Qwerty" 329 "Dief" 341 "Boening Automationstechnologie" 345 "Korean Maritime University" 351 "Thrane and Thrane" 355 "Mastervolt" 356 "Fischer Panda Generators" 358 "Victron Energy" 370 "Rolls Royce Marine" 373 "Electronic Design" 374 "Northern Lights" 378 "Glendinning" 381 "B & G" 384 "Rose Point Navigation Systems" 385 "Johnson Outdoors Marine Electronics Inc Geonav" 394 "Capi 2" 396 "Beyond Measure" 400 "Livorsi Marine" 404 "ComNav" 409 "Chetco" 419 "Fusion Electronics" 421 "Standard Horizon" 422 "True Heading" 426 "Egersund Marine Electronics" 427 "em-trak Marine Electronics" 431 "Tohatsu Co, JP" 437 "Digital Yacht" 438 "Comar Systems Limited" 440 "Cummins" 443 "VDO (aka Continental-Corporation)" 451 "Parker Hannifin aka Village Marine Tech" 459 "Alltek Marine Electronics" 460 "SAN GIORGIO S.E.I.N" 466 "Veethree Electronics & Marine" 470 "SI-TEX Marine Electronics" 471 "Sea Cross Marine" 475 "GME aka Standard Communications" 476 "Humminbird Marine Electronics" 478 "Ocean Sat" 481 "Chetco Digital Instruments" 493 "Watcheye" 499 "Lcj Capteurs" 502 "Attwood Marine" 503 "Naviop S.R.L." 504 "Vesper Marine" 510 "Marinesoft" 513 "Simarine" 517 "NoLand Engineering" 518 "Transas USA" 529 "National Instruments Korea" 530 "National Marine Electronics Association" 532 "Onwa Marine" 540 "Webasto" 571 "Marinecraft (South Korea)" 573 "McMurdo Group aka Orolia" 578 "Advansea" 579 "KVH" 580 "San Jose Technology" 583 "Yacht Control" 586 "Suzuki Motor" 591 "US Coast Guard" 595 "Ship Module aka Customware" 600 "Aquatic AV" 605 "Aventics" 606 "Intellian" 612 "SamwonIT" 614 "Arlt Tecnologies" 637 "Bavaria Yachts" 641 "Diverse Yacht Services" 644 "Wema U.S.A dba KUS" 658 "Shenzhen Jiuzhou Himunication" 688 "Rockford" 699 "Harman International" 704 "JL Audio" 708 "Lars Thrane" 715 "Autonnic" 717 "Yacht Devices" 734 "REAP Systems" 735 "AEM Performance Electronics" 739 "LxNav" 741 "Littelfuse, Inc (formerly Carling Technologies)" 743 "DaeMyung" 744 "Woosung" 748 "ISOTTA IFRA srl" 773 "Clarion US" 776 "HMI Systems" 777 "Ocean Signal" 778 "Seakeeper" 781 "Poly Planar" 785 "Fischer Panda DE" 795 "Broyda Industries" 796 "Canadian Automotive" 797 "Tides Marine" 798 "Lumishore" 799 "Still Water Designs and Audio" 802 "BJ Technologies (Beneteau)" 803 "Gill Sensors" 811 "Blue Water Desalination" 815 "FLIR" 824 "Undheim Systems" 826 "Lewmar" 838 "TeamSurv" 844 "Fell Marine" 847 "Oceanvolt" 862 "Prospec" 868 "Data Panel" 890 "L3 Technologies" 894 "Rhodan Marine Systems" 896 "Nexfour Solutions" 905 "ASA Electronics" 909 "Marines Co (South Korea)" 911 "Nautic-on" 917 "Sentinel" 929 "JL Marine Systems" 930 "Ecotronix" 944 "Zontisa Marine" 951 "EXOR International" 962 "Timbolier Industries" 963 "TJC Micro" 968 "Cox Powertrain" 969 "Blue Seas" 981 "Kobelt Manufacturing" 992 "Blue Ocean IOT" 997 "Xenta Systems" 999 "Signal K" 1004 "Ultraflex" 1008 "Lintest SmartBoat" 1011 "Soundmax" 1020 "Team Italia Marine (Onyx Marine Automation s.r.l)" 1021 "Entratech" 1022 "ITC" 1029 "The Marine Guardian" 1047 "Sonic" 1051 "ProNav" 1053 "Vetus Maxwell INC." 1056 "Lithium Pros" 1059 "Boatrax" 1062 "Marol Co ltd" 1065 "CALYPSO Instruments" 1066 "Spot Zero Water" 1069 "Lithionics Battery" 1070 "Quick-teck Electronics" 1075 "Uniden America" 1083 "Nauticoncept" 1084 "Shadow-Caster LED lighting" 1085 "Wet Sounds" 1088 "E-T-A Circuit Breakers" 1092 "Scheiber" 1100 "Smart Yachts International Limited" 1109 "Dockmate" 1114 "Bobs Machine" 1118 "L3Harris ASV" 1119 "Balmar" 1120 "Elettromedia" 1127 "Electromaax" 1140 "Across Oceans Systems" 1145 "Kiwi Yachting" 1150 "BSB Artificial Intelligence" 1151 "Orca Technologies" 1154 "TBS Electronics" 1158 "Technoton Electroics" 1160 "MG Energy Systems" 1169 "Sea Machine Robotics" 1171 "Vista Manufacturing" 1183 "Zipwake" 1186 "Sailmon" 1192 "Airmoniq Pro Kft" 1194 "Sierra Marine" 1200 "Xinuo Information Technology (Xiamen)" 1218 "Septentrio" 1233 "NKE Marine Electronics" 1238 "SuperTrack Aps" 1239 "Honda Electronics" 1245 "Raritan Engineering" 1249 "Integrated Power Solutions AG" 1260 "Interactive Technologies" 1283 "LTG-Tech" 1299 "Energy Solutions (UK)" 1300 "WATT Fuel Cell" 1302 "Pro Mainer" 1305 "Dragonfly Energy" 1306 "Koden Electronics" 1311 "Humphree" 1316 "Hinkley Yachts" 1317 "Global Marine Management GmbH (GMM)" 1320 "Triskel Marine" 1330 "Warwick Control Technologies" 1331 "Dolphin Charger" 1337 "Barnacle Systems" 1348 "Radian IoT" 1353 "Ocean LED Marine" 1359 "BluNav" 1361 "OVA (Nantong Saiyang Electronics Co., Ltd)" 1368 "RAD Propulsion" 1369 "Electric Yacht" 1372 "Elco Motor Yachts" 1384 "Tecnoseal Foundry S.r.l" 1385 "Pro Charging Systems" 1389 "EVEX" 1398 "Gobius Sensor Technology" 1403 "Arco Marine" 1408 "Lenco Marine" 1413 "Naocontrol" 1417 "Revatek" 1438 "Aeolionics" 1439 "PredictWind" 1440 "Egis Mobile Electric" 1445 "Starboard Yacht Group" 1446 "Roswell Marine" 1451 "ePropulsion (Guangdong ePropulsion Technology Ltd.)" 1452 "Micro-Air" 1453 "Vital Battery" 1458 "Ride Controller" 1460 "Tocaro Blue" 1461 "Vanquish Yachts" 1471 "FT Technologies" 1478 "Alps Alpine" 1481 "E-Force Marine" 1482 "CMC Marine" 1483 "Nanjing Sandemarine Information Technology" 1850 "Teleflex Marine (SeaStar Solutions)" 1851 "Raymarine" 1852 "Navionics" 1853 "Japan Radio" 1854 "Northstar Technologies" 1855 "Furuno" 1856 "Trimble" 1857 "Simrad" 1858 "Litton" 1859 "Kvasar" 1860 "MMP" 1861 "Vector Cantech" 1862 "Yamaha Marine" 1863 "Faria Instruments" ;
VAL_ 2633959424 Industry_Code 0 "Global" 1 "Highway" 2 "Agriculture" 3 "Construction" 4 "Marine Industry" 5 "Industrial" ;
VAL_ 2633959424 Alarm_Status 0 "Alarm condition not met" 1 "Alarm condition met and not silenced" 2 "Alarm condition met and silenced" ;
VAL_ 2633959424 Alarm_ID 0 "No Alarm" 1 "Shallow Depth" 2 "Deep Depth" 3 "Shallow Anchor" 4 "Deep Anchor" 5 "Off Course" 6 "AWA High" 7 "AWA Low" 8 "AWS High" 9 "AWS Low" 10 "TWA High" 11 "TWA Low" 12 "TWS High" 13 "TWS Low" 14 "WP Arrival" 15 "Boat Speed High" 16 "Boat Speed Low" 17 "Sea Temperature High" 18 "Sea Temperature Low" 19 "Pilot Watch" 20 "Pilot Off Course" 21 "Pilot Wind Shift" 22 "Pilot Low Battery" 23 "Pilot Last Minute Of Watch" 24 "Pilot No NMEA Data" 25 "Pilot Large XTE" 26 "Pilot NMEA DataError" 27 "Pilot CU Disconnected" 28 "Pilot Auto Release" 29 "Pilot Way Point Advance" 30 "Pilot Drive Stopped" 31 "Pilot Type Unspecified" 32 "Pilot Calibration Required" 33 "Pilot Last Heading" 34 "Pilot No Pilot" 35 "Pilot Route Complete" 36 "Pilot Variable Text" 37 "GPS Failure" 38 "MOB" 39 "Seatalk1 Anchor" 40 "Pilot Swapped Motor Power" 41 "Pilot Standby Too Fast To Fish" 42 "Pilot No GPS Fix" 43 "Pilot No GPS COG" 44 "Pilot Start Up" 45 "Pilot Too Slow" 46 "Pilot No Compass" 47 "Pilot Rate Gyro Fault" 48 "Pilot Current Limit" 49 "Pilot Way Point Advance Port" 50 "Pilot Way Point Advance Stbd" 51 "Pilot No Wind Data" 52 "Pilot No Speed Data" 53 "Pilot Seatalk Fail1" 54 "Pilot Seatalk Fail2" 55 "Pilot Warning Too Fast To Fish" 56 "Pilot Auto Dockside Fail" 57 "Pilot Turn Too Fast" 58 "Pilot No Nav Data" 59 "Pilot Lost Waypoint Data" 60 "Pilot EEPROM Corrupt" 61 "Pilot Rudder Feedback Fail" 62 "Pilot Autolearn Fail1" 63 "Pilot Autolearn Fail2" 64 "Pilot Autolearn Fail3" 65 "Pilot Autolearn Fail4" 66 "Pilot Autolearn Fail5" 67 "Pilot Autolearn Fail6" 68 "Pilot Warning Cal Required" 69 "Pilot Warning OffCourse" 70 "Pilot Warning XTE" 71 "Pilot Warning Wind Shift" 72 "Pilot Warning Drive Short" 73 "Pilot Warning Clutch Short" 74 "Pilot Warning Solenoid Short" 75 "Pilot Joystick Fault" 76 "Pilot No Joystick Data" 80 "Pilot Invalid Command" 81 "AIS TX Malfunction" 82 "AIS Antenna VSWR fault" 83 "AIS Rx channel 1 malfunction" 84 "AIS Rx channel 2 malfunction" 85 "AIS No sensor position in use" 86 "AIS No valid SOG information" 87 "AIS No valid COG information" 88 "AIS 12V alarm" 89 "AIS 6V alarm" 90 "AIS Noise threshold exceeded channel A" 91 "AIS Noise threshold exceeded channel B" 92 "AIS Transmitter PA fault" 93 "AIS 3V3 alarm" 94 "AIS Rx channel 70 malfunction" 95 "AIS Heading lost/invalid" 96 "AIS internal GPS lost" 97 "AIS No sensor position" 98 "AIS Lock failure" 99 "AIS Internal GGA timeout" 100 "AIS Protocol stack restart" 101 "Pilot No IPS communications" 102 "Pilot Power-On or Sleep-Switch Reset While Engaged" 103 "Pilot Unexpected Reset While Engaged" 104 "AIS Dangerous Target" 105 "AIS Lost Target" 106 "AIS Safety Related Message (used to silence)" 107 "AIS Connection Lost" 108 "No Fix" 112 "Pilot Compass Calibration Complete" 113 "AIS Transmitter Disabled - MMSI Required" 122 "Bluetooth Device Low Battery" 123 "Bluetooth Device Sleep Mode" 124 "Bluetooth Device High Battery Temperature" 125 "Bluetooth Device Lost Communications" ;
VAL_ 2633959424 Alarm_Group 0 "Instrument" 1 "Autopilot" 2 "Radar" 3 "Chart Plotter" 4 "AIS" 5 "Bluetooth Accessory" ;
VAL_ 2499741952 Manufacturer_Code 69 "ARKS Enterprises" 78 "FW Murphy/Enovation Controls" 80 "Twin Disc" 85 "Kohler Power Systems" 88 "Hemisphere GPS" 135 "Airmar" 137 "Maretron" 140 "Lowrance" 144 "Mercury Marine" 147 "Nautibus Electronic" 148 "Blue Water Data" 154 "Westerbeke" 157 "ISSPRO" 161 "Offshore Systems (UK)" 163 "Evinrude/BRP" 165 "CPAC Systems" 168 "Xantrex Technology" 169 "Marlin Technologies" 172 "Yanmar Marine" 174 "Volvo Penta" 176 "Carling Technologies Inc. (Moritz Aerospace)" 185 "Beede Instruments" 192 "Floscan Instrument" 193 "Nobeltec" 198 "Mystic Valley Communications" 199 "Actia" 201 "Disenos Y Technologia" 211 "Digital Switching Systems" 215 "Xintex/Atena" 224 "EMMI NETWORK" 228 "ZF" 229 "Garmin" 233 "Yacht Monitoring Solutions" 235 "Sailormade Marine Telemetry/Tetra Technology" 243 "Eride" 257 "Honda Motor" 272 "Groco" 273 "Actisense" 274 "Amphenol LTW Technology" 275 "Navico" 283 "Hamilton Jet" 285 "Sea Recovery" 286 "Coelmo SRL Italy" 295 "BEP Marine" 304 "Empir Bus" 305 "NovAtel" 306 "Sleipner Motor" 307 "MBW Technologies" 315 "ICOM" 328 "Qwerty" 329 "Dief" 341 "Boening Automationstechnologie" 345 "Korean Maritime University" 351 "Thrane and Thrane" 355 "Mastervolt" 356 "Fischer Panda Generators" 358 "Victron Energy" 370 "Rolls Royce Marine" 373 "Electronic Design" 374 "Northern Lights" 378 "Glendinning" 381 "B & G" 384 "Rose Point Navigation Systems" 385 "Johnson Outdoors Marine Electronics Inc Geonav" 394 "Capi 2" 396 "Beyond Measure" 400 "Livorsi Marine" 404 "ComNav" 409 "Chetco" 419 "Fusion Electronics" 421 "Standard Horizon" 422 "True Heading" 426 "Egersund Marine Electronics" 427 "em-trak Marine Electronics" 431 "Tohatsu Co, JP" 437 "Digital Yacht" 438 "Comar Systems Limited" 440 "Cummins" 443 "VDO (aka Continental-Corporation)" 451 "Parker Hannifin aka Village Marine Tech" 459 "Alltek Marine Electronics" 460 "SAN GIORGIO S.E.I.N" 466 "Veethree Electronics & Marine" 470 "SI-TEX Marine Electronics" 471 "Sea Cross Marine" 475 "GME aka Standard Communications" 476 "Humminbird Marine Electronics" 478 "Ocean Sat" 481 "Chetco Digital Instruments" 493 "Watcheye" 499 "Lcj Capteurs" 502 "Attwood Marine" 503 "Naviop S.R.L." 504 "Vesper Marine" 510 "Marinesoft" 513 "Simarine" 517 "NoLand Engineering" 518 "Transas USA" 529 "National Instruments Korea" 530 "National Marine Electronics Association" 532 "Onwa Marine" 540 "Webasto" 571 "Marinecraft (South Korea)" 573 "McMurdo Group aka Orolia" 578 "Advansea" 579 "KVH" 580 "San Jose Technology" 583 "Yacht Control" 586 "Suzuki Motor" 591 "US Coast Guard" 595 "Ship Module aka Customware" 600 "Aquatic AV" 605 "Aventics" 606 "Intellian" 612 "SamwonIT" 614 "Arlt Tecnologies" 637 "Bavaria Yachts" 641 "Diverse Yacht Services" 644 "Wema U.S.A dba KUS" 658 "Shenzhen Jiuzhou Himunication" 688 "Rockford" 699 "Harman International" 704 "JL Audio" 708 "Lars Thrane" 715 "Autonnic" 717 "Yacht Devices" 734 "REAP Systems" 735 "AEM Performance Electronics" 739 "LxNav" 741 "Littelfuse, Inc (formerly Carling Technologies)" 743 "DaeMyung" 744 "Woosung" 748 "ISOTTA IFRA srl" 773 "Clarion US" 776 "HMI Systems" 777 "Ocean Signal" 778 "Seakeeper" 781 "Poly Planar" 785 "Fischer Panda DE" 795 "Broyda Industries" 796 "Canadian Automotive" 797 "Tides Marine" 798 "Lumishore" 799 "Still Water Designs and Audio" 802 "BJ Technologies (Beneteau)" 803 "Gill Sensors" 811 "Blue Water Desalination" 815 "FLIR" 824 "Undheim Systems" 826 "Lewmar" 838 "TeamSurv" 844 "Fell Marine" 847 "Oceanvolt" 862 "Prospec" 868 "Data Panel" 890 "L3 Technologies" 894 "Rhodan Marine Systems" 896 "Nexfour Solutions" 905 "ASA Electronics" 909 "Marines Co (South Korea)" 911 "Nautic-on" 917 "Sentinel" 929 "JL Marine Systems" 930 "Ecotronix" 944 "Zontisa Marine" 951 "EXOR International" 962 "Timbolier Industries" 963 "TJC Micro" 968 "Cox Powertrain" 969 "Blue Seas" 981 "Kobelt Manufacturing" 992 "Blue Ocean IOT" 997 "Xenta Systems" 999 "Signal K" 1004 "Ultraflex" 1008 "Lintest SmartBoat" 1011 "Soundmax" 1020 "Team Italia Marine (Onyx Marine Automation s.r.l)" 1021 "Entratech" 1022 "ITC" 1029 "The Marine Guardian" 1047 "Sonic" 1051 "ProNav" 1053 "Vetus Maxwell INC." 1056 "Lithium Pros" 1059 "Boatrax" 1062 "Marol Co ltd" 1065 "CALYPSO Instruments" 1066 "Spot Zero Water" 1069 "Lithionics Battery" 1070 "Quick-teck Electronics" 1075 "Uniden America" 1083 "Nauticoncept" 1084 "Shadow-Caster LED lighting" 1085 "Wet Sounds" 1088 "E-T-A Circuit Breakers" 1092 "Scheiber" 1100 "Smart Yachts International Limited" 1109 "Dockmate" 1114 "Bobs Machine" 1118 "L3Harris ASV" 1119 "Balmar" 1120 "Elettromedia" 1127 "Electromaax" 1140 "Across Oceans Systems" 1145 "Kiwi Yachting" 1150 "BSB Artificial Intelligence" 1151 "Orca Technologies" 1154 "TBS Electronics" 1158 "Technoton Electroics" 1160 "MG Energy Systems" 1169 "Sea Machine Robotics" 1171 "Vista Manufacturing" 1183 "Zipwake" 1186 "Sailmon" 1192 "Airmoniq Pro Kft" 1194 "Sierra Marine" 1200 "Xinuo Information Technology (Xiamen)" 1218 "Septentrio" 1233 "NKE Marine Electronics" 1238 "SuperTrack Aps" 1239 "Honda Electronics" 1245 "Raritan Engineering" 1249 "Integrated Power Solutions AG" 1260 "Interactive Technologies" 1283 "LTG-Tech" 1299 "Energy Solutions (UK)" 1300 "WATT Fuel Cell" 1302 "Pro Mainer" 1305 "Dragonfly Energy" 1306 "Koden Electronics" 1311 "Humphree" 1316 "Hinkley Yachts" 1317 "Global Marine Management GmbH (GMM)" 1320 "Triskel Marine" 1330 "Warwick Control Technologies" 1331 "Dolphin Charger" 1337 "Barnacle Systems" 1348 "Radian IoT" 1353 "Ocean LED Marine" 1359 "BluNav" 1361 "OVA (Nantong Saiyang Electronics Co., Ltd)" 1368 "RAD Propulsion" 1369 "Electric Yacht" 1372 "Elco Motor Yachts" 1384 "Tecnoseal Foundry S.r.l" 1385 "Pro Charging Systems" 1389 "EVEX" 1398 "Gobius Sensor Technology" 1403 "Arco Marine" 1408 "Lenco Marine" 1413 "Naocontrol" 1417 "Revatek" 1438 "Aeolionics" 1439 "PredictWind" 1440 "Egis Mobile Electric" 1445 "Starboard Yacht Group" 1446 "Roswell Marine" 1451 "ePropulsion (Guangdong ePropulsion Technology Ltd.)" 1452 "Micro-Air" 1453 "Vital Battery" 1458 "Ride Controller" 1460 "Tocaro Blue" 1461 "Vanquish Yachts" 1471 "FT Technologies" 1478 "Alps Alpine" 1481 "E-Force Marine" 1482 "CMC Marine" 1483 "Nanjing Sandemarine Information Technology" 1850 "Teleflex Marine (SeaStar Solutions)" 1851 "Raymarine" 1852 "Navionics" 1853 "Japan Radio" 1854 "Northstar Technologies" 1855 "Furuno" 1856 "Trimble" 1857 "Simrad" 1858 "Litton" 1859 "Kvasar" 1860 "MMP" 1861 "Vector Cantech" 1862 "Yamaha Marine" 1863 "Faria Instruments" ;
VAL_ 2499741952 Industry_Code 0 "Global" 1 "Highway" 2 "Agriculture" 3 "Construction" 4 "Marine Industry" 5 "Industrial" ;
VAL_ 2566850816 Manufacturer_Code 69 "ARKS Enterprises" 78 "FW Murphy/Enovation Controls" 80 "Twin Disc" 85 "Kohler Power Systems" 88 "Hemisphere GPS" 135 "Airmar" 137 "Maretron" 140 "Lowrance" 144 "Mercury Marine" 147 "Nautibus Electronic" 148 "Blue Water Data" 154 "Westerbeke" 157 "ISSPRO" 161 "Offshore Systems (UK)" 163 "Evinrude/BRP" 165 "CPAC Systems" 168 "Xantrex Technology" 169 "Marlin Technologies" 172 "Yanmar Marine" 174 "Volvo Penta" 176 "Carling Technologies Inc. (Moritz Aerospace)" 185 "Beede Instruments" 192 "Floscan Instrument" 193 "Nobeltec" 198 "Mystic Valley Communications" 199 "Actia" 201 "Disenos Y Technologia" 211 "Digital Switching Systems" 215 "Xintex/Atena" 224 "EMMI NETWORK" 228 "ZF" 229 "Garmin" 233 "Yacht Monitoring Solutions" 235 "Sailormade Marine Telemetry/Tetra Technology" 243 "Eride" 257 "Honda Motor" 272 "Groco" 273 "Actisense" 274 "Amphenol LTW Technology" 275 "Navico" 283 "Hamilton Jet" 285 "Sea Recovery" 286 "Coelmo SRL Italy" 295 "BEP Marine" 304 "Empir Bus" 305 "NovAtel" 306 "Sleipner Motor" 307 "MBW Technologies" 315 "ICOM" 328 "Qwerty" 329 "Dief" 341 "Boening Automationstechnologie" 345 "Korean Maritime University" 351 "Thrane and Thrane" 355 "Mastervolt" 356 "Fischer Panda Generators" 358 "Victron Energy" 370 "Rolls Royce Marine" 373 "Electronic Design" 374 "Northern Lights" 378 "Glendinning" 381 "B & G" 384 "Rose Point Navigation Systems" 385 "Johnson Outdoors Marine Electronics Inc Geonav" 394 "Capi 2" 396 "Beyond Measure" 400 "Livorsi Marine" 404 "ComNav" 409 "Chetco" 419 "Fusion Electronics" 421 "Standard Horizon" 422 "True Heading" 426 "Egersund Marine Electronics" 427 "em-trak Marine Electronics" 431 "Tohatsu Co, JP" 437 "Digital Yacht" 438 "Comar Systems Limited" 440 "Cummins" 443 "VDO (aka Continental-Corporation)" 451 "Parker Hannifin aka Village Marine Tech" 459 "Alltek Marine Electronics" 460 "SAN GIORGIO S.E.I.N" 466 "Veethree Electronics & Marine" 470 "SI-TEX Marine Electronics" 471 "Sea Cross Marine" 475 "GME aka Standard Communications" 476 "Humminbird Marine Electronics" 478 "Ocean Sat" 481 "Chetco Digital Instruments" 493 "Watcheye" 499 "Lcj Capteurs" 502 "Attwood Marine" 503 "Naviop S.R.L." 504 "Vesper Marine" 510 "Marinesoft" 513 "Simarine" 517 "NoLand Engineering" 518 "Transas USA" 529 "National Instruments Korea" 530 "National Marine Electronics Association" 532 "Onwa Marine" 540 "Webasto" 571 "Marinecraft (South Korea)" 573 "McMurdo Group aka Orolia" 578 "Advansea" 579 "KVH" 580 "San Jose Technology" 583 "Yacht Control" 586 "Suzuki Motor" 591 "US Coast Guard" 595 "Ship Module aka Customware" 600 "Aquatic AV" 605 "Aventics" 606 "Intellian" 612 "SamwonIT" 614 "Arlt Tecnologies" 637 "Bavaria Yachts" 641 "Diverse Yacht Services" 644 "Wema U.S.A dba KUS" 658 "Shenzhen Jiuzhou Himunication" 688 "Rockford" 699 "Harman International" 704 "JL Audio" 708 "Lars Thrane" 715 "Autonnic" 717 "Yacht Devices" 734 "REAP Systems" 735 "AEM Performance Electronics" 739 "LxNav" 741 "Littelfuse, Inc (formerly Carling Technologies)" 743 "DaeMyung" 744 "Woosung" 748 "ISOTTA IFRA srl" 773 "Clarion US" 776 "HMI Systems" 777 "Ocean Signal" 778 "Seakeeper" 781 "Poly Planar" 785 "Fischer Panda DE" 795 "Broyda Industries" 796 "Canadian Automotive" 797 "Tides Marine" 798 "Lumishore" 799 "Still Water Designs and Audio" 802 "BJ Technologies (Beneteau)" 803 "Gill Sensors" 811 "Blue Water Desalination" 815 "FLIR" 824 "Undheim Systems" 826 "Lewmar" 838 "TeamSurv" 844 "Fell Marine" 847 "Oceanvolt" 862 "Prospec" 868 "Data Panel" 890 "L3 Technologies" 894 "Rhodan Marine Systems" 896 "Nexfour Solutions" 905 "ASA Electronics" 909 "Marines Co (South Korea)" 911 "Nautic-on" 917 "Sentinel" 929 "JL Marine Systems" 930 "Ecotronix" 944 "Zontisa Marine" 951 "EXOR International" 962 "Timbolier Industries" 963 "TJC Micro" 968 "Cox Powertrain" 969 "Blue Seas" 981 "Kobelt Manufacturing" 992 "Blue Ocean IOT" 997 "Xenta Systems" 999 "Signal K" 1004 "Ultraflex" 1008 "Lintest SmartBoat" 1011 "Soundmax" 1020 "Team Italia Marine (Onyx Marine Automation s.r.l)" 1021 "Entratech" 1022 "ITC" 1029 "The Marine Guardian" 1047 "Sonic" 1051 "ProNav" 1053 "Vetus Maxwell INC." 1056 "Lithium Pros" 1059 "Boatrax" 1062 "Marol Co ltd" 1065 "CALYPSO Instruments" 1066 "Spot Zero Water" 1069 "Lithionics Battery" 1070 "Quick-teck Electronics" 1075 "Uniden America" 1083 "Nauticoncept" 1084 "Shadow-Caster LED lighting" 1085 "Wet Sounds" 1088 "E-T-A Circuit Breakers" 1092 "Scheiber" 1100 "Smart Yachts International Limited" 1109 "Dockmate" 1114 "Bobs Machine" 1118 "L3Harris ASV" 1119 "Balmar" 1120 "Elettromedia" 1127 "Electromaax" 1140 "Across Oceans Systems" 1145 "Kiwi Yachting" 1150 "BSB Artificial Intelligence" 1151 "Orca Technologies" 1154 "TBS Electronics" 1158 "Technoton Electroics" 1160 "MG Energy Systems" 1169 "Sea Machine Robotics" 1171 "Vista Manufacturing" 1183 "Zipwake" 1186 "Sailmon" 1192 "Airmoniq Pro Kft" 1194 "Sierra Marine" 1200 "Xinuo Information Technology (Xiamen)" 1218 "Septentrio" 1233 "NKE Marine Electronics" 1238 "SuperTrack Aps" 1239 "Honda Electronics" 1245 "Raritan Engineering" 1249 "Integrated Power Solutions AG" 1260 "Interactive Technologies" 1283 "LTG-Tech" 1299 "Energy Solutions (UK)" 1300 "WATT Fuel Cell" 1302 "Pro Mainer" 1305 "Dragonfly Energy" 1306 "Koden Electronics" 1311 "Humphree" 1316 "Hinkley Yachts" 1317 "Global Marine Management GmbH (GMM)" 1320 "Triskel Marine" 1330 "Warwick Control Technologies" 1331 "Dolphin Charger" 1337 "Barnacle Systems" 1348 "Radian IoT" 1353 "Ocean LED Marine" 1359 "BluNav" 1361 "OVA (Nantong Saiyang Electronics Co., Ltd)" 1368 "RAD Propulsion" 1369 "Electric Yacht" 1372 "Elco Motor Yachts" 1384 "Tecnoseal Foundry S.r.l" 1385 "Pro Charging Systems" 1389 "EVEX" 1398 "Gobius Sensor Technology" 1403 "Arco Marine" 1408 "Lenco Marine" 1413 "Naocontrol" 1417 "Revatek" 1438 "Aeolionics" 1439 "PredictWind" 1440 "Egis Mobile Electric" 1445 "Starboard Yacht Group" 1446 "Roswell Marine" 1451 "ePropulsion (Guangdong ePropulsion Technology Ltd.)" 1452 "Micro-Air" 1453 "Vital Battery" 1458 "Ride Controller" 1460 "Tocaro Blue" 1461 "Vanquish Yachts" 1471 "FT Technologies" 1478 "Alps Alpine" 1481 "E-Force Marine" 1482 "CMC Marine" 1483 "Nanjing Sandemarine Information Technology" 1850 "Teleflex Marine (SeaStar Solutions)" 1851 "Raymarine" 1852 "Navionics" 1853 "Japan Radio" 1854 "Northstar Technologies" 1855 "Furuno" 1856 "Trimble" 1857 "Simrad" 1858 "Litton" 1859 "Kvasar" 1860 "MMP" 1861 "Vector Cantech" 1862 "Yamaha Marine" 1863 "Faria Instruments" ;
VAL_ 2566850816 Industry_Code 0 "Global" 1 "Highway" 2 "Agriculture" 3 "Construction" 4 "Marine Industry" 5 "Industrial" ;
VAL_ 2566851072 Manufacturer_Code 69 "ARKS Enterprises" 78 "FW Murphy/Enovation Controls" 80 "Twin Disc" 85 "Kohler Power Systems" 88 "Hemisphere GPS" 135 "Airmar" 137 "Maretron" 140 "Lowrance" 144 "Mercury Marine" 147 "Nautibus Electronic" 148 "Blue Water Data" 154 "Westerbeke" 157 "ISSPRO" 161 "Offshore Systems (UK)" 163 "Evinrude/BRP" 165 "CPAC Systems" 168 "Xantrex Technology" 169 "Marlin Technologies" 172 "Yanmar Marine" 174 "Volvo Penta" 176 "Carling Technologies Inc. (Moritz Aerospace)" 185 "Beede Instruments" 192 "Floscan Instrument" 193 "Nobeltec" 198 "Mystic Valley Communications" 199 "Actia" 201 "Disenos Y Technologia" 211 "Digital Switching Systems" 215 "Xintex/Atena" 224 "EMMI NETWORK" 228 "ZF" 229 "Garmin" 233 "Yacht Monitoring Solutions" 235 "Sailormade Marine Telemetry/Tetra Technology" 243 "Eride" 257 "Honda Motor" 272 "Groco" 273 "Actisense" 274 "Amphenol LTW Technology" 275 "Navico" 283 "Hamilton Jet" 285 "Sea Recovery" 286 "Coelmo SRL Italy" 295 "BEP Marine" 304 "Empir Bus" 305 "NovAtel" 306 "Sleipner Motor" 307 "MBW Technologies" 315 "ICOM" 328 "Qwerty" 329 "Dief" 341 "Boening Automationstechnologie" 345 "Korean Maritime University" 351 "Thrane and Thrane" 355 "Mastervolt" 356 "Fischer Panda Generators" 358 "Victron Energy" 370 "Rolls Royce Marine" 373 "Electronic Design" 374 "Northern Lights" 378 "Glendinning" 381 "B & G" 384 "Rose Point Navigation Systems" 385 "Johnson Outdoors Marine Electronics Inc Geonav" 394 "Capi 2" 396 "Beyond Measure" 400 "Livorsi Marine" 404 "ComNav" 409 "Chetco" 419 "Fusion Electronics" 421 "Standard Horizon" 422 "True Heading" 426 "Egersund Marine Electronics" 427 "em-trak Marine Electronics" 431 "Tohatsu Co, JP" 437 "Digital Yacht" 438 "Comar Systems Limited" 440 "Cummins" 443 "VDO (aka Continental-Corporation)" 451 "Parker Hannifin aka Village Marine Tech" 459 "Alltek Marine Electronics" 460 "SAN GIORGIO S.E.I.N" 466 "Veethree Electronics & Marine" 470 "SI-TEX Marine Electronics" 471 "Sea Cross Marine" 475 "GME aka Standard Communications" 476 "Humminbird Marine Electronics" 478 "Ocean Sat" 481 "Chetco Digital Instruments" 493 "Watcheye" 499 "Lcj Capteurs" 502 "Attwood Marine" 503 "Naviop S.R.L." 504 "Vesper Marine" 510 "Marinesoft" 513 "Simarine" 517 "NoLand Engineering" 518 "Transas USA" 529 "National Instruments Korea" 530 "National Marine Electronics Association" 532 "Onwa Marine" 540 "Webasto" 571 "Marinecraft (South Korea)" 573 "McMurdo Group aka Orolia" 578 "Advansea" 579 "KVH" 580 "San Jose Technology" 583 "Yacht Control" 586 "Suzuki Motor" 591 "US Coast Guard" 595 "Ship Module aka Customware" 600 "Aquatic AV" 605 "Aventics" 606 "Intellian" 612 "SamwonIT" 614 "Arlt Tecnologies" 637 "Bavaria Yachts" 641 "Diverse Yacht Services" 644 "Wema U.S.A dba KUS" 658 "Shenzhen Jiuzhou Himunication" 688 "Rockford" 699 "Harman International" 704 "JL Audio" 708 "Lars Thrane" 715 "Autonnic" 717 "Yacht Devices" 734 "REAP Systems" 735 "AEM Performance Electronics" 739 "LxNav" 741 "Littelfuse, Inc (formerly Carling Technologies)" 743 "DaeMyung" 744 "Woosung" 748 "ISOTTA IFRA srl" 773 "Clarion US" 776 "HMI Systems" 777 "Ocean Signal" 778 "Seakeeper" 781 "Poly Planar" 785 "Fischer Panda DE" 795 "Broyda Industries" 796 "Canadian Automotive" 797 "Tides Marine" 798 "Lumishore" 799 "Still Water Designs and Audio" 802 "BJ Technologies (Beneteau)" 803 "Gill Sensors" 811 "Blue Water Desalination" 815 "FLIR" 824 "Undheim Systems" 826 "Lewmar" 838 "TeamSurv" 844 "Fell Marine" 847 "Oceanvolt" 862 "Prospec" 868 "Data Panel" 890 "L3 Technologies" 894 "Rhodan Marine Systems" 896 "Nexfour Solutions" 905 "ASA Electronics" 909 "Marines Co (South Korea)" 911 "Nautic-on" 917 "Sentinel" 929 "JL Marine Systems" 930 "Ecotronix" 944 "Zontisa Marine" 951 "EXOR International" 962 "Timbolier Industries" 963 "TJC Micro" 968 "Cox Powertrain" 969 "Blue Seas" 981 "Kobelt Manufacturing" 992 "Blue Ocean IOT" 997 "Xenta Systems" 999 "Signal K" 1004 "Ultraflex" 1008 "Lintest SmartBoat" 1011 "Soundmax" 1020 "Team Italia Marine (Onyx Marine Automation s.r.l)" 1021 "Entratech" 1022 "ITC" 1029 "The Marine Guardian" 1047 "Sonic" 1051 "ProNav" 1053 "Vetus Maxwell INC." 1056 "Lithium Pros" 1059 "Boatrax" 1062 "Marol Co ltd" 1065 "CALYPSO Instruments" 1066 "Spot Zero Water" 1069 "Lithionics Battery" 1070 "Quick-teck Electronics" 1075 "Uniden America" 1083 "Nauticoncept" 1084 "Shadow-Caster LED lighting" 1085 "Wet Sounds" 1088 "E-T-A Circuit Breakers" 1092 "Scheiber" 1100 "Smart Yachts International Limited" 1109 "Dockmate" 1114 "Bobs Machine" 1118 "L3Harris ASV" 1119 "Balmar" 1120 "Elettromedia" 1127 "Electromaax" 1140 "Across Oceans Systems" 1145 "Kiwi Yachting" 1150 "BSB Artificial Intelligence" 1151 "Orca Technologies" 1154 "TBS Electronics" 1158 "Technoton Electroics" 1160 "MG Energy Systems" 1169 "Sea Machine Robotics" 1171 "Vista Manufacturing" 1183 "Zipwake" 1186 "Sailmon" 1192 "Airmoniq Pro Kft" 1194 "Sierra Marine" 1200 "Xinuo Information Technology (Xiamen)" 1218 "Septentrio" 1233 "NKE Marine Electronics" 1238 "SuperTrack Aps" 1239 "Honda Electronics" 1245 "Raritan Engineering" 1249 "Integrated Power Solutions AG" 1260 "Interactive Technologies" 1283 "LTG-Tech" 1299 "Energy Solutions (UK)" 1300 "WATT Fuel Cell" 1302 "Pro Mainer" 1305 "Dragonfly Energy" 1306 "Koden Electronics" 1311 "Humphree" 1316 "Hinkley Yachts" 1317 "Global Marine Management GmbH (GMM)" 1320 "Triskel Marine" 1330 "Warwick Control Technologies" 1331 "Dolphin Charger" 1337 "Barnacle Systems" 1348 "Radian IoT" 1353 "Ocean LED Marine" 1359 "BluNav" 1361 "OVA (Nantong Saiyang Electronics Co., Ltd)" 1368 "RAD Propulsion" 1369 "Electric Yacht" 1372 "Elco Motor Yachts" 1384 "Tecnoseal Foundry S.r.l" 1385 "Pro Charging Systems" 1389 "EVEX" 1398 "Gobius Sensor Technology" 1403 "Arco Marine" 1408 "Lenco Marine" 1413 "Naocontrol" 1417 "Revatek" 1438 "Aeolionics" 1439 "PredictWind" 1440 "Egis Mobile Electric" 1445 "Starboard Yacht Group" 1446 "Roswell Marine" 1451 "ePropulsion (Guangdong ePropulsion Technology Ltd.)" 1452 "Micro-Air" 1453 "Vital Battery" 1458 "Ride Controller" 1460 "Tocaro Blue" 1461 "Vanquish Yachts" 1471 "FT Technologies" 1478 "Alps Alpine" 1481 "E-Force Marine" 1482 "CMC Marine" 1483 "Nanjing Sandemarine Information Technology" 1850 "Teleflex Marine (SeaStar Solutions)" 1851 "Raymarine" 1852 "Navionics" 1853 "Japan Radio" 1854 "Northstar Technologies" 1855 "Furuno" 1856 "Trimble" 1857 "Simrad" 1858 "Litton" 1859 "Kvasar" 1860 "MMP" 1861 "Vector Cantech" 1862 "Yamaha Marine" 1863 "Faria Instruments" ;
VAL_ 2566851072 Industry_Code 0 "Global" 1 "Highway" 2 "Agriculture" 3 "Construction" 4 "Marine Industry" 5 "Industrial" ;
VAL_ 2499742208 Manufacturer_Code 69 "ARKS Enterprises" 78 "FW Murphy/Enovation Controls" 80 "Twin Disc" 85 "Kohler Power Systems" 88 "Hemisphere GPS" 135 "Airmar" 137 "Maretron" 140 "Lowrance" 144 "Mercury Marine" 147 "Nautibus Electronic" 148 "Blue Water Data" 154 "Westerbeke" 157 "ISSPRO" 161 "Offshore Systems (UK)" 163 "Evinrude/BRP" 165 "CPAC Systems" 168 "Xantrex Technology" 169 "Marlin Technologies" 172 "Yanmar Marine" 174 "Volvo Penta" 176 "Carling Technologies Inc. (Moritz Aerospace)" 185 "Beede Instruments" 192 "Floscan Instrument" 193 "Nobeltec" 198 "Mystic Valley Communications" 199 "Actia" 201 "Disenos Y Technologia" 211 "Digital Switching Systems" 215 "Xintex/Atena" 224 "EMMI NETWORK" 228 "ZF" 229 "Garmin" 233 "Yacht Monitoring Solutions" 235 "Sailormade Marine Telemetry/Tetra Technology" 243 "Eride" 257 "Honda Motor" 272 "Groco" 273 "Actisense" 274 "Amphenol LTW Technology" 275 "Navico" 283 "Hamilton Jet" 285 "Sea Recovery" 286 "Coelmo SRL Italy" 295 "BEP Marine" 304 "Empir Bus" 305 "NovAtel" 306 "Sleipner Motor" 307 "MBW Technologies" 315 "ICOM" 328 "Qwerty" 329 "Dief" 341 "Boening Automationstechnologie" 345 "Korean Maritime University" 351 "Thrane and Thrane" 355 "Mastervolt" 356 "Fischer Panda Generators" 358 "Victron Energy" 370 "Rolls Royce Marine" 373 "Electronic Design" 374 "Northern Lights" 378 "Glendinning" 381 "B & G" 384 "Rose Point Navigation Systems" 385 "Johnson Outdoors Marine Electronics Inc Geonav" 394 "Capi 2" 396 "Beyond Measure" 400 "Livorsi Marine" 404 "ComNav" 409 "Chetco" 419 "Fusion Electronics" 421 "Standard Horizon" 422 "True Heading" 426 "Egersund Marine Electronics" 427 "em-trak Marine Electronics" 431 "Tohatsu Co, JP" 437 "Digital Yacht" 438 "Comar Systems Limited" 440 "Cummins" 443 "VDO (aka Continental-Corporation)" 451 "Parker Hannifin aka Village Marine Tech" 459 "Alltek Marine Electronics" 460 "SAN GIORGIO S.E.I.N" 466 "Veethree Electronics & Marine" 470 "SI-TEX Marine Electronics" 471 "Sea Cross Marine" 475 "GME aka Standard Communications" 476 "Humminbird Marine Electronics" 478 "Ocean Sat" 481 "Chetco Digital Instruments" 493 "Watcheye" 499 "Lcj Capteurs" 502 "Attwood Marine" 503 "Naviop S.R.L." 504 "Vesper Marine" 510 "Marinesoft" 513 "Simarine" 517 "NoLand Engineering" 518 "Transas USA" 529 "National Instruments Korea" 530 "National Marine Electronics Association" 532 "Onwa Marine" 540 "Webasto" 571 "Marinecraft (South Korea)" 573 "McMurdo Group aka Orolia" 578 "Advansea" 579 "KVH" 580 "San Jose Technology" 583 "Yacht Control" 586 "Suzuki Motor" 591 "US Coast Guard" 595 "Ship Module aka Customware" 600 "Aquatic AV" 605 "Aventics" 606 "Intellian" 612 "SamwonIT" 614 "Arlt Tecnologies" 637 "Bavaria Yachts" 641 "Diverse Yacht Services" 644 "Wema U.S.A dba KUS" 658 "Shenzhen Jiuzhou Himunication" 688 "Rockford" 699 "Harman International" 704 "JL Audio" 708 "Lars Thrane" 715 "Autonnic" 717 "Yacht Devices" 734 "REAP Systems" 735 "AEM Performance Electronics" 739 "LxNav" 741 "Littelfuse, Inc (formerly Carling Technologies)" 743 "DaeMyung" 744 "Woosung" 748 "ISOTTA IFRA srl" 773 "Clarion US" 776 "HMI Systems" 777 "Ocean Signal" 778 "Seakeeper" 781 "Poly Planar" 785 "Fischer Panda DE" 795 "Broyda Industries" 796 "Canadian Automotive" 797 "Tides Marine" 798 "Lumishore" 799 "Still Water Designs and Audio" 802 "BJ Technologies (Beneteau)" 803 "Gill Sensors" 811 "Blue Water Desalination" 815 "FLIR" 824 "Undheim Systems" 826 "Lewmar" 838 "TeamSurv" 844 "Fell Marine" 847 "Oceanvolt" 862 "Prospec" 868 "Data Panel" 890 "L3 Technologies" 894 "Rhodan Marine Systems" 896 "Nexfour Solutions" 905 "ASA Electronics" 909 "Marines Co (South Korea)" 911 "Nautic-on" 917 "Sentinel" 929 "JL Marine Systems" 930 "Ecotronix" 944 "Zontisa Marine" 951 "EXOR International" 962 "Timbolier Industries" 963 "TJC Micro" 968 "Cox Powertrain" 969 "Blue Seas" 981 "Kobelt Manufacturing" 992 "Blue Ocean IOT" 997 "Xenta Systems" 999 "Signal K" 1004 "Ultraflex" 1008 "Lintest SmartBoat" 1011 "Soundmax" 1020 "Team Italia Marine (Onyx Marine Automation s.r.l)" 1021 "Entratech" 1022 "ITC" 1029 "The Marine Guardian" 1047 "Sonic" 1051 "ProNav" 1053 "Vetus Maxwell INC." 1056 "Lithium Pros" 1059 "Boatrax" 1062 "Marol Co ltd" 1065 "CALYPSO Instruments" 1066 "Spot Zero Water" 1069 "Lithionics Battery" 1070 "Quick-teck Electronics" 1075 "Uniden America" 1083 "Nauticoncept" 1084 "Shadow-Caster LED lighting" 1085 "Wet Sounds" 1088 "E-T-A Circuit Breakers" 1092 "Scheiber" 1100 "Smart Yachts International Limited" 1109 "Dockmate" 1114 "Bobs Machine" 1118 "L3Harris ASV" 1119 "Balmar" 1120 "Elettromedia" 1127 "Electromaax" 1140 "Across Oceans Systems" 1145 "Kiwi Yachting" 1150 "BSB Artificial Intelligence" 1151 "Orca Technologies" 1154 "TBS Electronics" 1158 "Technoton Electroics" 1160 "MG Energy Systems" 1169 "Sea Machine Robotics" 1171 "Vista Manufacturing" 1183 "Zipwake" 1186 "Sailmon" 1192 "Airmoniq Pro Kft" 1194 "Sierra Marine" 1200 "Xinuo Information Technology (Xiamen)" 1218 "Septentrio" 1233 "NKE Marine Electronics" 1238 "SuperTrack Aps" 1239 "Honda Electronics" 1245 "Raritan Engineering" 1249 "Integrated Power Solutions AG" 1260 "Interactive Technologies" 1283 "LTG-Tech" 1299 "Energy Solutions (UK)" 1300 "WATT Fuel Cell" 1302 "Pro Mainer" 1305 "Dragonfly Energy" 1306 "Koden Electronics" 1311 "Humphree" 1316 "Hinkley Yachts" 1317 "Global Marine Management GmbH (GMM)" 1320 "Triskel Marine" 1330 "Warwick Control Technologies" 1331 "Dolphin Charger" 1337 "Barnacle Systems" 1348 "Radian IoT" 1353 "Ocean LED Marine" 1359 "BluNav" 1361 "OVA (Nantong Saiyang Electronics Co., Ltd)" 1368 "RAD Propulsion" 1369 "Electric Yacht" 1372 "Elco Motor Yachts" 1384 "Tecnoseal Foundry S.r.l" 1385 "Pro Charging Systems" 1389 "EVEX" 1398 "Gobius Sensor Technology" 1403 "Arco Marine" 1408 "Lenco Marine" 1413 "Naocontrol" 1417 "Revatek" 1438 "Aeolionics" 1439 "PredictWind" 1440 "Egis Mobile Electric" 1445 "Starboard Yacht Group" 1446 "Roswell Marine" 1451 "ePropulsion (Guangdong ePropulsion Technology Ltd.)" 1452 "Micro-Air" 1453 "Vital Battery" 1458 "Ride Controller" 1460 "Tocaro Blue" 1461 "Vanquish Yachts" 1471 "FT Technologies" 1478 "Alps Alpine" 1481 "E-Force Marine" 1482 "CMC Marine" 1483 "Nanjing Sandemarine Information Technology" 1850 "Teleflex Marine (SeaStar Solutions)" 1851 "Raymarine" 1852 "Navionics" 1853 "Japan Radio" 1854 "Northstar Technologies" 1855 "Furuno" 1856 "Trimble" 1857 "Simrad" 1858 "Litton" 1859 "Kvasar" 1860 "MMP" 1861 "Vector Cantech" 1862 "Yamaha Marine" 1863 "Faria Instruments" ;
VAL_ 2499742208 Industry_Code 0 "Global" 1 "Highway" 2 "Agriculture" 3 "Construction" 4 "Marine Industry" 5 "Industrial" ;
VAL_ 2566851072 Manufacturer_Code 69 "ARKS Enterprises" 78 "FW Murphy/Enovation Controls" 80 "Twin Disc" 85 "Kohler Power Systems" 88 "Hemisphere GPS" 135 "Airmar" 137 "Maretron" 140 "Lowrance" 144 "Mercury Marine" 147 "Nautibus Electronic" 148 "Blue Water Data" 154 "Westerbeke" 157 "ISSPRO" 161 "Offshore Systems (UK)" 163 "Evinrude/BRP" 165 "CPAC Systems" 168 "Xantrex Technology" 169 "Marlin Technologies" 172 "Yanmar Marine" 174 "Volvo Penta" 176 "Carling Technologies Inc. (Moritz Aerospace)" 185 "Beede Instruments" 192 "Floscan Instrument" 193 "Nobeltec" 198 "Mystic Valley Communications" 199 "Actia" 201 "Disenos Y Technologia" 211 "Digital Switching Systems" 215 "Xintex/Atena" 224 "EMMI NETWORK" 228 "ZF" 229 "Garmin" 233 "Yacht Monitoring Solutions" 235 "Sailormade Marine Telemetry/Tetra Technology" 243 "Eride" 257 "Honda Motor" 272 "Groco" 273 "Actisense" 274 "Amphenol LTW Technology" 275 "Navico" 283 "Hamilton Jet" 285 "Sea Recovery" 286 "Coelmo SRL Italy" 295 "BEP Marine" 304 "Empir Bus" 305 "NovAtel" 306 "Sleipner Motor" 307 "MBW Technologies" 315 "ICOM" 328 "Qwerty" 329 "Dief" 341 "Boening Automationstechnologie" 345 "Korean Maritime University" 351 "Thrane and Thrane" 355 "Mastervolt" 356 "Fischer Panda Generators" 358 "Victron Energy" 370 "Rolls Royce Marine" 373 "Electronic Design" 374 "Northern Lights" 378 "Glendinning" 381 "B & G" 384 "Rose Point Navigation Systems" 385 "Johnson Outdoors Marine Electronics Inc Geonav" 394 "Capi 2" 396 "Beyond Measure" 400 "Livorsi Marine" 404 "ComNav" 409 "Chetco" 419 "Fusion Electronics" 421 "Standard Horizon" 422 "True Heading" 426 "Egersund Marine Electronics" 427 "em-trak Marine Electronics" 431 "Tohatsu Co, JP" 437 "Digital Yacht" 438 "Comar Systems Limited" 440 "Cummins" 443 "VDO (aka Continental-Corporation)" 451 "Parker Hannifin aka Village Marine Tech" 459 "Alltek Marine Electronics" 460 "SAN GIORGIO S.E.I.N" 466 "Veethree Electronics & Marine" 470 "SI-TEX Marine Electronics" 471 "Sea Cross Marine" 475 "GME aka Standard Communications" 476 "Humminbird Marine Electronics" 478 "Ocean Sat" 481 "Chetco Digital Instruments" 493 "Watcheye" 499 "Lcj Capteurs" 502 "Attwood Marine" 503 "Naviop S.R.L." 504 "Vesper Marine" 510 "Marinesoft" 513 "Simarine" 517 "NoLand Engineering" 518 "Transas USA" 529 "National Instruments Korea" 530 "National Marine Electronics Association" 532 "Onwa Marine" 540 "Webasto" 571 "Marinecraft (South Korea)" 573 "McMurdo Group aka Orolia" 578 "Advansea" 579 "KVH" 580 "San Jose Technology" 583 "Yacht Control" 586 "Suzuki Motor" 591 "US Coast Guard" 595 "Ship Module aka Customware" 600 "Aquatic AV" 605 "Aventics" 606 "Intellian" 612 "SamwonIT" 614 "Arlt Tecnologies" 637 "Bavaria Yachts" 641 "Diverse Yacht Services" 644 "Wema U.S.A dba KUS" 658 "Shenzhen Jiuzhou Himunication" 688 "Rockford" 699 "Harman International" 704 "JL Audio" 708 "Lars Thrane" 715 "Autonnic" 717 "Yacht Devices" 734 "REAP Systems" 735 "AEM Performance Electronics" 739 "LxNav" 741 "Littelfuse, Inc (formerly Carling Technologies)" 743 "DaeMyung" 744 "Woosung" 748 "ISOTTA IFRA srl" 773 "Clarion US" 776 "HMI Systems" 777 "Ocean Signal" 778 "Seakeeper" 781 "Poly Planar" 785 "Fischer Panda DE" 795 "Broyda Industries" 796 "Canadian Automotive" 797 "Tides Marine" 798 "Lumishore" 799 "Still Water Designs and Audio" 802 "BJ Technologies (Beneteau)" 803 "Gill Sensors" 811 "Blue Water Desalination" 815 "FLIR" 824 "Undheim Systems" 826 "Lewmar" 838 "TeamSurv" 844 "Fell Marine" 847 "Oceanvolt" 862 "Prospec" 868 "Data Panel" 890 "L3 Technologies" 894 "Rhodan Marine Systems" 896 "Nexfour Solutions" 905 "ASA Electronics" 909 "Marines Co (South Korea)" 911 "Nautic-on" 917 "Sentinel" 929 "JL Marine Systems" 930 "Ecotronix" 944 "Zontisa Marine" 951 "EXOR International" 962 "Timbolier Industries" 963 "TJC Micro" 968 "Cox Powertrain" 969 "Blue Seas" 981 "Kobelt Manufacturing" 992 "Blue Ocean IOT" 997 "Xenta Systems" 999 "Signal K" 1004 "Ultraflex" 1008 "Lintest SmartBoat" 1011 "Soundmax" 1020 "Team Italia Marine (Onyx Marine Automation s.r.l)" 1021 "Entratech" 1022 "ITC" 1029 "The Marine Guardian" 1047 "Sonic" 1051 "ProNav" 1053 "Vetus Maxwell INC." 1056 "Lithium Pros" 1059 "Boatrax" 1062 "Marol Co ltd" 1065 "CALYPSO Instruments" 1066 "Spot Zero Water" 1069 "Lithionics Battery" 1070 "Quick-teck Electronics" 1075 "Uniden America" 1083 "Nauticoncept" 1084 "Shadow-Caster LED lighting" 1085 "Wet Sounds" 1088 "E-T-A Circuit Breakers" 1092 "Scheiber" 1100 "Smart Yachts International Limited" 1109 "Dockmate" 1114 "Bobs Machine" 1118 "L3Harris ASV" 1119 "Balmar" 1120 "Elettromedia" 1127 "Electromaax" 1140 "Across Oceans Systems" 1145 "Kiwi Yachting" 1150 "BSB Artificial Intelligence" 1151 "Orca Technologies" 1154 "TBS Electronics" 1158 "Technoton Electroics" 1160 "MG Energy Systems" 1169 "Sea Machine Robotics" 1171 "Vista Manufacturing" 1183 "Zipwake" 1186 "Sailmon" 1192 "Airmoniq Pro Kft" 1194 "Sierra Marine" 1200 "Xinuo Information Technology (Xiamen)" 1218 "Septentrio" 1233 "NKE Marine Electronics" 1238 "SuperTrack Aps" 1239 "Honda Electronics" 1245 "Raritan Engineering" 1249 "Integrated Power Solutions AG" 1260 "Interactive Technologies" 1283 "LTG-Tech" 1299 "Energy Solutions (UK)" 1300 "WATT Fuel Cell" 1302 "Pro Mainer" 1305 "Dragonfly Energy" 1306 "Koden Electronics" 1311 "Humphree" 1316 "Hinkley Yachts" 1317 "Global Marine Management GmbH (GMM)" 1320 "Triskel Marine" 1330 "Warwick Control Technologies" 1331 "Dolphin Charger" 1337 "Barnacle Systems" 1348 "Radian IoT" 1353 "Ocean LED Marine" 1359 "BluNav" 1361 "OVA (Nantong Saiyang Electronics Co., Ltd)" 1368 "RAD Propulsion" 1369 "Electric Yacht" 1372 "Elco Motor Yachts" 1384 "Tecnoseal Foundry S.r.l" 1385 "Pro Charging Systems" 1389 "EVEX" 1398 "Gobius Sensor Technology" 1403 "Arco Marine" 1408 "Lenco Marine" 1413 "Naocontrol" 1417 "Revatek" 1438 "Aeolionics" 1439 "PredictWind" 1440 "Egis Mobile Electric" 1445 "Starboard Yacht Group" 1446 "Roswell Marine" 1451 "ePropulsion (Guangdong ePropulsion Technology Ltd.)" 1452 "Micro-Air" 1453 "Vital Battery" 1458 "Ride Controller" 1460 "Tocaro Blue" 1461 "Vanquish Yachts" 1471 "FT Technologies" 1478 "Alps Alpine" 1481 "E-Force Marine" 1482 "CMC Marine" 1483 "Nanjing Sandemarine Information Technology" 1850 "Teleflex Marine (SeaStar Solutions)" 1851 "Raymarine" 1852 "Navionics" 1853 "Japan Radio" 1854 "Northstar Technologies" 1855 "Furuno" 1856 "Trimble" 1857 "Simrad" 1858 "Litton" 1859 "Kvasar" 1860 "MMP" 1861 "Vector Cantech" 1862 "Yamaha Marine" 1863 "Faria Instruments" ;
VAL_ 2566851072 Industry_Code 0 "Global" 1 "Highway" 2 "Agriculture" 3 "Construction" 4 "Marine Industry" 5 "Industrial" ;
VAL_ 2499742464 Manufacturer_Code 69 "ARKS Enterprises" 78 "FW Murphy/Enovation Controls" 80 "Twin Disc" 85 "Kohler Power Systems" 88 "Hemisphere GPS" 135 "Airmar" 137 "Maretron" 140 "Lowrance" 144 "Mercury Marine" 147 "Nautibus Electronic" 148 "Blue Water Data" 154 "Westerbeke" 157 "ISSPRO" 161 "Offshore Systems (UK)" 163 "Evinrude/BRP" 165 "CPAC Systems" 168 "Xantrex Technology" 169 "Marlin Technologies" 172 "Yanmar Marine" 174 "Volvo Penta" 176 "Carling Technologies Inc. (Moritz Aerospace)" 185 "Beede Instruments" 192 "Floscan Instrument" 193 "Nobeltec" 198 "Mystic Valley Communications" 199 "Actia" 201 "Disenos Y Technologia" 211 "Digital Switching Systems" 215 "Xintex/Atena" 224 "EMMI NETWORK" 228 "ZF" 229 "Garmin" 233 "Yacht Monitoring Solutions" 235 "Sailormade Marine Telemetry/Tetra Technology" 243 "Eride" 257 "Honda Motor" 272 "Groco" 273 "Actisense" 274 "Amphenol LTW Technology" 275 "Navico" 283 "Hamilton Jet" 285 "Sea Recovery" 286 "Coelmo SRL Italy" 295 "BEP Marine" 304 "Empir Bus" 305 "NovAtel" 306 "Sleipner Motor" 307 "MBW Technologies" 315 "ICOM" 328 "Qwerty" 329 "Dief" 341 "Boening Automationstechnologie" 345 "Korean Maritime University" 351 "Thrane and Thrane" 355 "Mastervolt" 356 "Fischer Panda Generators" 358 "Victron Energy" 370 "Rolls Royce Marine" 373 "Electronic Design" 374 "Northern Lights" 378 "Glendinning" 381 "B & G" 384 "Rose Point Navigation Systems" 385 "Johnson Outdoors Marine Electronics Inc Geonav" 394 "Capi 2" 396 "Beyond Measure" 400 "Livorsi Marine" 404 "ComNav" 409 "Chetco" 419 "Fusion Electronics" 421 "Standard Horizon" 422 "True Heading" 426 "Egersund Marine Electronics" 427 "em-trak Marine Electronics" 431 "Tohatsu Co, JP" 437 "Digital Yacht" 438 "Comar Systems Limited" 440 "Cummins" 443 "VDO (aka Continental-Corporation)" 451 "Parker Hannifin aka Village Marine Tech" 459 "Alltek Marine Electronics" 460 "SAN GIORGIO S.E.I.N" 466 "Veethree Electronics & Marine" 470 "SI-TEX Marine Electronics" 471 "Sea Cross Marine" 475 "GME aka Standard Communications" 476 "Humminbird Marine Electronics" 478 "Ocean Sat" 481 "Chetco Digital Instruments" 493 "Watcheye" 499 "Lcj Capteurs" 502 "Attwood Marine" 503 "Naviop S.R.L." 504 "Vesper Marine" 510 "Marinesoft" 513 "Simarine" 517 "NoLand Engineering" 518 "Transas USA" 529 "National Instruments Korea" 530 "National Marine Electronics Association" 532 "Onwa Marine" 540 "Webasto" 571 "Marinecraft (South Korea)" 573 "McMurdo Group aka Orolia" 578 "Advansea" 579 "KVH" 580 "San Jose Technology" 583 "Yacht Control" 586 "Suzuki Motor" 591 "US Coast Guard" 595 "Ship Module aka Customware" 600 "Aquatic AV" 605 "Aventics" 606 "Intellian" 612 "SamwonIT" 614 "Arlt Tecnologies" 637 "Bavaria Yachts" 641 "Diverse Yacht Services" 644 "Wema U.S.A dba KUS" 658 "Shenzhen Jiuzhou Himunication" 688 "Rockford" 699 "Harman International" 704 "JL Audio" 708 "Lars Thrane" 715 "Autonnic" 717 "Yacht Devices" 734 "REAP Systems" 735 "AEM Performance Electronics" 739 "LxNav" 741 "Littelfuse, Inc (formerly Carling Technologies)" 743 "DaeMyung" 744 "Woosung" 748 "ISOTTA IFRA srl" 773 "Clarion US" 776 "HMI Systems" 777 "Ocean Signal" 778 "Seakeeper" 781 "Poly Planar" 785 "Fischer Panda DE" 795 "Broyda Industries" 796 "Canadian Automotive" 797 "Tides Marine" 798 "Lumishore" 799 "Still Water Designs and Audio" 802 "BJ Technologies (Beneteau)" 803 "Gill Sensors" 811 "Blue Water Desalination" 815 "FLIR" 824 "Undheim Systems" 826 "Lewmar" 838 "TeamSurv" 844 "Fell Marine" 847 "Oceanvolt" 862 "Prospec" 868 "Data Panel" 890 "L3 Technologies" 894 "Rhodan Marine Systems" 896 "Nexfour Solutions" 905 "ASA Electronics" 909 "Marines Co (South Korea)" 911 "Nautic-on" 917 "Sentinel" 929 "JL Marine Systems" 930 "Ecotronix" 944 "Zontisa Marine" 951 "EXOR International" 962 "Timbolier Industries" 963 "TJC Micro" 968 "Cox Powertrain" 969 "Blue Seas" 981 "Kobelt Manufacturing" 992 "Blue Ocean IOT" 997 "Xenta Systems" 999 "Signal K" 1004 "Ultraflex" 1008 "Lintest SmartBoat" 1011 "Soundmax" 1020 "Team Italia Marine (Onyx Marine Automation s.r.l)" 1021 "Entratech" 1022 "ITC" 1029 "The Marine Guardian" 1047 "Sonic" 1051 "ProNav" 1053 "Vetus Maxwell INC." 1056 "Lithium Pros" 1059 "Boatrax" 1062 "Marol Co ltd" 1065 "CALYPSO Instruments" 1066 "Spot Zero Water" 1069 "Lithionics Battery" 1070 "Quick-teck Electronics" 1075 "Uniden America" 1083 "Nauticoncept" 1084 "Shadow-Caster LED lighting" 1085 "Wet Sounds" 1088 "E-T-A Circuit Breakers" 1092 "Scheiber" 1100 "Smart Yachts International Limited" 1109 "Dockmate" 1114 "Bobs Machine" 1118 "L3Harris ASV" 1119 "Balmar" 1120 "Elettromedia" 1127 "Electromaax" 1140 "Across Oceans Systems" 1145 "Kiwi Yachting" 1150 "BSB Artificial Intelligence" 1151 "Orca Technologies" 1154 "TBS Electronics" 1158 "Technoton Electroics" 1160 "MG Energy Systems" 1169 "Sea Machine Robotics" 1171 "Vista Manufacturing" 1183 "Zipwake" 1186 "Sailmon" 1192 "Airmoniq Pro Kft" 1194 "Sierra Marine" 1200 "Xinuo Information Technology (Xiamen)" 1218 "Septentrio" 1233 "NKE Marine Electronics" 1238 "SuperTrack Aps" 1239 "Honda Electronics" 1245 "Raritan Engineering" 1249 "Integrated Power Solutions AG" 1260 "Interactive Technologies" 1283 "LTG-Tech" 1299 "Energy Solutions (UK)" 1300 "WATT Fuel Cell" 1302 "Pro Mainer" 1305 "Dragonfly Energy" 1306 "Koden Electronics" 1311 "Humphree" 1316 "Hinkley Yachts" 1317 "Global Marine Management GmbH (GMM)" 1320 "Triskel Marine" 1330 "Warwick Control Technologies" 1331 "Dolphin Charger" 1337 "Barnacle Systems" 1348 "Radian IoT" 1353 "Ocean LED Marine" 1359 "BluNav" 1361 "OVA (Nantong Saiyang Electronics Co., Ltd)" 1368 "RAD Propulsion" 1369 "Electric Yacht" 1372 "Elco Motor Yachts" 1384 "Tecnoseal Foundry S.r.l" 1385 "Pro Charging Systems" 1389 "EVEX" 1398 "Gobius Sensor Technology" 1403 "Arco Marine" 1408 "Lenco Marine" 1413 "Naocontrol" 1417 "Revatek" 1438 "Aeolionics" 1439 "PredictWind" 1440 "Egis Mobile Electric" 1445 "Starboard Yacht Group" 1446 "Roswell Marine" 1451 "ePropulsion (Guangdong ePropulsion Technology Ltd.)" 1452 "Micro-Air" 1453 "Vital Battery" 1458 "Ride Controller" 1460 "Tocaro Blue" 1461 "Vanquish Yachts" 1471 "FT Technologies" 1478 "Alps Alpine" 1481 "E-Force Marine" 1482 "CMC Marine" 1483 "Nanjing Sandemarine Information Technology" 1850 "Teleflex Marine (SeaStar Solutions)" 1851 "Raymarine" 1852 "Navionics" 1853 "Japan Radio" 1854 "Northstar Technologies" 1855 "Furuno" 1856 "Trimble" 1857 "Simrad" 1858 "Litton" 1859 "Kvasar" 1860 "MMP" 1861 "Vector Cantech" 1862 "Yamaha Marine" 1863 "Faria Instruments" ;
VAL_ 2499742464 Industry_Code 0 "Global" 1 "Highway" 2 "Agriculture" 3 "Construction" 4 "Marine Industry" 5 "Industrial" ;
VAL_ 2566851584 Manufacturer_Code 69 "ARKS Enterprises" 78 "FW Murphy/Enovation Controls" 80 "Twin Disc" 85 "Kohler Power Systems" 88 "Hemisphere GPS" 135 "Airmar" 137 "Maretron" 140 "Lowrance" 144 "Mercury Marine" 147 "Nautibus Electronic" 148 "Blue Water Data" 154 "Westerbeke" 157 "ISSPRO" 161 "Offshore Systems (UK)" 163 "Evinrude/BRP" 165 "CPAC Systems" 168 "Xantrex Technology" 169 "Marlin Technologies" 172 "Yanmar Marine" 174 "Volvo Penta" 176 "Carling Technologies Inc. (Moritz Aerospace)" 185 "Beede Instruments" 192 "Floscan Instrument" 193 "Nobeltec" 198 "Mystic Valley Communications" 199 "Actia" 201 "Disenos Y Technologia" 211 "Digital Switching Systems" 215 "Xintex/Atena" 224 "EMMI NETWORK" 228 "ZF" 229 "Garmin" 233 "Yacht Monitoring Solutions" 235 "Sailormade Marine Telemetry/Tetra Technology" 243 "Eride" 257 "Honda Motor" 272 "Groco" 273 "Actisense" 274 "Amphenol LTW Technology" 275 "Navico" 283 "Hamilton Jet" 285 "Sea Recovery" 286 "Coelmo SRL Italy" 295 "BEP Marine" 304 "Empir Bus" 305 "NovAtel" 306 "Sleipner Motor" 307 "MBW Technologies" 315 "ICOM" 328 "Qwerty" 329 "Dief" 341 "Boening Automationstechnologie" 345 "Korean Maritime University" 351 "Thrane and Thrane" 355 "Mastervolt" 356 "Fischer Panda Generators" 358 "Victron Energy" 370 "Rolls Royce Marine" 373 "Electronic Design" 374 "Northern Lights" 378 "Glendinning" 381 "B & G" 384 "Rose Point Navigation Systems" 385 "Johnson Outdoors Marine Electronics Inc Geonav" 394 "Capi 2" 396 "Beyond Measure" 400 "Livorsi Marine" 404 "ComNav" 409 "Chetco" 419 "Fusion Electronics" 421 "Standard Horizon" 422 "True Heading" 426 "Egersund Marine Electronics" 427 "em-trak Marine Electronics" 431 "Tohatsu Co, JP" 437 "Digital Yacht" 438 "Comar Systems Limited" 440 "Cummins" 443 "VDO (aka Continental-Corporation)" 451 "Parker Hannifin aka Village Marine Tech" 459 "Alltek Marine Electronics" 460 "SAN GIORGIO S.E.I.N" 466 "Veethree Electronics & Marine" 470 "SI-TEX Marine Electronics" 471 "Sea Cross Marine" 475 "GME aka Standard Communications" 476 "Humminbird Marine Electronics" 478 "Ocean Sat" 481 "Chetco Digital Instruments" 493 "Watcheye" 499 "Lcj Capteurs" 502 "Attwood Marine" 503 "Naviop S.R.L." 504 "Vesper Marine" 510 "Marinesoft" 513 "Simarine" 517 "NoLand Engineering" 518 "Transas USA" 529 "National Instruments Korea" 530 "National Marine Electronics Association" 532 "Onwa Marine" 540 "Webasto" 571 "Marinecraft (South Korea)" 573 "McMurdo Group aka Orolia" 578 "Advansea" 579 "KVH" 580 "San Jose Technology" 583 "Yacht Control" 586 "Suzuki Motor" 591 "US Coast Guard" 595 "Ship Module aka Customware" 600 "Aquatic AV" 605 "Aventics" 606 "Intellian" 612 "SamwonIT" 614 "Arlt Tecnologies" 637 "Bavaria Yachts" 641 "Diverse Yacht Services" 644 "Wema U.S.A dba KUS" 658 "Shenzhen Jiuzhou Himunication" 688 "Rockford" 699 "Harman International" 704 "JL Audio" 708 "Lars Thrane" 715 "Autonnic" 717 "Yacht Devices" 734 "REAP Systems" 735 "AEM Performance Electronics" 739 "LxNav" 741 "Littelfuse, Inc (formerly Carling Technologies)" 743 "DaeMyung" 744 "Woosung" 748 "ISOTTA IFRA srl" 773 "Clarion US" 776 "HMI Systems" 777 "Ocean Signal" 778 "Seakeeper" 781 "Poly Planar" 785 "Fischer Panda DE" 795 "Broyda Industries" 796 "Canadian Automotive" 797 "Tides Marine" 798 "Lumishore" 799 "Still Water Designs and Audio" 802 "BJ Technologies (Beneteau)" 803 "Gill Sensors" 811 "Blue Water Desalination" 815 "FLIR" 824 "Undheim Systems" 826 "Lewmar" 838 "TeamSurv" 844 "Fell Marine" 847 "Oceanvolt" 862 "Prospec" 868 "Data Panel" 890 "L3 Technologies" 894 "Rhodan Marine Systems" 896 "Nexfour Solutions" 905 "ASA Electronics" 909 "Marines Co (South Korea)" 911 "Nautic-on" 917 "Sentinel" 929 "JL Marine Systems" 930 "Ecotronix" 944 "Zontisa Marine" 951 "EXOR International" 962 "Timbolier Industries" 963 "TJC Micro" 968 "Cox Powertrain" 969 "Blue Seas" 981 "Kobelt Manufacturing" 992 "Blue Ocean IOT" 997 "Xenta Systems" 999 "Signal K" 1004 "Ultraflex" 1008 "Lintest SmartBoat" 1011 "Soundmax" 1020 "Team Italia Marine (Onyx Marine Automation s.r.l)" 1021 "Entratech" 1022 "ITC" 1029 "The Marine Guardian" 1047 "Sonic" 1051 "ProNav" 1053 "Vetus Maxwell INC." 1056 "Lithium Pros" 1059 "Boatrax" 1062 "Marol Co ltd" 1065 "CALYPSO Instruments" 1066 "Spot Zero Water" 1069 "Lithionics Battery" 1070 "Quick-teck Electronics" 1075 "Uniden America" 1083 "Nauticoncept" 1084 "Shadow-Caster LED lighting" 1085 "Wet Sounds" 1088 "E-T-A Circuit Breakers" 1092 "Scheiber" 1100 "Smart Yachts International Limited" 1109 "Dockmate" 1114 "Bobs Machine" 1118 "L3Harris ASV" 1119 "Balmar" 1120 "Elettromedia" 1127 "Electromaax" 1140 "Across Oceans Systems" 1145 "Kiwi Yachting" 1150 "BSB Artificial Intelligence" 1151 "Orca Technologies" 1154 "TBS Electronics" 1158 "Technoton Electroics" 1160 "MG Energy Systems" 1169 "Sea Machine Robotics" 1171 "Vista Manufacturing" 1183 "Zipwake" 1186 "Sailmon" 1192 "Airmoniq Pro Kft" 1194 "Sierra Marine" 1200 "Xinuo Information Technology (Xiamen)" 1218 "Septentrio" 1233 "NKE Marine Electronics" 1238 "SuperTrack Aps" 1239 "Honda Electronics" 1245 "Raritan Engineering" 1249 "Integrated Power Solutions AG" 1260 "Interactive Technologies" 1283 "LTG-Tech" 1299 "Energy Solutions (UK)" 1300 "WATT Fuel Cell" 1302 "Pro Mainer" 1305 "Dragonfly Energy" 1306 "Koden Electronics" 1311 "Humphree" 1316 "Hinkley Yachts" 1317 "Global Marine Management GmbH (GMM)" 1320 "Triskel Marine" 1330 "Warwick Control Technologies" 1331 "Dolphin Charger" 1337 "Barnacle Systems" 1348 "Radian IoT" 1353 "Ocean LED Marine" 1359 "BluNav" 1361 "OVA (Nantong Saiyang Electronics Co., Ltd)" 1368 "RAD Propulsion" 1369 "Electric Yacht" 1372 "Elco Motor Yachts" 1384 "Tecnoseal Foundry S.r.l" 1385 "Pro Charging Systems" 1389 "EVEX" 1398 "Gobius Sensor Technology" 1403 "Arco Marine" 1408 "Lenco Marine" 1413 "Naocontrol" 1417 "Revatek" 1438 "Aeolionics" 1439 "PredictWind" 1440 "Egis Mobile Electric" 1445 "Starboard Yacht Group" 1446 "Roswell Marine" 1451 "ePropulsion (Guangdong ePropulsion Technology Ltd.)" 1452 "Micro-Air" 1453 "Vital Battery" 1458 "Ride Controller" 1460 "Tocaro Blue" 1461 "Vanquish Yachts" 1471 "FT Technologies" 1478 "Alps Alpine" 1481 "E-Force Marine" 1482 "CMC Marine" 1483 "Nanjing Sandemarine Information Technology" 1850 "Teleflex Marine (SeaStar Solutions)" 1851 "Raymarine" 1852 "Navionics" 1853 "Japan Radio" 1854 "Northstar Technologies" 1855 "Furuno" 1856 "Trimble" 1857 "Simrad" 1858 "Litton" 1859 "Kvasar" 1860 "MMP" 1861 "Vector Cantech" 1862 "Yamaha Marine" 1863 "Faria Instruments" ;
VAL_ 2566851584 Industry_Code 0 "Global" 1 "Highway" 2 "Agriculture" 3 "Construction" 4 "Marine Industry" 5 "Industrial" ;
VAL_ 2566851584 Manufacturer_Code 69 "ARKS Enterprises" 78 "FW Murphy/Enovation Controls" 80 "Twin Disc" 85 "Kohler Power Systems" 88 "Hemisphere GPS" 135 "Airmar" 137 "Maretron" 140 "Lowrance" 144 "Mercury Marine" 147 "Nautibus Electronic" 148 "Blue Water Data" 154 "Westerbeke" 157 "ISSPRO" 161 "Offshore Systems (UK)" 163 "Evinrude/BRP" 165 "CPAC Systems" 168 "Xantrex Technology" 169 "Marlin Technologies" 172 "Yanmar Marine" 174 "Volvo Penta" 176 "Carling Technologies Inc. (Moritz Aerospace)" 185 "Beede Instruments" 192 "Floscan Instrument" 193 "Nobeltec" 198 "Mystic Valley Communications" 199 "Actia" 201 "Disenos Y Technologia" 211 "Digital Switching Systems" 215 "Xintex/Atena" 224 "EMMI NETWORK" 228 "ZF" 229 "Garmin" 233 "Yacht Monitoring Solutions" 235 "Sailormade Marine Telemetry/Tetra Technology" 243 "Eride" 257 "Honda Motor" 272 "Groco" 273 "Actisense" 274 "Amphenol LTW Technology" 275 "Navico" 283 "Hamilton Jet" 285 "Sea Recovery" 286 "Coelmo SRL Italy" 295 "BEP Marine" 304 "Empir Bus" 305 "NovAtel" 306 "Sleipner Motor" 307 "MBW Technologies" 315 "ICOM" 328 "Qwerty" 329 "Dief" 341 "Boening Automationstechnologie" 345 "Korean Maritime University" 351 "Thrane and Thrane" 355 "Mastervolt" 356 "Fischer Panda Generators" 358 "Victron Energy" 370 "Rolls Royce Marine" 373 "Electronic Design" 374 "Northern Lights" 378 "Glendinning" 381 "B & G" 384 "Rose Point Navigation Systems" 385 "Johnson Outdoors Marine Electronics Inc Geonav" 394 "Capi 2" 396 "Beyond Measure" 400 "Livorsi Marine" 404 "ComNav" 409 "Chetco" 419 "Fusion Electronics" 421 "Standard Horizon" 422 "True Heading" 426 "Egersund Marine Electronics" 427 "em-trak Marine Electronics" 431 "Tohatsu Co, JP" 437 "Digital Yacht" 438 "Comar Systems Limited" 440 "Cummins" 443 "VDO (aka Continental-Corporation)" 451 "Parker Hannifin aka Village Marine Tech" 459 "Alltek Marine Electronics" 460 "SAN GIORGIO S.E.I.N" 466 "Veethree Electronics & Marine" 470 "SI-TEX Marine Electronics" 471 "Sea Cross Marine" 475 "GME aka Standard Communications" 476 "Humminbird Marine Electronics" 478 "Ocean Sat" 481 "Chetco Digital Instruments" 493 "Watcheye" 499 "Lcj Capteurs" 502 "Attwood Marine" 503 "Naviop S.R.L." 504 "Vesper Marine" 510 "Marinesoft" 513 "Simarine" 517 "NoLand Engineering" 518 "Transas USA" 529 "National Instruments Korea" 530 "National Marine Electronics Association" 532 "Onwa Marine" 540 "Webasto" 571 "Marinecraft (South Korea)" 573 "McMurdo Group aka Orolia" 578 "Advansea" 579 "KVH" 580 "San Jose Technology" 583 "Yacht Control" 586 "Suzuki Motor" 591 "US Coast Guard" 595 "Ship Module aka Customware" 600 "Aquatic AV" 605 "Aventics" 606 "Intellian" 612 "SamwonIT" 614 "Arlt Tecnologies" 637 "Bavaria Yachts" 641 "Diverse Yacht Services" 644 "Wema U.S.A dba KUS" 658 "Shenzhen Jiuzhou Himunication" 688 "Rockford" 699 "Harman International" 704 "JL Audio" 708 "Lars Thrane" 715 "Autonnic" 717 "Yacht Devices" 734 "REAP Systems" 735 "AEM Performance Electronics" 739 "LxNav" 741 "Littelfuse, Inc (formerly Carling Technologies)" 743 "DaeMyung" 744 "Woosung" 748 "ISOTTA IFRA srl" 773 "Clarion US" 776 "HMI Systems" 777 "Ocean Signal" 778 "Seakeeper" 781 "Poly Planar" 785 "Fischer Panda DE" 795 "Broyda Industries" 796 "Canadian Automotive" 797 "Tides Marine" 798 "Lumishore" 799 "Still Water Designs and Audio" 802 "BJ Technologies (Beneteau)" 803 "Gill Sensors" 811 "Blue Water Desalination" 815 "FLIR" 824 "Undheim Systems" 826 "Lewmar" 838 "TeamSurv" 844 "Fell Marine" 847 "Oceanvolt" 862 "Prospec" 868 "Data Panel" 890 "L3 Technologies" 894 "Rhodan Marine Systems" 896 "Nexfour Solutions" 905 "ASA Electronics" 909 "Marines Co (South Korea)" 911 "Nautic-on" 917 "Sentinel" 929 "JL Marine Systems" 930 "Ecotronix" 944 "Zontisa Marine" 951 "EXOR International" 962 "Timbolier Industries" 963 "TJC Micro" 968 "Cox Powertrain" 969 "Blue Seas" 981 "Kobelt Manufacturing" 992 "Blue Ocean IOT" 997 "Xenta Systems" 999 "Signal K" 1004 "Ultraflex" 1008 "Lintest SmartBoat" 1011 "Soundmax" 1020 "Team Italia Marine (Onyx Marine Automation s.r.l)" 1021 "Entratech" 1022 "ITC" 1029 "The Marine Guardian" 1047 "Sonic" 1051 "ProNav" 1053 "Vetus Maxwell INC." 1056 "Lithium Pros" 1059 "Boatrax" 1062 "Marol Co ltd" 1065 "CALYPSO Instruments" 1066 "Spot Zero Water" 1069 "Lithionics Battery" 1070 "Quick-teck Electronics" 1075 "Uniden America" 1083 "Nauticoncept" 1084 "Shadow-Caster LED lighting" 1085 "Wet Sounds" 1088 "E-T-A Circuit Breakers" 1092 "Scheiber" 1100 "Smart Yachts International Limited" 1109 "Dockmate" 1114 "Bobs Machine" 1118 "L3Harris ASV" 1119 "Balmar" 1120 "Elettromedia" 1127 "Electromaax" 1140 "Across Oceans Systems" 1145 "Kiwi Yachting" 1150 "BSB Artificial Intelligence" 1151 "Orca Technologies" 1154 "TBS Electronics" 1158 "Technoton Electroics" 1160 "MG Energy Systems" 1169 "Sea Machine Robotics" 1171 "Vista Manufacturing" 1183 "Zipwake" 1186 "Sailmon" 1192 "Airmoniq Pro Kft" 1194 "Sierra Marine" 1200 "Xinuo Information Technology (Xiamen)" 1218 "Septentrio" 1233 "NKE Marine Electronics" 1238 "SuperTrack Aps" 1239 "Honda Electronics" 1245 "Raritan Engineering" 1249 "Integrated Power Solutions AG" 1260 "Interactive Technologies" 1283 "LTG-Tech" 1299 "Energy Solutions (UK)" 1300 "WATT Fuel Cell" 1302 "Pro Mainer" 1305 "Dragonfly Energy" 1306 "Koden Electronics" 1311 "Humphree" 1316 "Hinkley Yachts" 1317 "Global Marine Management GmbH (GMM)" 1320 "Triskel Marine" 1330 "Warwick Control Technologies" 1331 "Dolphin Charger" 1337 "Barnacle Systems" 1348 "Radian IoT" 1353 "Ocean LED Marine" 1359 "BluNav" 1361 "OVA (Nantong Saiyang Electronics Co., Ltd)" 1368 "RAD Propulsion" 1369 "Electric Yacht" 1372 "Elco Motor Yachts" 1384 "Tecnoseal Foundry S.r.l" 1385 "Pro Charging Systems" 1389 "EVEX" 1398 "Gobius Sensor Technology" 1403 "Arco Marine" 1408 "Lenco Marine" 1413 "Naocontrol" 1417 "Revatek" 1438 "Aeolionics" 1439 "PredictWind" 1440 "Egis Mobile Electric" 1445 "Starboard Yacht Group" 1446 "Roswell Marine" 1451 "ePropulsion (Guangdong ePropulsion Technology Ltd.)" 1452 "Micro-Air" 1453 "Vital Battery" 1458 "Ride Controller" 1460 "Tocaro Blue" 1461 "Vanquish Yachts" 1471 "FT Technologies" 1478 "Alps Alpine" 1481 "E-Force Marine" 1482 "CMC Marine" 1483 "Nanjing Sandemarine Information Technology" 1850 "Teleflex Marine (SeaStar Solutions)" 1851 "Raymarine" 1852 "Navionics" 1853 "Japan Radio" 1854 "Northstar Technologies" 1855 "Furuno" 1856 "Trimble" 1857 "Simrad" 1858 "Litton" 1859 "Kvasar" 1860 "MMP" 1861 "Vector Cantech" 1862 "Yamaha Marine" 1863 "Faria Instruments" ;
VAL_ 2566851584 Industry_Code 0 "Global" 1 "Highway" 2 "Agriculture" 3 "Construction" 4 "Marine Industry" 5 "Industrial" ;
VAL_ 2298416384 Manufacturer_Code 69 "ARKS Enterprises" 78 "FW Murphy/Enovation Controls" 80 "Twin Disc" 85 "Kohler Power Systems" 88 "Hemisphere GPS" 135 "Airmar" 137 "Maretron" 140 "Lowrance" 144 "Mercury Marine" 147 "Nautibus Electronic" 148 "Blue Water Data" 154 "Westerbeke" 157 "ISSPRO" 161 "Offshore Systems (UK)" 163 "Evinrude/BRP" 165 "CPAC Systems" 168 "Xantrex Technology" 169 "Marlin Technologies" 172 "Yanmar Marine" 174 "Volvo Penta" 176 "Carling Technologies Inc. (Moritz Aerospace)" 185 "Beede Instruments" 192 "Floscan Instrument" 193 "Nobeltec" 198 "Mystic Valley Communications" 199 "Actia" 201 "Disenos Y Technologia" 211 "Digital Switching Systems" 215 "Xintex/Atena" 224 "EMMI NETWORK" 228 "ZF" 229 "Garmin" 233 "Yacht Monitoring Solutions" 235 "Sailormade Marine Telemetry/Tetra Technology" 243 "Eride" 257 "Honda Motor" 272 "Groco" 273 "Actisense" 274 "Amphenol LTW Technology" 275 "Navico" 283 "Hamilton Jet" 285 "Sea Recovery" 286 "Coelmo SRL Italy" 295 "BEP Marine" 304 "Empir Bus" 305 "NovAtel" 306 "Sleipner Motor" 307 "MBW Technologies" 315 "ICOM" 328 "Qwerty" 329 "Dief" 341 "Boening Automationstechnologie" 345 "Korean Maritime University" 351 "Thrane and Thrane" 355 "Mastervolt" 356 "Fischer Panda Generators" 358 "Victron Energy" 370 "Rolls Royce Marine" 373 "Electronic Design" 374 "Northern Lights" 378 "Glendinning" 381 "B & G" 384 "Rose Point Navigation Systems" 385 "Johnson Outdoors Marine Electronics Inc Geonav" 394 "Capi 2" 396 "Beyond Measure" 400 "Livorsi Marine" 404 "ComNav" 409 "Chetco" 419 "Fusion Electronics" 421 "Standard Horizon" 422 "True Heading" 426 "Egersund Marine Electronics" 427 "em-trak Marine Electronics" 431 "Tohatsu Co, JP" 437 "Digital Yacht" 438 "Comar Systems Limited" 440 "Cummins" 443 "VDO (aka Continental-Corporation)" 451 "Parker Hannifin aka Village Marine Tech" 459 "Alltek Marine Electronics" 460 "SAN GIORGIO S.E.I.N" 466 "Veethree Electronics & Marine" 470 "SI-TEX Marine Electronics" 471 "Sea Cross Marine" 475 "GME aka Standard Communications" 476 "Humminbird Marine Electronics" 478 "Ocean Sat" 481 "Chetco Digital Instruments" 493 "Watcheye" 499 "Lcj Capteurs" 502 "Attwood Marine" 503 "Naviop S.R.L." 504 "Vesper Marine" 510 "Marinesoft" 513 "Simarine" 517 "NoLand Engineering" 518 "Transas USA" 529 "National Instruments Korea" 530 "National Marine Electronics Association" 532 "Onwa Marine" 540 "Webasto" 571 "Marinecraft (South Korea)" 573 "McMurdo Group aka Orolia" 578 "Advansea" 579 "KVH" 580 "San Jose Technology" 583 "Yacht Control" 586 "Suzuki Motor" 591 "US Coast Guard" 595 "Ship Module aka Customware" 600 "Aquatic AV" 605 "Aventics" 606 "Intellian" 612 "SamwonIT" 614 "Arlt Tecnologies" 637 "Bavaria Yachts" 641 "Diverse Yacht Services" 644 "Wema U.S.A dba KUS" 658 "Shenzhen Jiuzhou Himunication" 688 "Rockford" 699 "Harman International" 704 "JL Audio" 708 "Lars Thrane" 715 "Autonnic" 717 "Yacht Devices" 734 "REAP Systems" 735 "AEM Performance Electronics" 739 "LxNav" 741 "Littelfuse, Inc (formerly Carling Technologies)" 743 "DaeMyung" 744 "Woosung" 748 "ISOTTA IFRA srl" 773 "Clarion US" 776 "HMI Systems" 777 "Ocean Signal" 778 "Seakeeper" 781 "Poly Planar" 785 "Fischer Panda DE" 795 "Broyda Industries" 796 "Canadian Automotive" 797 "Tides Marine" 798 "Lumishore" 799 "Still Water Designs and Audio" 802 "BJ Technologies (Beneteau)" 803 "Gill Sensors" 811 "Blue Water Desalination" 815 "FLIR" 824 "Undheim Systems" 826 "Lewmar" 838 "TeamSurv" 844 "Fell Marine" 847 "Oceanvolt" 862 "Prospec" 868 "Data Panel" 890 "L3 Technologies" 894 "Rhodan Marine Systems" 896 "Nexfour Solutions" 905 "ASA Electronics" 909 "Marines Co (South Korea)" 911 "Nautic-on" 917 "Sentinel" 929 "JL Marine Systems" 930 "Ecotronix" 944 "Zontisa Marine" 951 "EXOR International" 962 "Timbolier Industries" 963 "TJC Micro" 968 "Cox Powertrain" 969 "Blue Seas" 981 "Kobelt Manufacturing" 992 "Blue Ocean IOT" 997 "Xenta Systems" 999 "Signal K" 1004 "Ultraflex" 1008 "Lintest SmartBoat" 1011 "Soundmax" 1020 "Team Italia Marine (Onyx Marine Automation s.r.l)" 1021 "Entratech" 1022 "ITC" 1029 "The Marine Guardian" 1047 "Sonic" 1051 "ProNav" 1053 "Vetus Maxwell INC." 1056 "Lithium Pros" 1059 "Boatrax" 1062 "Marol Co ltd" 1065 "CALYPSO Instruments" 1066 "Spot Zero Water" 1069 "Lithionics Battery" 1070 "Quick-teck Electronics" 1075 "Uniden America" 1083 "Nauticoncept" 1084 "Shadow-Caster LED lighting" 1085 "Wet Sounds" 1088 "E-T-A Circuit Breakers" 1092 "Scheiber" 1100 "Smart Yachts International Limited" 1109 "Dockmate" 1114 "Bobs Machine" 1118 "L3Harris ASV" 1119 "Balmar" 1120 "Elettromedia" 1127 "Electromaax" 1140 "Across Oceans Systems" 1145 "Kiwi Yachting" 1150 "BSB Artificial Intelligence" 1151 "Orca Technologies" 1154 "TBS Electronics" 1158 "Technoton Electroics" 1160 "MG Energy Systems" 1169 "Sea Machine Robotics" 1171 "Vista Manufacturing" 1183 "Zipwake" 1186 "Sailmon" 1192 "Airmoniq Pro Kft" 1194 "Sierra Marine" 1200 "Xinuo Information Technology (Xiamen)" 1218 "Septentrio" 1233 "NKE Marine Electronics" 1238 "SuperTrack Aps" 1239 "Honda Electronics" 1245 "Raritan Engineering" 1249 "Integrated Power Solutions AG" 1260 "Interactive Technologies" 1283 "LTG-Tech" 1299 "Energy Solutions (UK)" 1300 "WATT Fuel Cell" 1302 "Pro Mainer" 1305 "Dragonfly Energy" 1306 "Koden Electronics" 1311 "Humphree" 1316 "Hinkley Yachts" 1317 "Global Marine Management GmbH (GMM)" 1320 "Triskel Marine" 1330 "Warwick Control Technologies" 1331 "Dolphin Charger" 1337 "Barnacle Systems" 1348 "Radian IoT" 1353 "Ocean LED Marine" 1359 "BluNav" 1361 "OVA (Nantong Saiyang Electronics Co., Ltd)" 1368 "RAD Propulsion" 1369 "Electric Yacht" 1372 "Elco Motor Yachts" 1384 "Tecnoseal Foundry S.r.l" 1385 "Pro Charging Systems" 1389 "EVEX" 1398 "Gobius Sensor Technology" 1403 "Arco Marine" 1408 "Lenco Marine" 1413 "Naocontrol" 1417 "Revatek" 1438 "Aeolionics" 1439 "PredictWind" 1440 "Egis Mobile Electric" 1445 "Starboard Yacht Group" 1446 "Roswell Marine" 1451 "ePropulsion (Guangdong ePropulsion Technology Ltd.)" 1452 "Micro-Air" 1453 "Vital Battery" 1458 "Ride Controller" 1460 "Tocaro Blue" 1461 "Vanquish Yachts" 1471 "FT Technologies" 1478 "Alps Alpine" 1481 "E-Force Marine" 1482 "CMC Marine" 1483 "Nanjing Sandemarine Information Technology" 1850 "Teleflex Marine (SeaStar Solutions)" 1851 "Raymarine" 1852 "Navionics" 1853 "Japan Radio" 1854 "Northstar Technologies" 1855 "Furuno" 1856 "Trimble" 1857 "Simrad" 1858 "Litton" 1859 "Kvasar" 1860 "MMP" 1861 "Vector Cantech" 1862 "Yamaha Marine" 1863 "Faria Instruments" ;
VAL_ 2298416384 Industry_Code 0 "Global" 1 "Highway" 2 "Agriculture" 3 "Construction" 4 "Marine Industry" 5 "Industrial" ;

BA_DEF_ BO_ "GenMsgCycleTime" INT 0 60000;
BA_DEF_ BO_ "ProtocolType" STRING;

BA_DEF_ BO_ "J1939PGN" INT 0 262143;
BA_ "J1939PGN" BO_ 2566849280 65283;
BA_ "J1939PGN" BO_ 2566849536 65284;
BA_ "J1939PGN" BO_ 2566849536 65284;
BA_ "J1939PGN" BO_ 2566849536 65284;
BA_ "J1939PGN" BO_ 2298414080 65284;
BA_ "J1939PGN" BO_ 2499740928 65285;
BA_ "J1939PGN" BO_ 2566849792 65285;
BA_ "J1939PGN" BO_ 2566849792 65285;
BA_ "J1939PGN" BO_ 2566850048 65286;
BA_ "J1939PGN" BO_ 2566850048 65286;
BA_ "J1939PGN" BO_ 2499741184 65286;
BA_ "J1939PGN" BO_ 2566850304 65287;
BA_ "J1939PGN" BO_ 2499741440 65287;
BA_ "J1939PGN" BO_ 2566850304 65287;
BA_ "J1939PGN" BO_ 2499741696 65288;
BA_ "J1939PGN" BO_ 2633959424 65288;
BA_ "J1939PGN" BO_ 2499741952 65289;
BA_ "J1939PGN" BO_ 2566850816 65289;
BA_ "J1939PGN" BO_ 2566851072 65290;
BA_ "J1939PGN" BO_ 2499742208 65290;
BA_ "J1939PGN" BO_ 2566851072 65290;
BA_ "J1939PGN" BO_ 2499742464 65291;
BA_ "J1939PGN" BO_ 2566851584 65292;
BA_ "J1939PGN" BO_ 2566851584 65292;
BA_ "J1939PGN" BO_ 2298416384 65293;
